VERSION ""

NS_ :

BS_:

BU_: BCM BSM DASM DIAG_TEST ESM ETM EVCU IPC LTM ORC SGW TBM

BO_ 599 AIRBAG1: 8 ORC
 SG_ AirBagFailSts : 7|2@0+ (1,0) [0|3] "-" IPC,TBM
 SG_ PsngrBagChargeSts : 5|2@0+ (1,0) [0|2] "-" IPC,TBM
 SG_ SBR1RowCentralSeatBuckleFailSts : 0|2@0+ (1,0) [0|2] "" IPC
 SG_ SBR1RowCentralSeatConfigSts : 1|1@0+ (1,0) [0|1] "-" IPC
 SG_ SBR1RowCentralSeatPPDFailSts : 14|2@0+ (1,0) [0|2] "" IPC
 SG_ SBR1RowCentralSeatSts : 12|3@0+ (1,0) [0|6] "-" IPC
 SG_ SBR1RowDriverSeatConfigSts : 9|1@0+ (1,0) [0|1] "-" IPC
 SG_ SBR1RowDriverSeatFailSts : 8|2@0+ (1,0) [0|2] "" EVCU,IPC
 SG_ SBR1RowDriverSeatSts : 22|2@0+ (1,0) [0|2] "-" EVCU,IPC,TBM
 SG_ SBR1RowPsngrSeatBuckleFailSts : 19|2@0+ (1,0) [0|2] "" IPC
 SG_ SBR1RowPsngrSeatConfigSts : 20|1@0+ (1,0) [0|1] "-" IPC
 SG_ SBR1RowPsngrSeatPPDFailSts : 17|2@0+ (1,0) [0|2] "" IPC
 SG_ SBR1RowPsngrSeatSts : 31|3@0+ (1,0) [0|6] "-" IPC,TBM
 SG_ SBR2RowCentralSeatConfigSts : 28|1@0+ (1,0) [0|1] "-" IPC
 SG_ SBR2RowCentralSeatSts : 25|2@0+ (1,0) [0|2] "-" IPC,TBM
 SG_ SBR2RowLeftSeatConfigSts : 39|1@0+ (1,0) [0|1] "-" IPC
 SG_ SBR2RowLeftSeatSts : 36|2@0+ (1,0) [0|2] "-" IPC,TBM
 SG_ SBR2RowRightSeatConfigSts : 34|1@0+ (1,0) [0|1] "-" IPC
 SG_ SBR2RowRightSeatSts : 47|2@0+ (1,0) [0|2] "-" IPC,TBM

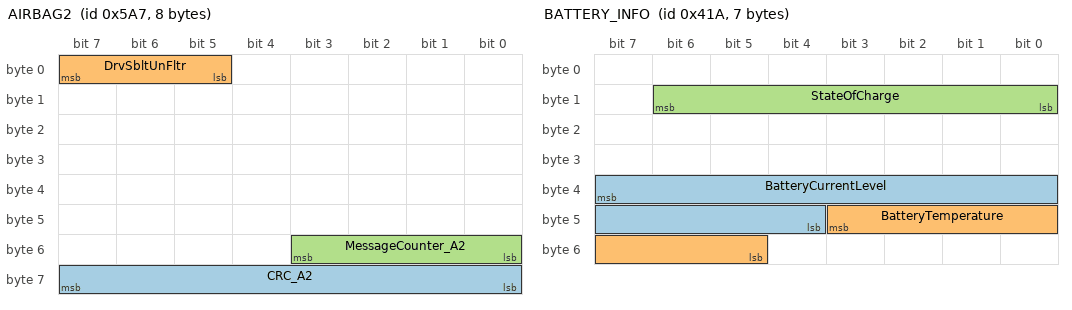
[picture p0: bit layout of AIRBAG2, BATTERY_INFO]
BO_ 1447 AIRBAG2: 8 ORC
 SG_ CRC_A2 : 63|8@0+ (1,0) [0|255] "" BSM
 SG_ DrvSbltUnFltr : 7|3@0+ (1,0) [0|6] "" BSM
 SG_ MessageCounter_A2 : 51|4@0+ (1,0) [0|15] "" BSM

BO_ 1050 BATTERY_INFO: 7 BCM
 SG_ BatteryCurrentLevel : 39|12@0+ (0.1,-250) [-250|159.5] "A" Vector__XXX
 SG_ BatteryTemperature : 43|7@0+ (1,-30) [-30|97] "°C" Vector__XXX
 SG_ StateOfCharge : 14|7@0+ (1,0) [0|127] "%" TBM

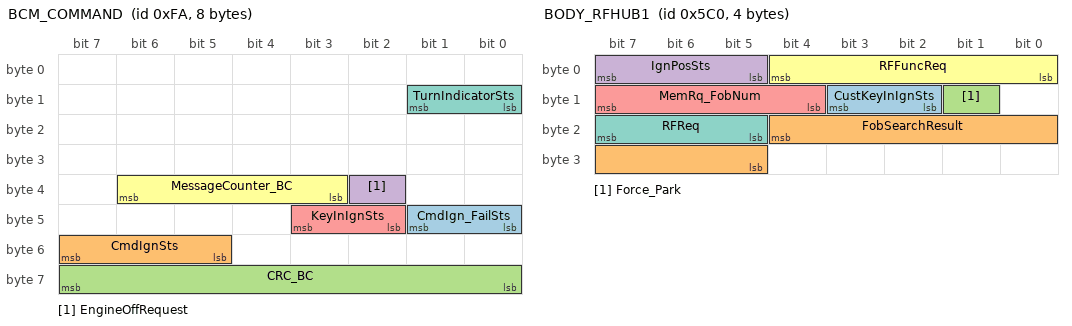
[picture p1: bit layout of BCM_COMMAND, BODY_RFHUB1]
BO_ 250 BCM_COMMAND: 8 BCM
 SG_ CmdIgn_FailSts : 41|2@0+ (1,0) [0|3] "-" BSM,DASM,ESM,EVCU,IPC
 SG_ CmdIgnSts : 55|3@0+ (1,0) [0|7] "-" BSM,DASM,ESM,EVCU,IPC
 SG_ CRC_BC : 63|8@0+ (1,0) [0|255] "" BSM,DASM,ESM,EVCU
 SG_ EngineOffRequest : 34|1@0+ (1,0) [0|1] "-" EVCU
 SG_ KeyInIgnSts : 43|2@0+ (1,0) [0|2] "" EVCU,TBM
 SG_ MessageCounter_BC : 38|4@0+ (1,0) [0|15] "-" BSM,DASM,ESM,EVCU
 SG_ TurnIndicatorSts : 9|2@0+ (1,0) [0|3] "-" IPC,TBM

BO_ 1994 BCM_IGNITION_ON_COUNTER: 2 BCM
 SG_ IgnitionOnCounter : 7|16@0+ (1,0) [0|65535] "-" DASM,ESM,EVCU,IPC,SGW,TBM

BO_ 1444 BH_IGW2: 8 BCM
 SG_ AirHtwPwrTgt : 11|8@0+ (1,0) [0|254] "%" EVCU
 SG_ PreCondCabinSts : 43|2@0+ (1,0) [0|3] "" EVCU

BO_ 1200 BH_IGW3: 8 BCM
 SG_ ChargeNow : 5|1@0+ (1,0) [0|1] "" EVCU
 SG_ ChargeNow_TBM : 58|1@0+ (1,0) [0|1] "" EVCU

BO_ 1472 BODY_RFHUB1: 4 BCM
 SG_ CustKeyInIgnSts : 11|2@0+ (1,0) [0|2] "" TBM
 SG_ FobSearchResult : 20|8@0+ (1,0) [0|255] "-" Vector__XXX
 SG_ Force_Park : 9|1@0+ (1,0) [0|1] "" EVCU
 SG_ IgnPosSts : 7|3@0+ (1,0) [0|6] "" TBM
 SG_ MemRq_FobNum : 15|4@0+ (1,0) [0|14] "" Vector__XXX
 SG_ RFFuncReq : 4|5@0+ (1,0) [0|30] "" TBM
 SG_ RFReq : 23|3@0+ (1,0) [0|6] "" TBM

BO_ 748 BODY1: 8 BCM
 SG_ AVASFailSts : 34|3@0+ (1,0) [0|7] "" IPC
 SG_ FrontWiperMoveSts : 21|1@0+ (1,0) [0|1] "" BSM,IPC,TBM

BO_ 1470 BODY10: 8 BCM
 SG_ LockUnlockVehicleSts : 5|3@0+ (1,0) [0|7] "" EVCU

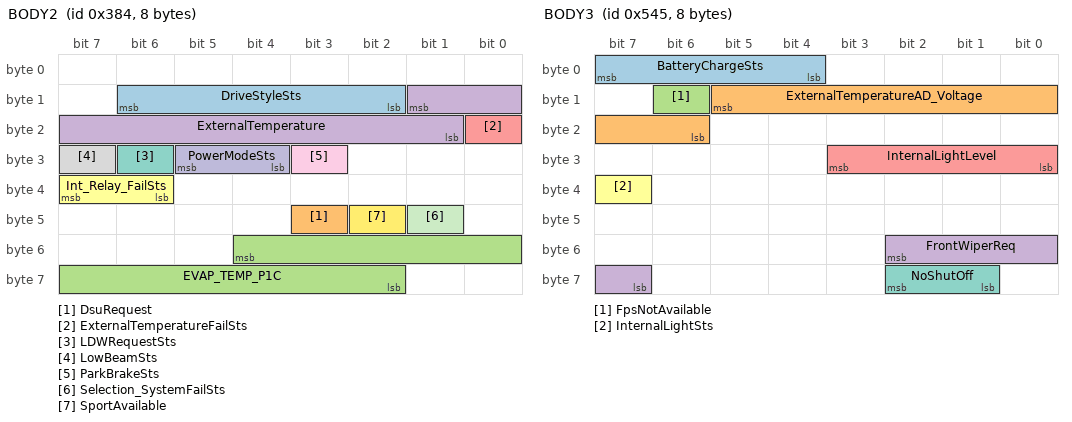
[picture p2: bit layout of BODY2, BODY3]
BO_ 900 BODY2: 8 BCM
 SG_ DriveStyleSts : 14|5@0+ (1,0) [0|31] "-" EVCU,IPC,TBM
 SG_ DsuRequest : 43|1@0+ (1,0) [0|1] "" IPC
 SG_ EVAP_TEMP_P1C : 52|11@0+ (0.1,-40) [-40|85] "°C" EVCU
 SG_ ExternalTemperature : 9|9@0+ (0.5,-85) [-85|170] "°C" BSM,DASM
 SG_ ExternalTemperatureFailSts : 16|1@0+ (1,0) [0|1] "" BSM,DASM
 SG_ Int_Relay_FailSts : 39|2@0+ (1,0) [0|2] "" Vector__XXX
 SG_ LDWRequestSts : 30|1@0+ (1,0) [0|1] "-" IPC
 SG_ LowBeamSts : 31|1@0+ (1,0) [0|1] "" TBM
 SG_ ParkBrakeSts : 27|1@0+ (1,0) [0|1] "-" EVCU,TBM
 SG_ PowerModeSts : 29|2@0+ (1,0) [0|3] "-" BSM,EVCU,IPC
 SG_ Selection_SystemFailSts : 41|1@0+ (1,0) [0|1] "" IPC
 SG_ SportAvailable : 42|1@0+ (1,0) [0|1] "" IPC

BO_ 1349 BODY3: 8 BCM
 SG_ BatteryChargeSts : 7|4@0+ (5,40) [40|110] "%" TBM
 SG_ ExternalTemperatureAD_Voltage : 13|8@0+ (0.019607843,0) [0|4.999999965] "Volt" EVCU
 SG_ FpsNotAvailable : 14|1@0+ (1,0) [0|1] "" Vector__XXX
 SG_ FrontWiperReq : 50|4@0+ (1,0) [0|5] "" IPC,TBM
 SG_ InternalLightLevel : 27|4@0+ (1,0) [0|15] "-" ESM,TBM
 SG_ InternalLightSts : 39|1@0+ (1,0) [0|1] "-" BSM,ESM,EVCU,IPC,ORC,TBM
 SG_ NoShutOff : 58|2@0+ (1,0) [0|2] "" IPC

BO_ 1201 BODY4: 8 BCM
 SG_ BonnetFailSts : 5|1@0+ (1,0) [0|1] "-" Vector__XXX
 SG_ BonnetSts : 4|1@0+ (1,0) [0|1] "" EVCU,TBM
 SG_ BrakeFluidLevelSts : 7|1@0+ (1,0) [0|1] "" IPC,TBM
 SG_ CompressorACReqSts : 37|1@0+ (1,0) [0|1] "-" EVCU
 SG_ DriverDoorFailSts : 3|1@0+ (1,0) [0|1] "-" BSM,EVCU
 SG_ DriverDoorSts : 0|1@0+ (1,0) [0|1] "" BSM,EVCU,IPC,TBM
 SG_ ExteriorRearReleaseSwitchSts : 33|1@0+ (1,0) [0|1] "" TBM
 SG_ FHeatedWindowLoadSts : 10|1@0+ (1,0) [0|1] "" Vector__XXX
 SG_ LHRDoorSts : 14|1@0+ (1,0) [0|1] "-" TBM
 SG_ PreCond_InhibitSts : 61|5@0+ (1,0) [0|30] "" IPC
 SG_ PreCondActvSts : 56|1@0+ (1,0) [0|1] "" IPC
 SG_ PsngrDoorSts : 15|1@0+ (1,0) [0|1] "-" TBM
 SG_ RemSt_InhibitSts : 19|6@0+ (1,0) [0|62] "" IPC,TBM
 SG_ RemStActvSts : 29|1@0+ (1,0) [0|1] "" EVCU,IPC,ORC
 SG_ RHatchSts : 12|1@0+ (1,0) [0|1] "-" TBM
 SG_ RHeatedWindowLoadSts : 11|1@0+ (1,0) [0|1] "" Vector__XXX
 SG_ RHRDoorSts : 13|1@0+ (1,0) [0|1] "-" TBM
 SG_ TheftAlarmStatus : 22|3@0+ (1,0) [0|6] "" TBM

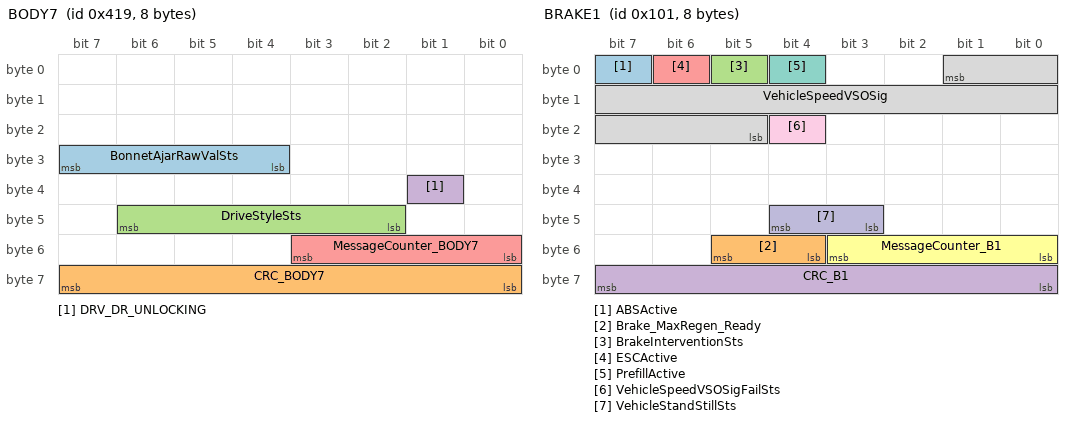
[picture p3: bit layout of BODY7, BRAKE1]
BO_ 1049 BODY7: 8 BCM
 SG_ BonnetAjarRawValSts : 31|4@0+ (1,0) [0|15] "" EVCU
 SG_ CRC_BODY7 : 63|8@0+ (1,0) [0|255] "" EVCU
 SG_ DriveStyleSts : 46|5@0+ (1,0) [0|31] "" EVCU
 SG_ DRV_DR_UNLOCKING : 33|1@0+ (1,0) [0|1] "-" EVCU
 SG_ MessageCounter_BODY7 : 51|4@0+ (1,0) [0|15] "" EVCU

BO_ 257 BRAKE1: 8 BSM
 SG_ ABSActive : 7|1@0+ (1,0) [0|1] "" DASM,EVCU,IPC,ORC,TBM
 SG_ Brake_MaxRegen_Ready : 53|2@0+ (1,0) [0|3] "" EVCU
 SG_ BrakeInterventionSts : 5|1@0+ (1,0) [0|1] "" ORC
 SG_ CRC_B1 : 63|8@0+ (1,0) [0|255] "" BCM,DASM,EVCU
 SG_ ESCActive : 6|1@0+ (1,0) [0|1] "" DASM,EVCU,IPC,ORC,TBM
 SG_ MessageCounter_B1 : 51|4@0+ (1,0) [0|15] "" BCM,DASM,EVCU
 SG_ PrefillActive : 4|1@0+ (1,0) [0|1] "" ORC
 SG_ VehicleSpeedVSOSig : 1|13@0+ (0.0625,0) [0|511.875] "Km/h" BCM,DASM,EVCU,IPC,ORC,TBM
 SG_ VehicleSpeedVSOSigFailSts : 20|1@0+ (1,0) [0|1] "" BCM,DASM,EVCU,IPC,ORC,TBM
 SG_ VehicleStandStillSts : 44|2@0+ (1,0) [0|2] "" Vector__XXX

BO_ 506 BRAKE10: 8 BSM
 SG_ BrkPdl_Stat : 26|2@0+ (1,0) [0|2] "" BCM,ETM,EVCU,IPC,LTM,TBM

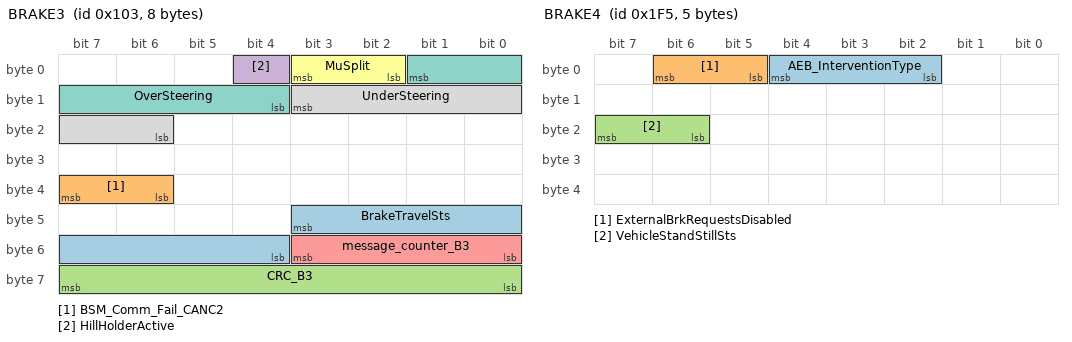
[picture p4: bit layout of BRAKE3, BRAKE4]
BO_ 259 BRAKE3: 8 BSM
 SG_ BrakeTravelSts : 43|8@0+ (0.4,0) [0|102] "%" DASM,EVCU,ORC
 SG_ BSM_Comm_Fail_CANC2 : 39|2@0+ (1,0) [0|3] "" EVCU
 SG_ CRC_B3 : 63|8@0+ (1,0) [0|255] "" DASM,EVCU
 SG_ HillHolderActive : 4|1@0+ (1,0) [0|1] "" ORC
 SG_ message_counter_B3 : 51|4@0+ (1,0) [0|15] "" DASM,EVCU
 SG_ MuSplit : 3|2@0+ (1,0) [0|2] "" Vector__XXX
 SG_ OverSteering : 1|6@0+ (2,0) [0|124] "%" Vector__XXX
 SG_ UnderSteering : 11|6@0+ (2,0) [0|124] "%" Vector__XXX

BO_ 501 BRAKE4: 5 BSM
 SG_ AEB_InterventionType : 4|3@0+ (1,0) [0|7] "" Vector__XXX
 SG_ ExternalBrkRequestsDisabled : 6|2@0+ (1,0) [0|2] "" Vector__XXX
 SG_ VehicleStandStillSts : 23|2@0+ (1,0) [0|2] "" EVCU

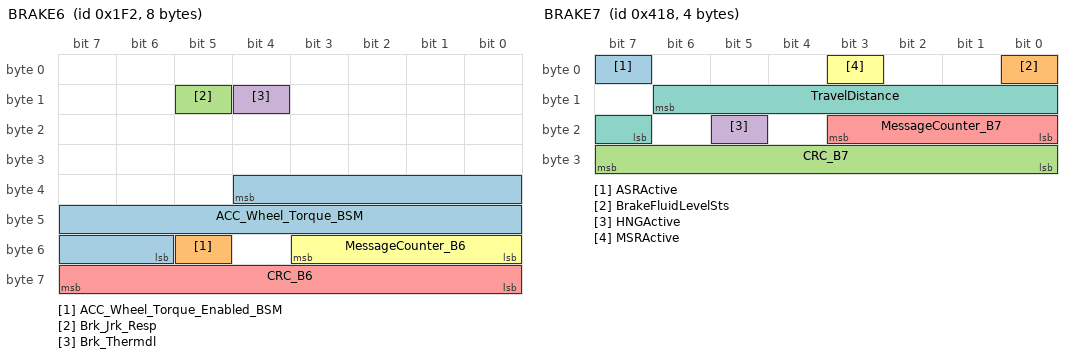
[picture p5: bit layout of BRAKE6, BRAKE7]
BO_ 498 BRAKE6: 8 BSM
 SG_ ACC_Wheel_Torque_BSM : 36|15@0+ (1,-7767) [-7767|24999] "" EVCU,ORC
 SG_ ACC_Wheel_Torque_Enabled_BSM : 53|1@0+ (1,0) [0|1] "-" EVCU,ORC
 SG_ Brk_Jrk_Resp : 13|1@0+ (1,0) [0|1] "-" Vector__XXX
 SG_ Brk_Thermdl : 12|1@0+ (1,0) [0|1] "" Vector__XXX
 SG_ CRC_B6 : 63|8@0+ (1,0) [0|255] "" DASM,EVCU
 SG_ MessageCounter_B6 : 51|4@0+ (1,0) [0|15] "" DASM,EVCU

BO_ 1048 BRAKE7: 4 BSM
 SG_ ASRActive : 7|1@0+ (1,0) [0|1] "-" DASM,EVCU,IPC,ORC,TBM
 SG_ BrakeFluidLevelSts : 0|1@0+ (1,0) [0|1] "-" BCM
 SG_ CRC_B7 : 31|8@0+ (1,0) [0|255] "" BCM,DASM,EVCU
 SG_ HNGActive : 21|1@0+ (1,0) [0|1] "-" IPC
 SG_ MessageCounter_B7 : 19|4@0+ (1,0) [0|15] "" BCM,DASM,EVCU
 SG_ MSRActive : 3|1@0+ (1,0) [0|1] "-" DASM,EVCU,ORC
 SG_ TravelDistance : 14|8@0+ (1,0) [0|255] "m" ETM,IPC,LTM

BO_ 1199 BRAKE8: 8 BSM
 SG_ ABSFailSts : 7|1@0+ (1,0) [0|1] "-" EVCU,IPC,ORC,TBM
 SG_ BSM_BLC_Active : 26|1@0+ (1,0) [0|1] "" BCM
 SG_ BSMSysSts : 47|2@0+ (1,0) [0|3] "" Vector__XXX
 SG_ CMMIntervention : 6|1@0+ (1,0) [0|1] "-" EVCU
 SG_ EBDFailSts : 4|1@0+ (1,0) [0|1] "-" IPC,ORC,TBM
 SG_ ERMActive : 33|1@0+ (1,0) [0|1] "" ORC
 SG_ ESCFailSts : 2|1@0+ (1,0) [0|1] "-" DASM,EVCU,IPC,ORC,TBM
 SG_ ESCIntervention : 3|1@0+ (1,0) [0|1] "-" IPC,ORC,TBM
 SG_ Function2Sts : 10|1@0+ (1,0) [0|1] "-" IPC,TBM
 SG_ FunctionFailSts : 15|1@0+ (1,0) [0|1] "-" IPC
 SG_ FunctionIntervention : 1|1@0+ (1,0) [0|1] "-" IPC,ORC
 SG_ FunctionSts : 0|1@0+ (1,0) [0|1] "-" DASM,EVCU,IPC,ORC,TBM
 SG_ HillHolderFailSts : 14|1@0+ (1,0) [0|1] "-" IPC,ORC,TBM
 SG_ RollsModeAct : 12|1@0+ (1,0) [0|1] "" EVCU
 SG_ TPMActivitySts : 13|1@0+ (1,0) [0|1] "" IPC,ORC
 SG_ TSCActive : 32|1@0+ (1,0) [0|1] "" ORC
 SG_ TyreInflationState_LHF_Tyre : 20|2@0+ (1,0) [0|3] "" BCM,IPC,ORC,TBM
 SG_ TyreInflationState_LHR_Tyre : 18|2@0+ (1,0) [0|3] "" BCM,IPC,ORC,TBM
 SG_ TyreInflationState_RHF_Tyre : 16|2@0+ (1,0) [0|3] "" BCM,IPC,ORC,TBM
 SG_ TyreInflationState_RHR_Tyre : 30|2@0+ (1,0) [0|3] "" BCM,IPC,ORC,TBM
 SG_ TyrePressureSystemFailSts : 28|1@0+ (1,0) [0|1] "" BCM,IPC,ORC,TBM

BO_ 1453 BRAKE9: 8 BSM
 SG_ PowerModeSts_BSM : 20|2@0+ (1,0) [0|3] "-" BCM

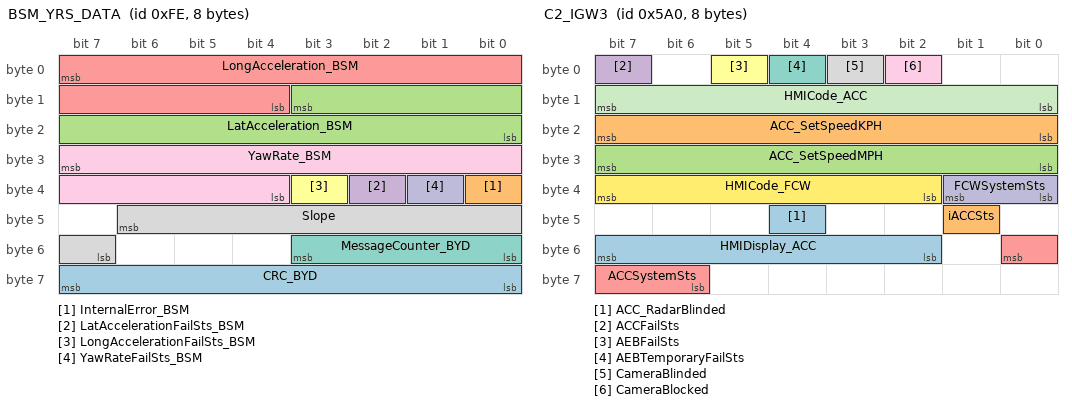
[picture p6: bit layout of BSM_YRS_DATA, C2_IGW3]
BO_ 254 BSM_YRS_DATA: 8 BSM
 SG_ CRC_BYD : 63|8@0+ (1,0) [0|255] "-" BCM,DASM,EVCU
 SG_ InternalError_BSM : 32|1@0+ (1,0) [0|1] "-" Vector__XXX
 SG_ LatAcceleration_BSM : 11|12@0+ (0.02,-40.96) [-40.96|40.92] "m/s^2" BCM,EVCU,TBM
 SG_ LatAccelerationFailSts_BSM : 34|1@0+ (1,0) [0|1] "-" BCM,TBM
 SG_ LongAcceleration_BSM : 7|12@0+ (0.02,-40.96) [-40.96|40.92] "m/s^2" BCM,DASM,EVCU,IPC,TBM
 SG_ LongAccelerationFailSts_BSM : 35|1@0+ (1,0) [0|1] "-" BCM,DASM,TBM
 SG_ MessageCounter_BYD : 51|4@0+ (1,0) [0|15] "-" BCM,DASM,EVCU
 SG_ Slope : 46|8@0+ (1,-100) [-100|154] "%" ETM,LTM
 SG_ YawRate_BSM : 31|12@0+ (0.08,-163.84) [-163.84|163.68] "deg/s" BCM,DASM,ORC,TBM
 SG_ YawRateFailSts_BSM : 33|1@0+ (1,0) [0|1] "-" BCM,DASM

BO_ 1440 C2_IGW3: 8 BCM
 SG_ ACC_RadarBlinded : 44|1@0+ (1,0) [0|1] "" IPC
 SG_ ACC_SetSpeedKPH : 23|8@0+ (1,0) [0|255] "kph" IPC
 SG_ ACC_SetSpeedMPH : 31|8@0+ (1,0) [0|255] "mph" IPC
 SG_ ACCFailSts : 7|1@0+ (1,0) [0|1] "" IPC,TBM
 SG_ ACCSystemSts : 48|3@0+ (1,0) [0|7] "" IPC,TBM
 SG_ AEBFailSts : 5|1@0+ (1,0) [0|1] "" IPC
 SG_ AEBTemporaryFailSts : 4|1@0+ (1,0) [0|1] "" IPC
 SG_ CameraBlinded : 3|1@0+ (1,0) [0|1] "" IPC
 SG_ CameraBlocked : 2|1@0+ (1,0) [0|1] "" IPC
 SG_ FCWSystemSts : 33|2@0+ (1,0) [0|3] "" IPC,TBM
 SG_ HMICode_ACC : 15|8@0+ (1,0) [0|255] "" IPC
 SG_ HMICode_FCW : 39|6@0+ (1,0) [0|63] "" IPC,TBM
 SG_ HMIDisplay_ACC : 55|6@0+ (1,0) [0|63] "" IPC
 SG_ iACCSts : 41|1@0+ (1,0) [0|1] "" IPC

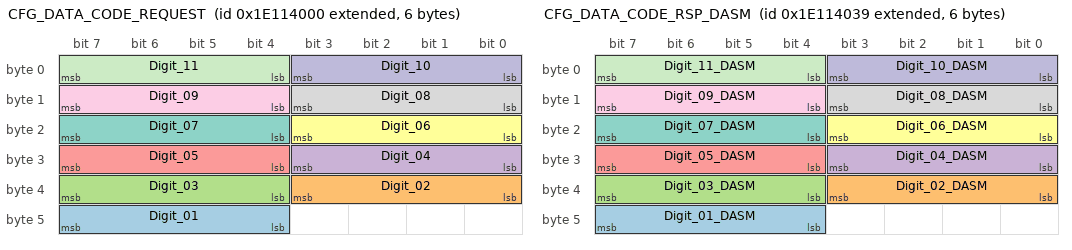
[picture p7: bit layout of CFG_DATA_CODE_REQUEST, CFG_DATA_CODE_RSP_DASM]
BO_ 2651930624 CFG_DATA_CODE_REQUEST: 6 BCM
 SG_ Digit_01 : 47|4@0+ (1,0) [0|15] "" BSM,DASM,EVCU,IPC,TBM
 SG_ Digit_02 : 35|4@0+ (1,0) [0|15] "" BSM,DASM,EVCU,IPC,TBM
 SG_ Digit_03 : 39|4@0+ (1,0) [0|15] "" BSM,DASM,EVCU,IPC,TBM
 SG_ Digit_04 : 27|4@0+ (1,0) [0|15] "" BSM,DASM,EVCU,IPC,TBM
 SG_ Digit_05 : 31|4@0+ (1,0) [0|15] "" BSM,DASM,EVCU,IPC,TBM
 SG_ Digit_06 : 19|4@0+ (1,0) [0|15] "" BSM,DASM,EVCU,IPC,TBM
 SG_ Digit_07 : 23|4@0+ (1,0) [0|15] "" BSM,DASM,EVCU,IPC,TBM
 SG_ Digit_08 : 11|4@0+ (1,0) [0|15] "" BSM,DASM,EVCU,IPC,TBM
 SG_ Digit_09 : 15|4@0+ (1,0) [0|15] "" BSM,DASM,EVCU,IPC,TBM
 SG_ Digit_10 : 3|4@0+ (1,0) [0|15] "" BSM,DASM,EVCU,IPC,TBM
 SG_ Digit_11 : 7|4@0+ (1,0) [0|15] "" BSM,DASM,EVCU,IPC,TBM

BO_ 2651930681 CFG_DATA_CODE_RSP_DASM: 6 DASM
 SG_ Digit_01_DASM : 47|4@0+ (1,0) [0|15] "-" BCM
 SG_ Digit_02_DASM : 35|4@0+ (1,0) [0|15] "-" BCM
 SG_ Digit_03_DASM : 39|4@0+ (1,0) [0|15] "-" BCM
 SG_ Digit_04_DASM : 27|4@0+ (1,0) [0|15] "-" BCM
 SG_ Digit_05_DASM : 31|4@0+ (1,0) [0|15] "-" BCM
 SG_ Digit_06_DASM : 19|4@0+ (1,0) [0|15] "-" BCM
 SG_ Digit_07_DASM : 23|4@0+ (1,0) [0|15] "-" BCM
 SG_ Digit_08_DASM : 11|4@0+ (1,0) [0|15] "-" BCM
 SG_ Digit_09_DASM : 15|4@0+ (1,0) [0|15] "-" BCM
 SG_ Digit_10_DASM : 3|4@0+ (1,0) [0|15] "-" BCM
 SG_ Digit_11_DASM : 7|4@0+ (1,0) [0|15] "-" BCM

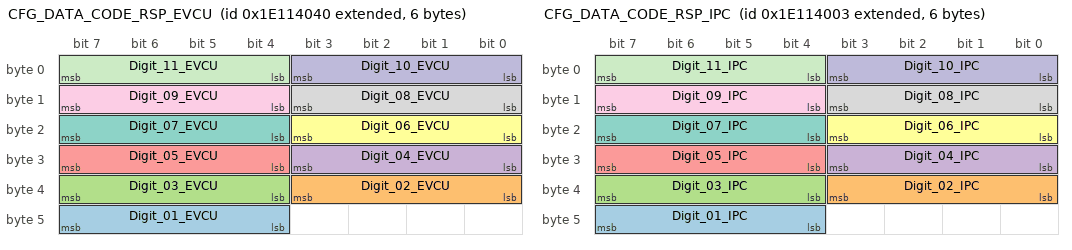
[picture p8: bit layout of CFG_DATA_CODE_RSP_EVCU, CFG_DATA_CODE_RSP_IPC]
BO_ 2651930688 CFG_DATA_CODE_RSP_EVCU: 6 EVCU
 SG_ Digit_01_EVCU : 47|4@0+ (1,0) [0|15] "-" BCM
 SG_ Digit_02_EVCU : 35|4@0+ (1,0) [0|15] "-" BCM
 SG_ Digit_03_EVCU : 39|4@0+ (1,0) [0|15] "-" BCM
 SG_ Digit_04_EVCU : 27|4@0+ (1,0) [0|15] "-" BCM
 SG_ Digit_05_EVCU : 31|4@0+ (1,0) [0|15] "-" BCM
 SG_ Digit_06_EVCU : 19|4@0+ (1,0) [0|15] "-" BCM
 SG_ Digit_07_EVCU : 23|4@0+ (1,0) [0|15] "-" BCM
 SG_ Digit_08_EVCU : 11|4@0+ (1,0) [0|15] "-" BCM
 SG_ Digit_09_EVCU : 15|4@0+ (1,0) [0|15] "-" BCM
 SG_ Digit_10_EVCU : 3|4@0+ (1,0) [0|15] "-" BCM
 SG_ Digit_11_EVCU : 7|4@0+ (1,0) [0|15] "-" BCM

BO_ 2651930627 CFG_DATA_CODE_RSP_IPC: 6 IPC
 SG_ Digit_01_IPC : 47|4@0+ (1,0) [0|15] "-" BCM
 SG_ Digit_02_IPC : 35|4@0+ (1,0) [0|15] "-" BCM
 SG_ Digit_03_IPC : 39|4@0+ (1,0) [0|15] "-" BCM
 SG_ Digit_04_IPC : 27|4@0+ (1,0) [0|15] "-" BCM
 SG_ Digit_05_IPC : 31|4@0+ (1,0) [0|15] "-" BCM
 SG_ Digit_06_IPC : 19|4@0+ (1,0) [0|15] "-" BCM
 SG_ Digit_07_IPC : 23|4@0+ (1,0) [0|15] "-" BCM
 SG_ Digit_08_IPC : 11|4@0+ (1,0) [0|15] "-" BCM
 SG_ Digit_09_IPC : 15|4@0+ (1,0) [0|15] "-" BCM
 SG_ Digit_10_IPC : 3|4@0+ (1,0) [0|15] "-" BCM
 SG_ Digit_11_IPC : 7|4@0+ (1,0) [0|15] "-" BCM

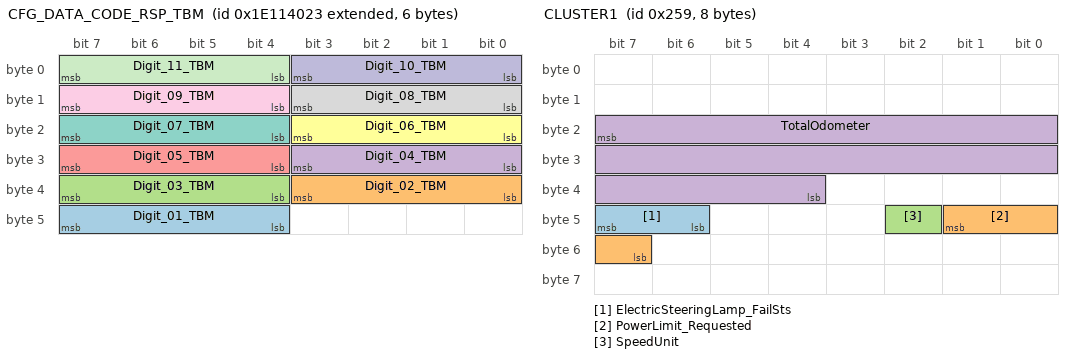
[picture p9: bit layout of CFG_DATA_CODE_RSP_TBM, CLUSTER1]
BO_ 2651930659 CFG_DATA_CODE_RSP_TBM: 6 TBM
 SG_ Digit_01_TBM : 47|4@0+ (1,0) [0|15] "-" BCM
 SG_ Digit_02_TBM : 35|4@0+ (1,0) [0|15] "-" BCM
 SG_ Digit_03_TBM : 39|4@0+ (1,0) [0|15] "-" BCM
 SG_ Digit_04_TBM : 27|4@0+ (1,0) [0|15] "-" BCM
 SG_ Digit_05_TBM : 31|4@0+ (1,0) [0|15] "-" BCM
 SG_ Digit_06_TBM : 19|4@0+ (1,0) [0|15] "-" BCM
 SG_ Digit_07_TBM : 23|4@0+ (1,0) [0|15] "-" BCM
 SG_ Digit_08_TBM : 11|4@0+ (1,0) [0|15] "-" BCM
 SG_ Digit_09_TBM : 15|4@0+ (1,0) [0|15] "-" BCM
 SG_ Digit_10_TBM : 3|4@0+ (1,0) [0|15] "-" BCM
 SG_ Digit_11_TBM : 7|4@0+ (1,0) [0|15] "-" BCM

BO_ 601 CLUSTER1: 8 IPC
 SG_ ElectricSteeringLamp_FailSts : 47|2@0+ (1,0) [0|3] "-" BCM,ORC
 SG_ PowerLimit_Requested : 41|3@0+ (1,0) [0|6] "" EVCU
 SG_ SpeedUnit : 42|1@0+ (1,0) [0|1] "" BCM,EVCU
 SG_ TotalOdometer : 23|20@0+ (1,0) [0|1048575] "km" BCM,BSM,DASM,ESM,EVCU,ORC

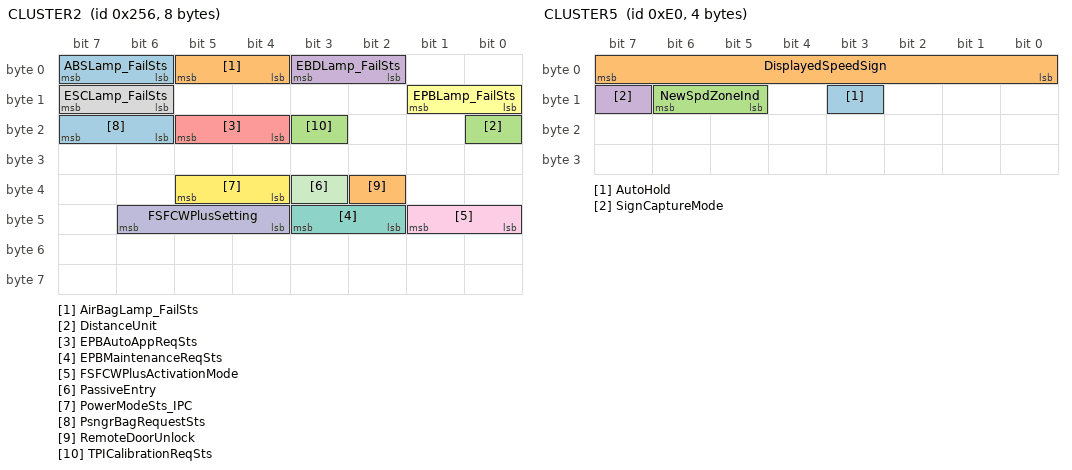
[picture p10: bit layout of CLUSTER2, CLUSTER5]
BO_ 598 CLUSTER2: 8 IPC
 SG_ ABSLamp_FailSts : 7|2@0+ (1,0) [0|3] "-" BSM
 SG_ AirBagLamp_FailSts : 5|2@0+ (1,0) [0|3] "-" ORC,TBM
 SG_ DistanceUnit : 16|1@0+ (1,0) [0|1] "" TBM
 SG_ EBDLamp_FailSts : 3|2@0+ (1,0) [0|3] "-" BSM
 SG_ EPBAutoAppReqSts : 21|2@0+ (1,0) [0|3] "" BSM
 SG_ EPBLamp_FailSts : 9|2@0+ (1,0) [0|3] "" BSM
 SG_ EPBMaintenanceReqSts : 43|2@0+ (1,0) [0|3] "-" BSM
 SG_ ESCLamp_FailSts : 15|2@0+ (1,0) [0|3] "-" BSM
 SG_ FSFCWPlusActivationMode : 41|2@0+ (1,0) [0|3] "-" BCM
 SG_ FSFCWPlusSetting : 46|3@0+ (1,0) [0|7] "-" BCM
 SG_ PassiveEntry : 35|1@0+ (1,0) [0|1] "" Vector__XXX
 SG_ PowerModeSts_IPC : 37|2@0+ (1,0) [0|3] "" BCM
 SG_ PsngrBagRequestSts : 23|2@0+ (1,0) [0|3] "-" ORC
 SG_ RemoteDoorUnlock : 34|1@0+ (1,0) [0|1] "" Vector__XXX
 SG_ TPICalibrationReqSts : 19|1@0+ (1,0) [0|1] "" BSM

BO_ 224 CLUSTER5: 4 IPC
 SG_ AutoHold : 11|1@0+ (1,0) [0|1] "-" BSM
 SG_ DisplayedSpeedSign : 7|8@0+ (1,0) [0|255] "-" BCM,EVCU
 SG_ NewSpdZoneInd : 14|2@0+ (1,0) [0|3] "-" Vector__XXX
 SG_ SignCaptureMode : 15|1@0+ (1,0) [0|1] "-" BCM,EVCU

BO_ 2564554481 DIAGNOSTIC_REQ_FUNC_C1: 8 DIAG_TEST
 SG_ N_PDU : 7|64@0+ (1,0) [0|0] "" BCM,DASM,ESM,EVCU,IPC,SGW,TBM

BO_ 2564440305 DIAGNOSTIC_REQUEST_BCM: 8 DIAG_TEST
 SG_ N_PDU : 7|64@0+ (1,0) [0|0] "" BCM,TBM

BO_ 2564441329 DIAGNOSTIC_REQUEST_BPCM: 8 DIAG_TEST
 SG_ N_PDU : 7|64@0+ (1,0) [0|0] "" EVCU,TBM

BO_ 2564434161 DIAGNOSTIC_REQUEST_BSM: 8 BCM
 SG_ N_PDU : 7|64@0+ (1,0) [0|0] "" BCM,TBM

BO_ 2564434673 DIAGNOSTIC_REQUEST_DASM: 8 DIAG_TEST
 SG_ N_PDU : 7|64@0+ (1,0) [0|0] "" DASM,TBM

BO_ 2564436209 DIAGNOSTIC_REQUEST_EPS: 8 BCM
 SG_ N_PDU : 7|64@0+ (1,0) [0|0] "" BCM,TBM

BO_ 2564440817 DIAGNOSTIC_REQUEST_EVCU: 8 DIAG_TEST
 SG_ N_PDU : 7|64@0+ (1,0) [0|0] "" EVCU,TBM

BO_ 2564502513 DIAGNOSTIC_REQUEST_FUNC_OBD: 8 DIAG_TEST
 SG_ N_PDU : 7|64@0+ (1,0) [0|0] "" BSM,EVCU

BO_ 2564436465 DIAGNOSTIC_REQUEST_HALF: 8 BCM
 SG_ N_PDU : 7|64@0+ (1,0) [0|0] "" BCM,TBM

BO_ 2564444401 DIAGNOSTIC_REQUEST_IDCM: 8 DIAG_TEST
 SG_ N_PDU : 7|64@0+ (1,0) [0|0] "" EVCU,TBM

BO_ 2564448497 DIAGNOSTIC_REQUEST_IPC: 8 DIAG_TEST
 SG_ N_PDU : 7|64@0+ (1,0) [0|0] "-" IPC,TBM

BO_ 2564473073 DIAGNOSTIC_REQUEST_ORC: 8 BCM
 SG_ N_PDU : 7|64@0+ (1,0) [0|0] "" BCM,TBM

BO_ 2564464881 DIAGNOSTIC_REQUEST_PAM: 8 BCM
 SG_ N_PDU : 7|64@0+ (1,0) [0|0] "" BCM,TBM

BO_ 2564444145 DIAGNOSTIC_REQUEST_RCU: 8 DIAG_TEST
 SG_ N_PDU : 7|64@0+ (1,0) [0|0] "" BCM

BO_ 2564475889 DIAGNOSTIC_REQUEST_SGW: 8 DIAG_TEST
 SG_ N_PDU : 7|64@0+ (1,0) [0|0] "" SGW,TBM

BO_ 2564431857 DIAGNOSTIC_REQUEST_SHIFTER: 8 DIAG_TEST
 SG_ N_PDU : 7|64@0+ (1,0) [0|0] "" ESM,TBM

BO_ 2564474609 DIAGNOSTIC_REQUEST_TBM: 8 DIAG_TEST
 SG_ N_PDU : 7|64@0+ (1,0) [0|0] "-" TBM

BO_ 2564445937 DIAGNOSTIC_REQUEST_WSMD: 8 DIAG_TEST
 SG_ N_PDU : 7|64@0+ (1,0) [0|0] "" BCM

BO_ 2564446193 DIAGNOSTIC_REQUEST_WSMP: 8 DIAG_TEST
 SG_ N_PDU : 7|64@0+ (1,0) [0|0] "" BCM

BO_ 2564485440 DIAGNOSTIC_RESPONSE_BCM: 8 BCM
 SG_ N_PDU : 7|64@0+ (1,0) [0|0] "" DIAG_TEST,TBM

BO_ 2564485444 DIAGNOSTIC_RESPONSE_BPCM: 8 EVCU
 SG_ N_PDU : 7|64@0+ (1,0) [0|0] "" DIAG_TEST,TBM

BO_ 2564485418 DIAGNOSTIC_RESPONSE_DASM: 8 DASM
 SG_ N_PDU : 7|64@0+ (1,0) [0|0] "" DIAG_TEST,TBM

BO_ 2564485442 DIAGNOSTIC_RESPONSE_EVCU: 8 EVCU
 SG_ N_PDU : 7|64@0+ (1,0) [0|0] "" DIAG_TEST,TBM

BO_ 2564485456 DIAGNOSTIC_RESPONSE_IDCM: 8 EVCU
 SG_ N_PDU : 7|64@0+ (1,0) [0|0] "" DIAG_TEST,TBM

BO_ 2564485472 DIAGNOSTIC_RESPONSE_IPC: 8 IPC
 SG_ N_PDU : 7|64@0+ (1,0) [0|0] "-" DIAG_TEST,TBM

BO_ 2564485455 DIAGNOSTIC_RESPONSE_RCU: 8 BCM
 SG_ N_PDU : 7|64@0+ (1,0) [0|0] "" DIAG_TEST

BO_ 2564485579 DIAGNOSTIC_RESPONSE_SGW: 8 SGW
 SG_ N_PDU : 7|64@0+ (1,0) [0|0] "" DIAG_TEST,TBM

BO_ 2564485407 DIAGNOSTIC_RESPONSE_SHIFTER: 8 ESM
 SG_ N_PDU : 7|64@0+ (1,0) [0|0] "" DIAG_TEST,TBM

BO_ 2564485672 DIAGNOSTIC_RESPONSE_SQDF_BSM: 8 BCM
 SG_ N_PDU : 7|64@0+ (1,0) [0|0] "" TBM

BO_ 2564485680 DIAGNOSTIC_RESPONSE_SQDF_EPS: 8 BCM
 SG_ N_PDU : 7|64@0+ (1,0) [0|0] "" TBM

BO_ 2564485681 DIAGNOSTIC_RESPONSE_SQDF_HALF: 8 BCM
 SG_ N_PDU : 7|64@0+ (1,0) [0|0] "" TBM

BO_ 2564485824 DIAGNOSTIC_RESPONSE_SQDF_ORC: 8 BCM
 SG_ N_PDU : 7|64@0+ (1,0) [0|0] "" TBM

BO_ 2564485792 DIAGNOSTIC_RESPONSE_SQDF_PAM: 8 BCM
 SG_ N_PDU : 7|64@0+ (1,0) [0|0] "" TBM

BO_ 2564485574 DIAGNOSTIC_RESPONSE_TBM: 8 TBM
 SG_ N_PDU : 7|64@0+ (1,0) [0|0] "-" DIAG_TEST

BO_ 2564485462 DIAGNOSTIC_RESPONSE_WSMD: 8 BCM
 SG_ N_PDU : 7|64@0+ (1,0) [0|0] "" DIAG_TEST

BO_ 2564485463 DIAGNOSTIC_RESPONSE_WSMP: 8 BCM
 SG_ N_PDU : 7|64@0+ (1,0) [0|0] "" DIAG_TEST

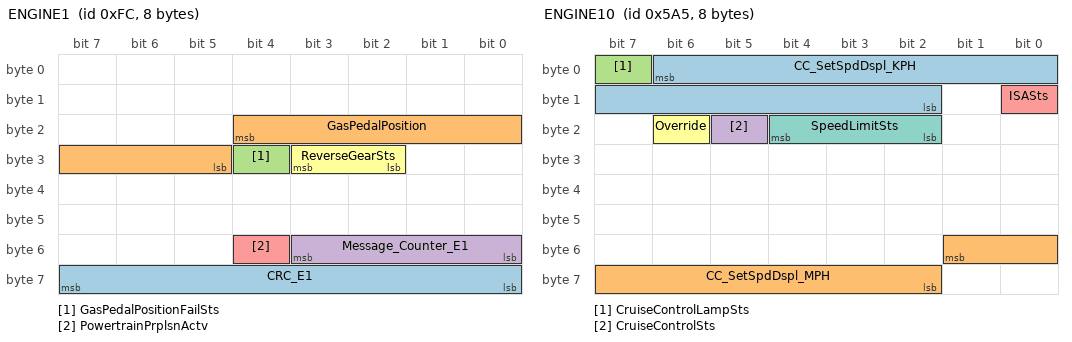
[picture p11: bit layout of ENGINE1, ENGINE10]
BO_ 252 ENGINE1: 8 EVCU
 SG_ CRC_E1 : 63|8@0+ (1,0) [0|255] "" BCM,BSM,DASM
 SG_ GasPedalPosition : 20|8@0+ (0.392,0) [0|99.568] "%" BSM,ETM,IPC,LTM,ORC,TBM
 SG_ GasPedalPositionFailSts : 28|1@0+ (1,0) [0|1] "-" BSM,ETM,LTM,ORC,TBM
 SG_ Message_Counter_E1 : 51|4@0+ (1,0) [0|15] "" BCM,BSM,DASM
 SG_ PowertrainPrplsnActv : 52|1@0+ (1,0) [0|1] "-" BCM,BSM,DASM,ESM,ETM,IPC,LTM,ORC
 SG_ ReverseGearSts : 27|2@0+ (1,0) [0|3] "-" BCM,IPC,ORC,TBM

BO_ 1445 ENGINE10: 8 EVCU
 SG_ CC_SetSpdDspl_KPH : 6|13@0+ (0.0625,0) [0|511.875] "kph" IPC,TBM
 SG_ CC_SetSpdDspl_MPH : 49|8@0+ (1,0) [0|255] "mph" IPC,TBM
 SG_ CruiseControlLampSts : 7|1@0+ (1,0) [0|1] "-" IPC,ORC,TBM
 SG_ CruiseControlSts : 21|1@0+ (1,0) [0|1] "-" IPC,TBM
 SG_ ISASts : 8|1@0+ (1,0) [0|1] "" IPC
 SG_ Override : 22|1@0+ (1,0) [0|1] "-" IPC,ORC
 SG_ SpeedLimitSts : 20|3@0+ (1,0) [0|7] "-" IPC

BO_ 496 ENGINE5: 8 EVCU
 SG_ ActualPedalPos : 4|8@0+ (0.4,0) [0|100] "%" ORC,TBM

BO_ 550 ENGINE9: 8 EVCU
 SG_ ECM_WARN : 54|5@0+ (1,0) [0|31] "" IPC

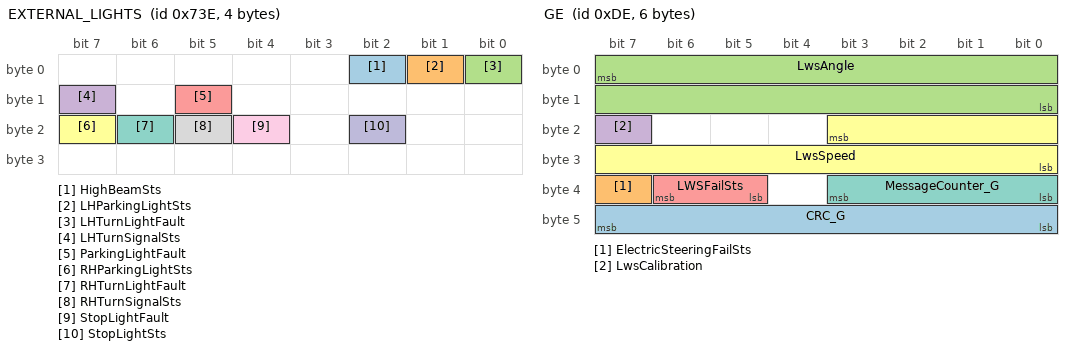
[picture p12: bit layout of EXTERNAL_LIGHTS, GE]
BO_ 1854 EXTERNAL_LIGHTS: 4 BCM
 SG_ HighBeamSts : 2|1@0+ (1,0) [0|1] "-" ORC,TBM
 SG_ LHParkingLightSts : 1|1@0+ (1,0) [0|1] "-" ORC
 SG_ LHTurnLightFault : 0|1@0+ (1,0) [0|1] "-" ORC
 SG_ LHTurnSignalSts : 15|1@0+ (1,0) [0|1] "-" ORC
 SG_ ParkingLightFault : 13|1@0+ (1,0) [0|1] "-" ORC
 SG_ RHParkingLightSts : 23|1@0+ (1,0) [0|1] "-" ORC
 SG_ RHTurnLightFault : 22|1@0+ (1,0) [0|1] "-" ORC
 SG_ RHTurnSignalSts : 21|1@0+ (1,0) [0|1] "-" ORC
 SG_ StopLightFault : 20|1@0+ (1,0) [0|1] "-" ORC
 SG_ StopLightSts : 18|1@0+ (1,0) [0|1] "-" BSM,ORC

BO_ 222 GE: 6 BCM
 SG_ CRC_G : 47|8@0+ (1,0) [0|255] "-" DASM,EVCU
 SG_ ElectricSteeringFailSts : 39|1@0+ (1,0) [0|1] "" IPC,TBM
 SG_ LwsAngle : 7|16@0+ (0.1,-720) [-720|720] "°" DASM,ETM,IPC,LTM,TBM
 SG_ LwsCalibration : 23|1@0+ (1,0) [0|1] "-" TBM
 SG_ LWSFailSts : 38|2@0+ (1,0) [0|3] "-" DASM
 SG_ LwsSpeed : 19|12@0+ (1,-2000) [-2000|2094] "°/s" DASM
 SG_ MessageCounter_G : 35|4@0+ (1,0) [0|15] "1" DASM,EVCU

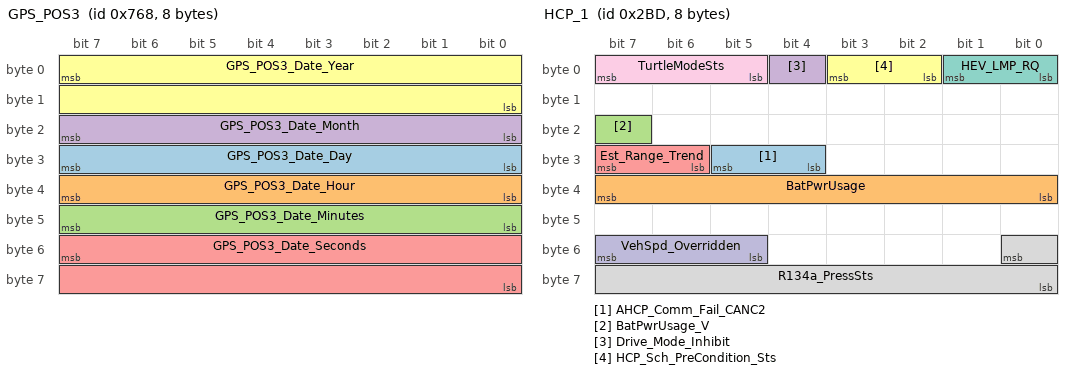
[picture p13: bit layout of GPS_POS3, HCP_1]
BO_ 1896 GPS_POS3: 8 BCM
 SG_ GPS_POS3_Date_Day : 31|8@0+ (1,0) [1|31] "days" EVCU
 SG_ GPS_POS3_Date_Hour : 39|8@0+ (1,0) [0|23] "hours" EVCU
 SG_ GPS_POS3_Date_Minutes : 47|8@0+ (1,0) [0|59] "minutes" EVCU
 SG_ GPS_POS3_Date_Month : 23|8@0+ (1,0) [1|12] "months" EVCU
 SG_ GPS_POS3_Date_Seconds : 55|16@0+ (0.01,0) [0|59.99] "seconds" EVCU
 SG_ GPS_POS3_Date_Year : 7|16@0+ (1,0) [0|65534] "years" EVCU

BO_ 701 HCP_1: 8 EVCU
 SG_ AHCP_Comm_Fail_CANC2 : 29|2@0+ (1,0) [0|3] "" BSM
 SG_ BatPwrUsage : 39|8@0+ (1,-125) [-125|130] "kW" IPC,TBM
 SG_ BatPwrUsage_V : 23|1@0+ (1,0) [0|1] "" IPC,TBM
 SG_ Drive_Mode_Inhibit : 4|1@0+ (1,0) [0|1] "" BCM
 SG_ Est_Range_Trend : 31|2@0+ (1,0) [0|3] "" IPC,TBM
 SG_ HCP_Sch_PreCondition_Sts : 3|2@0+ (1,0) [0|3] "" BCM
 SG_ HEV_LMP_RQ : 1|2@0+ (1,0) [0|3] "" IPC,ORC,TBM
 SG_ R134a_PressSts : 48|9@0+ (0.1,0) [0|40] "bar" BCM
 SG_ TurtleModeSts : 7|3@0+ (1,0) [0|6] "" BCM,IPC,TBM
 SG_ VehSpd_Overridden : 55|3@0+ (1,0) [0|7] "" IPC

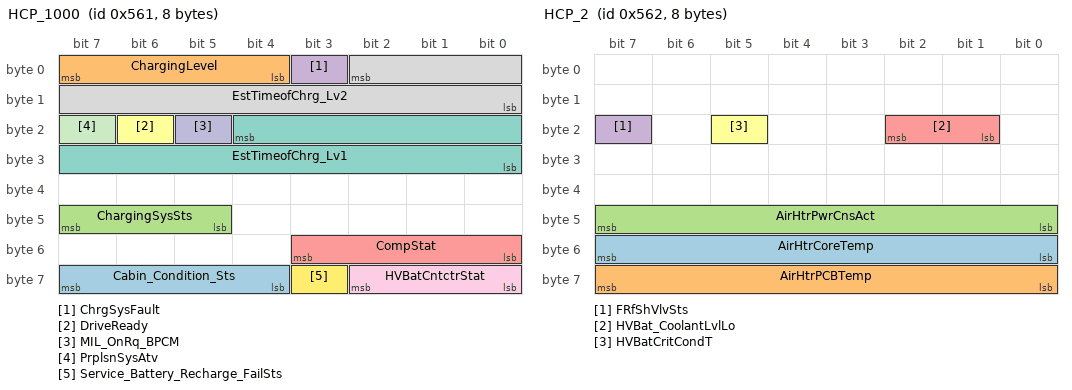
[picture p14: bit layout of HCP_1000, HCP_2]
BO_ 1377 HCP_1000: 8 EVCU
 SG_ Cabin_Condition_Sts : 63|4@0+ (1,0) [0|14] "" BCM
 SG_ ChargingLevel : 7|4@0+ (1,0) [0|14] "" BCM,ETM,IPC,LTM,TBM
 SG_ ChargingSysSts : 47|3@0+ (1,0) [0|6] "" BCM,ETM,IPC,LTM,TBM
 SG_ ChrgSysFault : 3|1@0+ (1,0) [0|1] "" BCM,ETM,IPC,TBM
 SG_ CompStat : 51|4@0+ (1,0) [0|15] "-" BCM,TBM
 SG_ DriveReady : 22|1@0+ (1,0) [0|1] "" IPC,TBM
 SG_ EstTimeofChrg_Lv1 : 20|13@0+ (1,0) [0|8190] "min" ETM,IPC,LTM,TBM
 SG_ EstTimeofChrg_Lv2 : 2|11@0+ (1,0) [0|2046] "min" ETM,IPC,LTM,TBM
 SG_ HVBatCntctrStat : 58|3@0+ (1,0) [0|6] "" IPC,ORC,TBM
 SG_ MIL_OnRq_BPCM : 21|1@0+ (1,0) [0|1] "" IPC,TBM
 SG_ PrplsnSysAtv : 23|1@0+ (1,0) [0|1] "-" TBM
 SG_ Service_Battery_Recharge_FailSts : 59|1@0+ (1,0) [0|1] "" BCM,IPC,TBM

BO_ 1378 HCP_2: 8 EVCU
 SG_ AirHtrCoreTemp : 55|8@0+ (1,-40) [-40|214] "°C" BCM
 SG_ AirHtrPCBTemp : 63|8@0+ (1,-40) [-40|214] "°C" BCM
 SG_ AirHtrPwrCnsAct : 47|8@0+ (1,0) [0|254] "%" BCM
 SG_ FRfShVlvSts : 23|1@0+ (1,0) [0|1] "" BCM,TBM
 SG_ HVBat_CoolantLvlLo : 18|2@0+ (1,0) [0|3] "" IPC
 SG_ HVBatCritCondT : 21|1@0+ (1,0) [0|1] "-" BCM,TBM

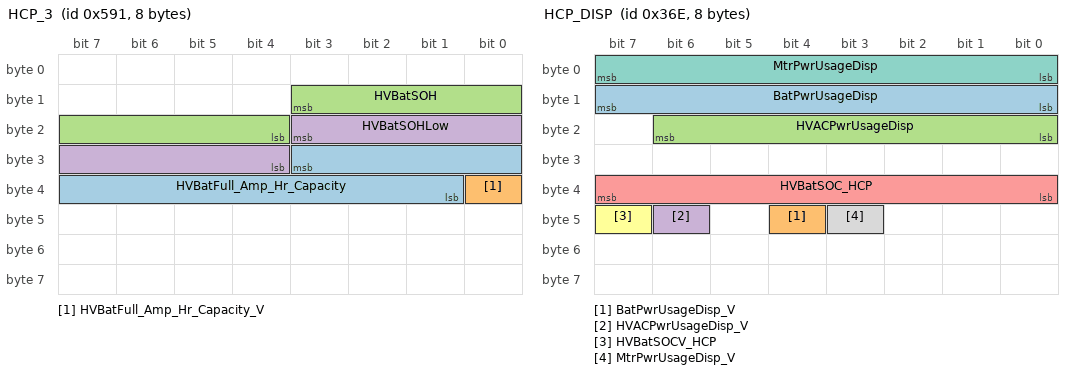
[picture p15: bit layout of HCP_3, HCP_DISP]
BO_ 1425 HCP_3: 8 EVCU
 SG_ HVBatFull_Amp_Hr_Capacity : 27|11@0+ (0.1,0) [0|200] "Ah" TBM
 SG_ HVBatFull_Amp_Hr_Capacity_V : 32|1@0+ (1,0) [0|1] "" TBM
 SG_ HVBatSOH : 11|8@0+ (0.2,50) [50|100] "%" TBM
 SG_ HVBatSOHLow : 19|8@0+ (0.2,50) [50|100] "%" TBM

BO_ 654 HCP_C1: 8 EVCU
 SG_ HCPCoachDisp : 47|8@0+ (1,-100) [-100|100] "%" Vector__XXX
 SG_ HCPCoachDispV : 30|1@0+ (1,0) [0|10] "" Vector__XXX
 SG_ HCPOutputPwr : 39|8@0+ (1,-100) [-100|100] "%" IPC
 SG_ HCPOutputPwrV : 29|1@0+ (1,0) [0|1] "" IPC
 SG_ HCPPopUpMessage1 : 8|1@0+ (1,0) [0|1] "" IPC
 SG_ HCPPopUpMessage10 : 1|1@0+ (1,0) [0|1] "" IPC
 SG_ HCPPopUpMessage11 : 2|1@0+ (1,0) [0|1] "" IPC
 SG_ HCPPopUpMessage13 : 5|1@0+ (1,0) [0|1] "" IPC
 SG_ HCPPopUpMessage14 : 18|1@0+ (1,0) [0|1] "" IPC
 SG_ HCPPopUpMessage15 : 17|1@0+ (1,0) [0|1] "" IPC
 SG_ HCPPopUpMessage2 : 9|1@0+ (1,0) [0|1] "" IPC
 SG_ HCPPopUpMessage3 : 10|1@0+ (1,0) [0|1] "" IPC
 SG_ HCPPopUpMessage4 : 11|1@0+ (1,0) [0|1] "" IPC
 SG_ HCPPopUpMessage5 : 12|1@0+ (1,0) [0|1] "" IPC
 SG_ HCPPopUpMessage6 : 13|1@0+ (1,0) [0|1] "" IPC
 SG_ HCPPopUpMessage7 : 14|1@0+ (1,0) [0|1] "" IPC
 SG_ HCPPopUpMessage9 : 0|1@0+ (1,0) [0|1] "" IPC

BO_ 878 HCP_DISP: 8 EVCU
 SG_ BatPwrUsageDisp : 15|8@0+ (1,-125) [-125|130] "kW" BCM,ETM,LTM
 SG_ BatPwrUsageDisp_V : 44|1@0+ (1,0) [0|1] "" BCM,ETM,LTM
 SG_ HVACPwrUsageDisp : 22|7@0+ (1,0) [0|127] "kW" BCM,ETM,LTM,TBM
 SG_ HVACPwrUsageDisp_V : 46|1@0+ (1,0) [0|1] "" BCM,ETM,LTM
 SG_ HVBatSOC_HCP : 39|8@0+ (0.3922,0) [0|100] "%" BCM,BSM,ETM,IPC,LTM,TBM
 SG_ HVBatSOCV_HCP : 47|1@0+ (1,0) [0|1] "" BCM,BSM,ETM,IPC,LTM,TBM
 SG_ MtrPwrUsageDisp : 7|8@0+ (1,-125) [-125|130] "kW" BCM,ETM,LTM
 SG_ MtrPwrUsageDisp_V : 43|1@0+ (1,0) [0|1] "" BCM,ETM,LTM

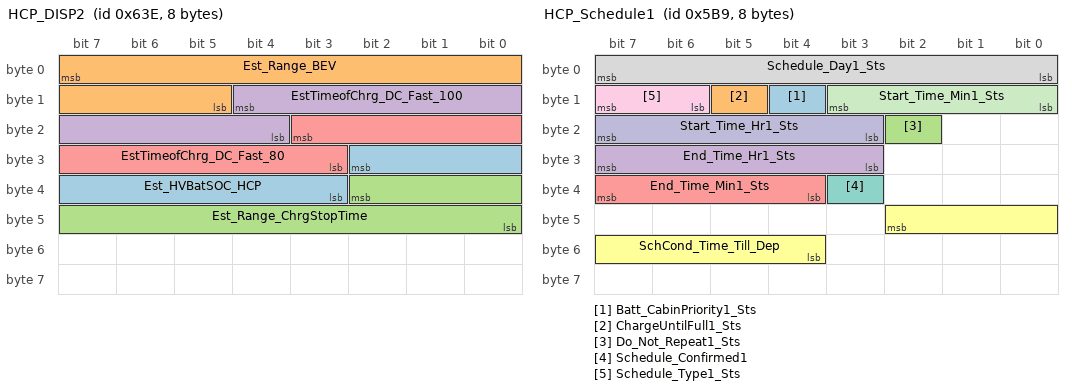
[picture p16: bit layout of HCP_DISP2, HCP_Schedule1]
BO_ 1598 HCP_DISP2: 8 EVCU
 SG_ Est_HVBatSOC_HCP : 26|8@0+ (0.3922,0) [0|100] "%" ETM,LTM
 SG_ Est_Range_BEV : 7|11@0+ (1,0) [0|2046] "km" ETM,IPC,TBM
 SG_ Est_Range_ChrgStopTime : 34|11@0+ (1,0) [0|2046] "km" ETM,LTM,TBM
 SG_ EstTimeofChrg_DC_Fast_100 : 12|9@0+ (1,0) [0|510] "min" ETM,IPC,LTM,TBM
 SG_ EstTimeofChrg_DC_Fast_80 : 19|9@0+ (1,0) [0|510] "min" ETM,IPC,LTM

BO_ 1465 HCP_Schedule1: 8 EVCU
 SG_ Batt_CabinPriority1_Sts : 12|1@0+ (1,0) [0|1] "-" ETM,LTM,TBM
 SG_ ChargeUntilFull1_Sts : 13|1@0+ (1,0) [0|1] "-" ETM,LTM,TBM
 SG_ Do_Not_Repeat1_Sts : 18|1@0+ (1,0) [0|1] "-" ETM,LTM,TBM
 SG_ End_Time_Hr1_Sts : 31|5@0+ (1,0) [0|23] "Hours" ETM,LTM,TBM
 SG_ End_Time_Min1_Sts : 39|4@0+ (5,0) [0|55] "min" ETM,LTM,TBM
 SG_ SchCond_Time_Till_Dep : 42|7@0+ (1,0) [0|126] "min" BCM
 SG_ Schedule_Confirmed1 : 35|1@0+ (1,0) [0|1] "-" ETM,LTM,TBM
 SG_ Schedule_Day1_Sts : 7|8@0+ (1,0) [0|255] "-" ETM,LTM,TBM
 SG_ Schedule_Type1_Sts : 15|2@0+ (1,0) [0|3] "-" ETM,LTM,TBM
 SG_ Start_Time_Hr1_Sts : 23|5@0+ (1,0) [0|23] "Hours" ETM,LTM,TBM
 SG_ Start_Time_Min1_Sts : 11|4@0+ (5,0) [0|55] "min" ETM,LTM,TBM

BO_TX_BU_ 2564440305 : DIAG_TEST,TBM;
BO_TX_BU_ 2564441329 : DIAG_TEST,TBM;
BO_TX_BU_ 2564434161 : BCM,TBM;
BO_TX_BU_ 2564434673 : DIAG_TEST,TBM;
BO_TX_BU_ 2564436209 : BCM,TBM;
BO_TX_BU_ 2564440817 : DIAG_TEST,TBM;
BO_TX_BU_ 2564436465 : BCM,TBM;
BO_TX_BU_ 2564444401 : DIAG_TEST,TBM;
BO_TX_BU_ 2564448497 : DIAG_TEST,TBM;
BO_TX_BU_ 2564473073 : BCM,TBM;
BO_TX_BU_ 2564464881 : BCM,TBM;
BO_TX_BU_ 2564475889 : DIAG_TEST,TBM;
BO_TX_BU_ 2564431857 : DIAG_TEST,TBM;

CM_ "Project_332BEV_ProjectStandard_C-CAN1 [07340]";
CM_ SG_ 599 AirBagFailSts "This signal is used to require the activation/deactivation of airbag warning light";
CM_ SG_ 599 PsngrBagChargeSts "This signal is used to communicate the status of Front Passenger Protection Pyrotechnical charges";
CM_ SG_ 599 SBR1RowCentralSeatBuckleFailSts "First row central seatbelt buckle switch fail status";
CM_ SG_ 599 SBR1RowCentralSeatConfigSts "Signal used to show if the first row central seatbelt is under check";
CM_ SG_ 599 SBR1RowCentralSeatPPDFailSts "PPD fail status of first row central seat";
CM_ SG_ 599 SBR1RowCentralSeatSts "First row central seat status";
CM_ SG_ 599 SBR1RowDriverSeatConfigSts "Signal used to show if the first row driver seatbelt is under check";
CM_ SG_ 599 SBR1RowDriverSeatFailSts "First row driver seatbelt switch fail status";
CM_ SG_ 599 SBR1RowDriverSeatSts "First row driver seatbelt switch status";
CM_ SG_ 599 SBR1RowPsngrSeatBuckleFailSts "First row passenger seatbelt buckle switch fail status";
CM_ SG_ 599 SBR1RowPsngrSeatConfigSts "Signal used to show if the first row passenger seatbelt is under check";
CM_ SG_ 599 SBR1RowPsngrSeatPPDFailSts "PPD fail status of first row passenger seat";
CM_ SG_ 599 SBR1RowPsngrSeatSts "First row passenger seat status";
CM_ SG_ 599 SBR2RowCentralSeatConfigSts "Signal used to show if the second row central seatbelt is under check";
CM_ SG_ 599 SBR2RowCentralSeatSts "Second row central seatbelt switch status";
CM_ SG_ 599 SBR2RowLeftSeatConfigSts "Signal used to show if the second row central seatbelt is under check";
CM_ SG_ 599 SBR2RowLeftSeatSts "Second row left seatbelt switch status";
CM_ SG_ 599 SBR2RowRightSeatConfigSts "Signal used to show if the second row central seatbelt is under check";
CM_ SG_ 599 SBR2RowRightSeatSts "Second row right seatbelt switch status";
CM_ SG_ 1447 CRC_A2 "CRC according to SAE J1850 standard that has to be calculated at each frame transmission";
CM_ SG_ 1447 DrvSbltUnFltr "Driver seatbelt fault status - unfiltered";
CM_ SG_ 1447 MessageCounter_A2 "This signal is a counter used for safety checks strategies. This counter is incremented of 1 (one) unit at each frame transmission";
CM_ SG_ 1050 BatteryCurrentLevel "This signal indicates the battery current.";
CM_ SG_ 1050 BatteryTemperature "This signal indicates the battery temperature.";
CM_ SG_ 1050 StateOfCharge "This signal indicates the battery state of charge.";
CM_ SG_ 250 CmdIgnSts "The signal is used to give information about the key selector position";
CM_ SG_ 250 EngineOffRequest "The signal is used to require an  engine shut off";
CM_ SG_ 250 KeyInIgnSts "Key in ignition status";
CM_ SG_ 250 MessageCounter_BC "This signal is a counter used for safety checks strategies. This counter is incremented of 1 (one) unit at each frame transmission.";
CM_ SG_ 250 TurnIndicatorSts "The signal is used to indicate the turn indicator position.";
CM_ SG_ 1444 AirHtwPwrTgt "Used to give the target power to Electric Air Heater";
CM_ SG_ 1444 PreCondCabinSts "HVAC Pre-Condition Status";
CM_ SG_ 1200 ChargeNow "Charge Now Signal";
CM_ SG_ 1200 ChargeNow_TBM "Charge Now signal (gated from TBM)";
CM_ SG_ 1472 Force_Park "This signal is used to require the Park shift lever position insertion.";
CM_ SG_ 1472 MemRq_FobNum "FOB number making the request";
CM_ SG_ 1472 RFFuncReq "Basic request (RKE, PE, Remstart)";
CM_ SG_ 1472 RFReq "Who's asking for the request";
CM_ SG_ 748 AVASFailSts "This signal indicates an AVAS Fail";
CM_ SG_ 748 FrontWiperMoveSts "This signal indicates the position of the front wiper (contact cam open or close)";
CM_ SG_ 1470 LockUnlockVehicleSts "This signal is used to give information about the lock\unlock status of the vehicle";
CM_ SG_ 900 DriveStyleSts "This signal gives indications about drive style status required.";
CM_ SG_ 900 DsuRequest "This signal is used to trigger everytime the selection";
CM_ SG_ 900 EVAP_TEMP_P1C "AC evaporator temp at 0.1 degrees C resolution";
CM_ SG_ 900 Int_Relay_FailSts "Used to indicate an anomaly on the INT.Relay device";
CM_ SG_ 900 ParkBrakeSts "This signal gives indications about Electric Parking Brake status";
CM_ SG_ 900 Selection_SystemFailSts "This signal is enabled when BCM detects a fault on the other ECU";
CM_ SG_ 900 SportAvailable "This signal indicates if the request to move in a sport mode is available, respect to a vehicle speed calibrable";
CM_ SG_ 1349 ExternalTemperatureAD_Voltage "Indicates the raw voltage of the ambient temp sensor";
CM_ SG_ 1349 InternalLightLevel "Used to give information about the backlight dimming level selected.";
CM_ SG_ 1349 InternalLightSts "Used to give information about backlight mode selected (Day or Night).";
CM_ SG_ 1349 NoShutOff "This signal is used to enable the indication to inform the user that the vehice can't shut off.";
CM_ SG_ 1201 BonnetFailSts "Signal used to inform other systems about an electric fault on bonnet ajar switch.";
CM_ SG_ 1201 BonnetSts "Used to give information about the bonnet status";
CM_ SG_ 1201 BrakeFluidLevelSts "This signal indicates when the brake fluid level is low or normal";
CM_ SG_ 1201 CompressorACReqSts "This signal is sent from BCM to ECM to inform of Compressor AC activation request";
CM_ SG_ 1201 DriverDoorFailSts "Signal used to inform other systems about an electric fault on driver ajar switch.";
CM_ SG_ 1201 DriverDoorSts "This signal indicates the driver door status";
CM_ SG_ 1201 ExteriorRearReleaseSwitchSts "Used to give rear access button press info to the body controller to allow releasing the rear access point";
CM_ SG_ 1201 FHeatedWindowLoadSts "The signal indicates the effective activation of heated front window.";
CM_ SG_ 1201 PreCond_InhibitSts "Cabin Pre Condition inhbit reason";
CM_ SG_ 1201 PreCondActvSts "Cabin Pre Condition Status";
CM_ SG_ 1201 PsngrDoorSts "This signal indicates the passenger door status";
CM_ SG_ 1201 RemSt_InhibitSts "Remote start inhibit";
CM_ SG_ 1201 RemStActvSts "Type of start being requested";
CM_ SG_ 1201 RHeatedWindowLoadSts "The signal indicates the effective activation of heated rear window.";
CM_ SG_ 1201 TheftAlarmStatus "VTA status";
CM_ SG_ 1049 BonnetAjarRawValSts "This signal is used to indicate the raw value status of the Bonnet Ajar switch";
CM_ SG_ 1049 CRC_BODY7 "CRC according to SAE J1850 standard that has to be calculated from bit 63 to bit 8 at each frame transmission.";
CM_ SG_ 1049 DriveStyleSts "This signal gives indications about drive style status required.";
CM_ SG_ 1049 DRV_DR_UNLOCKING "This signal describe the actuation state of driver door unlock switch";
CM_ SG_ 1049 MessageCounter_BODY7 "This signal is a counter used for safety checks strategies. This counter is incremented of 1 (one) unit at each frame transmission.";
CM_ SG_ 257 ABSActive "This signal is set to Active when the ABS functionality is active.";
CM_ SG_ 257 Brake_MaxRegen_Ready "Brake module readiness for Max Regen function";
CM_ SG_ 257 BrakeInterventionSts "This signal is \"active\" when the brake intervention is due to ESC, ASR, ACC systems and \"not active\" when the brake intervention is due to the driver.";
CM_ SG_ 257 CRC_B1 "CRC according to SAE J1850 standard that has to be calculated from bit 63 to bit 8 at each frame transmission.";
CM_ SG_ 257 ESCActive "This signal is set to Active when the brake intervention by ESC is active.";
CM_ SG_ 257 MessageCounter_B1 "This signal is a counter used for safety checks strategies. This counter is incremented of 1 (one) unit at each frame transmission.";
CM_ SG_ 257 PrefillActive "This signal indicates the prefill function status.";
CM_ SG_ 257 VehicleSpeedVSOSig "It is the average vehicle speed calculated.";
CM_ SG_ 257 VehicleSpeedVSOSigFailSts "It is the average vehicle speed fail status.";
CM_ SG_ 257 VehicleStandStillSts "This signal indicates if the car is in stand still condition";
CM_ SG_ 506 BrkPdl_Stat "Brake pedal state";
CM_ SG_ 259 BrakeTravelSts "This signal indicate the brake pedal travel";
CM_ SG_ 259 BSM_Comm_Fail_CANC2 "Communication fault on CAN C2 detected by BSM.";
CM_ SG_ 501 AEB_InterventionType "DAS Req Active";
CM_ SG_ 501 VehicleStandStillSts "This signal indicates if the car is in stand still condition";
CM_ SG_ 498 ACC_Wheel_Torque_BSM "It indicates the requested wheel torque value of ACC function";
CM_ SG_ 498 ACC_Wheel_Torque_Enabled_BSM "It indicates the request to enable torque interface of ACC function";
CM_ SG_ 498 Brk_Thermdl "This signal indicate when the estimated brake temperature is over a predefined threshold.";
CM_ SG_ 498 CRC_B6 "CRC according to SAE J1850 standard that has to be calculated from bit 63 to bit 8 at each frame transmission.";
CM_ SG_ 498 MessageCounter_B6 "This signal is a counter used for safety checks strategies. This counter is incremented of 1 (one) unit at each frame transmission.";
CM_ SG_ 1048 BrakeFluidLevelSts "This is the indication of   eventual low level of brake fluid";
CM_ SG_ 1048 HNGActive "It indicates the current activation status of the Hold and Go";
CM_ SG_ 1048 TravelDistance "This signal indicates the travel distance value.";
CM_ SG_ 1199 BSMSysSts "This signal is used by BSM to indicate its mode";
CM_ SG_ 1199 ERMActive "This signal is set to \"active\" when Electronic Roll Mitigation functionality is acting.";
CM_ SG_ 1199 RollsModeAct "This signal indicates when the brake system module is in the Rolls Test mode.";
CM_ SG_ 1199 TSCActive "This signal is set to \"active\" when Trailer Sway Control functionality is acting";
CM_ SG_ 1199 TyrePressureSystemFailSts "It indicates the presence of the failure.";
CM_ SG_ 254 CRC_BYD "CRC according to SAE J1850 standard that has to be calculated from bit 63 to bit 8 at each frame transmission.";
CM_ SG_ 254 InternalError_BSM "This signal indicates if an internal error has been processed";
CM_ SG_ 254 LatAcceleration_BSM "This signal indicates the Lateral Acceleration Value";
CM_ SG_ 254 LatAccelerationFailSts_BSM "This signal indicates the status of Lateral Acceleration Signal";
CM_ SG_ 254 LongAcceleration_BSM "This signal indicates the Longitudinal Acceleration Value";
CM_ SG_ 254 LongAccelerationFailSts_BSM "This signal indicates the status of Longitudinal acceleration signal";
CM_ SG_ 254 MessageCounter_BYD "This signal is a counter used for safety checks strategies. This counter is incremented of 1 (one) unit at each frame transmission.";
CM_ SG_ 254 Slope "Slope value detected by BSM";
CM_ SG_ 254 YawRate_BSM "This signal indicates the Yaw Rate Value";
CM_ SG_ 254 YawRateFailSts_BSM "This signal indicates the Status of Yaw Rate Signal";
CM_ SG_ 1440 ACC_RadarBlinded "It communicate if the Radar is blinded or not";
CM_ SG_ 1440 ACC_SetSpeedKPH "Speed shown by IPC, which ACC is controlling in KPH";
CM_ SG_ 1440 ACC_SetSpeedMPH "Speed shown by IPC, which ACC is controlling in MPH";
CM_ SG_ 1440 ACCFailSts "It informs about an ACC failure visualized in the IPC";
CM_ SG_ 1440 ACCSystemSts "It indicates ACC/NCC system status";
CM_ SG_ 1440 AEBFailSts "This signal is used to indicate the presence of a permanent failure in the ECU";
CM_ SG_ 1440 AEBTemporaryFailSts "This signal is used to indicate the presence of a temporary failure in the ECU";
CM_ SG_ 1440 CameraBlinded "This signal is used to indicate that the camera is blinded";
CM_ SG_ 1440 CameraBlocked "This signal is used to indicate the presence of an occlusion on the camera";
CM_ SG_ 1440 FCWSystemSts "This signal is used to indicate the actual system status of FCW features";
CM_ SG_ 1440 HMICode_ACC "It is used in order to command ACC and NCC warnings and failures.";
CM_ SG_ 1440 HMICode_FCW "Signal to activate HMI indication on IPC";
CM_ SG_ 1440 HMIDisplay_ACC "It indicates the status of ACC/NCC, visualized in the IPC";
CM_ SG_ 1440 iACCSts "It indicates the status of Intelligent ACC, visualized on IPC";
CM_ SG_ 601 PowerLimit_Requested "Power Limit request";
CM_ SG_ 601 SpeedUnit "The signal is used to indicate the speed unit";
CM_ SG_ 601 TotalOdometer "Used to give information about the total odometer value in km.";
CM_ SG_ 598 ABSLamp_FailSts "This signal communicates the status of the related lamp.";
CM_ SG_ 598 AirBagLamp_FailSts "This signal is used to inform about the airbag warning light status";
CM_ SG_ 598 DistanceUnit "Used to give information about the distance unit selected.";
CM_ SG_ 598 EBDLamp_FailSts "This signal communicates the status of the related lamp.";
CM_ SG_ 598 EPBAutoAppReqSts "This signal communicates the status of the activation of the functionality AutoApply of the EPB";
CM_ SG_ 598 EPBLamp_FailSts "This signal communicates the status of the related lamp.";
CM_ SG_ 598 EPBMaintenanceReqSts "Request of Activation Maintenance Mode";
CM_ SG_ 598 ESCLamp_FailSts "This signal communicates the status of the related lamp.";
CM_ SG_ 598 FSFCWPlusActivationMode "This signal is used to give information about the FSFCW Activation Mode setting";
CM_ SG_ 598 FSFCWPlusSetting "This signal is used to give information about the FSFCW setting";
CM_ SG_ 598 PassiveEntry "This signal is used to give information about the Passive Entry selected.";
CM_ SG_ 598 PsngrBagRequestSts "This signal is used by IPC to send the request of the customer to change the current status of Front Passenger Protection";
CM_ SG_ 598 RemoteDoorUnlock "This signal is used to give information about the Remote Door Unlock selected.";
CM_ SG_ 224 AutoHold "Auto Hold setting";
CM_ SG_ 224 DisplayedSpeedSign "This signal indicates the road sign of vehicle speed limit displayed by IPC";
CM_ SG_ 224 NewSpdZoneInd "New Speed Zone Indication setting";
CM_ SG_ 224 SignCaptureMode "Intelligent Speed Mode setting";
CM_ SG_ 2564554481 N_PDU "This signal is used for diagnostic purposes";
CM_ SG_ 2564440305 N_PDU "This signal is used for diagnostic purposes";
CM_ SG_ 2564441329 N_PDU "This signal is used for diagnostic purposes";
CM_ SG_ 2564434161 N_PDU "This signal is used for diagnostic purposes";
CM_ SG_ 2564434673 N_PDU "This signal is used for diagnostic purposes";
CM_ SG_ 2564436209 N_PDU "This signal is used for diagnostic purposes";
CM_ SG_ 2564440817 N_PDU "This signal is used for diagnostic purposes";
CM_ SG_ 2564502513 N_PDU "This signal is used for diagnostic purposes";
CM_ SG_ 2564436465 N_PDU "This signal is used for diagnostic purposes";
CM_ SG_ 2564444401 N_PDU "This signal is used for diagnostic purposes";
CM_ SG_ 2564448497 N_PDU "-";
CM_ SG_ 2564473073 N_PDU "This signal is used for diagnostic purposes";
CM_ SG_ 2564464881 N_PDU "This signal is used for diagnostic purposes";
CM_ SG_ 2564444145 N_PDU "This signal is used for diagnostic purposes";
CM_ SG_ 2564475889 N_PDU "This signal is used for diagnostic purposes";
CM_ SG_ 2564431857 N_PDU "This signal is used for diagnostic purposes.";
CM_ SG_ 2564474609 N_PDU "-";
CM_ SG_ 2564445937 N_PDU "This signal is used for diagnostic purposes";
CM_ SG_ 2564446193 N_PDU "This signal is used for diagnostic purposes";
CM_ SG_ 2564485440 N_PDU "This signal is used for diagnostic purposes";
CM_ SG_ 2564485444 N_PDU "This signal is used for diagnostic purposes";
CM_ SG_ 2564485418 N_PDU "This signal is used for diagnostic purposes";
CM_ SG_ 2564485442 N_PDU "This signal is used for diagnostic purposes";
CM_ SG_ 2564485456 N_PDU "This signal is used for diagnostic purposes";
CM_ SG_ 2564485472 N_PDU "-";
CM_ SG_ 2564485455 N_PDU "This signal is used for diagnostic purposes";
CM_ SG_ 2564485579 N_PDU "This signal is used for diagnostic purposes";
CM_ SG_ 2564485407 N_PDU "This is a signal used for diagnostic purposes.";
CM_ SG_ 2564485672 N_PDU "This signal is used for diagnostic purposes";
CM_ SG_ 2564485680 N_PDU "This signal is used for diagnostic purposes";
CM_ SG_ 2564485681 N_PDU "This signal is used for diagnostic purposes";
CM_ SG_ 2564485824 N_PDU "This signal is used for diagnostic purposes";
CM_ SG_ 2564485792 N_PDU "This signal is used for diagnostic purposes";
CM_ SG_ 2564485574 N_PDU "-";
CM_ SG_ 2564485462 N_PDU "This signal is used for diagnostic purposes";
CM_ SG_ 2564485463 N_PDU "This signal is used for diagnostic purposes";
CM_ SG_ 252 PowertrainPrplsnActv "Propulsion status.";
CM_ SG_ 252 ReverseGearSts "Used to give information about Reverse Gear status";
CM_ SG_ 1445 CC_SetSpdDspl_KPH "Cruise Control Vehicle Set Speed in Kilometer Per Hour";
CM_ SG_ 1445 CC_SetSpdDspl_MPH "Cruise Control Vehicle Set Speed in Miles Per Hour";
CM_ SG_ 1445 CruiseControlLampSts "It is the cruise control light command";
CM_ SG_ 1445 CruiseControlSts "It gives information  on C-CAN network about the actual status of cruise control function.";
CM_ SG_ 1445 ISASts "This signal will be used to indicate when the Intelligent Speed Assist is Active";
CM_ SG_ 1445 SpeedLimitSts "It represents on C-CAN the actual status of speed limiter control function.";
CM_ SG_ 496 ActualPedalPos "Actual pedal position.";
CM_ SG_ 550 ECM_WARN "This signal will be used to drive warning messages on Cluster.";
CM_ SG_ 1854 StopLightSts "Request of Stop Lights activation";
CM_ SG_ 222 CRC_G "CRC according to SAE J1850 standard that has to be calculated at each frame transmission.";
CM_ SG_ 222 ElectricSteeringFailSts "It indicates if system EPS has an internal fault.";
CM_ SG_ 222 LwsAngle "This signal indicates the steering angle value, counterclockwise positive.";
CM_ SG_ 222 LwsCalibration "This signal indicates if the sensor has been calibrated and therefore the steering angle value is exported over Can.";
CM_ SG_ 222 LWSFailSts "This signal indicates steering angle export function failure status.";
CM_ SG_ 222 LwsSpeed "This signal indicates the steering speed value, counterclockwise positive.";
CM_ SG_ 222 MessageCounter_G "This signal is a message counter.  Every time a new message is sent by the node, this value is incremented.";
CM_ SG_ 1896 GPS_POS3_Date_Day "GPS date day";
CM_ SG_ 1896 GPS_POS3_Date_Hour "GPS date hour";
CM_ SG_ 1896 GPS_POS3_Date_Minutes "GPS date minutes";
CM_ SG_ 1896 GPS_POS3_Date_Month "GPS date month";
CM_ SG_ 1896 GPS_POS3_Date_Seconds "GPS date seconds";
CM_ SG_ 1896 GPS_POS3_Date_Year "GPS date year";
CM_ SG_ 701 AHCP_Comm_Fail_CANC2 "Communication fault on CAN C2 detected by AHCP.";
CM_ SG_ 701 Drive_Mode_Inhibit "BEV Drive Mode inhibit";
CM_ SG_ 701 Est_Range_Trend "Estimated Range Trend";
CM_ SG_ 701 HCP_Sch_PreCondition_Sts "HCP Status for Scheduled Pre Conditioning Request";
CM_ SG_ 701 HEV_LMP_RQ "HEV service lamp request";
CM_ SG_ 701 R134a_PressSts "Refrigerant pressure (R134a or R1234YF)";
CM_ SG_ 701 TurtleModeSts "Turtle mode status.";
CM_ SG_ 701 VehSpd_Overridden "EVCU vehicle speed overridden status";
CM_ SG_ 1377 Cabin_Condition_Sts "Cabin condition status";
CM_ SG_ 1377 ChargingLevel "Charging level and type.";
CM_ SG_ 1377 ChargingSysSts "Charging System status";
CM_ SG_ 1377 ChrgSysFault "Charging System Fault status";
CM_ SG_ 1377 CompStat "comppressor state";
CM_ SG_ 1377 DriveReady "Ready to Drive, [1] = Vehicle is allowed to shift out of park or neutral";
CM_ SG_ 1377 EstTimeofChrg_Lv1 "Estimated Time to charge on Level 1";
CM_ SG_ 1377 EstTimeofChrg_Lv2 "Estimated Time to charge on Level 2";
CM_ SG_ 1377 HVBatCntctrStat "HV Battery pack contactor state";
CM_ SG_ 1377 MIL_OnRq_BPCM "MIL Lamp request from BPCM.";
CM_ SG_ 1377 PrplsnSysAtv "Propulsion system active, [1] = active";
CM_ SG_ 1377 Service_Battery_Recharge_FailSts "Information about status of Service_Battery_Recharge";
CM_ SG_ 1378 AirHtrCoreTemp "Electric Air Heater Core Temperature";
CM_ SG_ 1378 AirHtrPCBTemp "Electric Air Heater PCB Temperature";
CM_ SG_ 1378 AirHtrPwrCnsAct "Used to give information about actual heater power consumption";
CM_ SG_ 1378 FRfShVlvSts "Front Refrigerant Shutoff Valve Status  [0] = Open, [1] = Closed";
CM_ SG_ 1378 HVBat_CoolantLvlLo "Battery coolant level low";
CM_ SG_ 1378 HVBatCritCondT "High Voltage Battery Temperature Critical Condition, [1] = True";
CM_ SG_ 1425 HVBatFull_Amp_Hr_Capacity "Total HV Battery Amp Hour Capacity";
CM_ SG_ 1425 HVBatFull_Amp_Hr_Capacity_V "Total HV battery amp hour capacity validity; Invalid = [1]";
CM_ SG_ 1425 HVBatSOH "HV Battery percentage of State of Health.  Last-Known value to be stored in EEPROM.";
CM_ SG_ 1425 HVBatSOHLow "HV Battery percentage of State of Health Low";
CM_ SG_ 654 HCPCoachDisp "Percentage output acceleration & deceleration to support Efficiency Coaching HMI";
CM_ SG_ 654 HCPCoachDispV "Acceleration & deceleration to support Efficiency Coaching validtiy, 0 = Valid, 1 = Invalid";
CM_ SG_ 654 HCPOutputPwr "Percentage output power from HCP for HMI";
CM_ SG_ 654 HCPOutputPwrV "Percentage output power from HCP for HMI validity, 0 = Valid, 1 = Invalid";
CM_ SG_ 654 HCPPopUpMessage1 "Vehicle speed may be limited; True = [1]";
CM_ SG_ 654 HCPPopUpMessage10 "High Voltage Functionalities rejected due to Hood Open; True = [1]";
CM_ SG_ 654 HCPPopUpMessage11 "Charge port door open; True = [1]";
CM_ SG_ 654 HCPPopUpMessage13 "Charge port Inlet Unlocking failed";
CM_ SG_ 654 HCPPopUpMessage14 "One Pedal Drive is unavailable, press brake pedal to brake; True = [1].";
CM_ SG_ 654 HCPPopUpMessage15 "Vehicle will shut off soon, press brake pedal to stop safely; True = [1].";
CM_ SG_ 654 HCPPopUpMessage2 "Plug in vehicle to keep battery warm; True = [1]";
CM_ SG_ 654 HCPPopUpMessage3 "Remote start canceled - hv battery temperature; True = [1]";
CM_ SG_ 654 HCPPopUpMessage4 "Turn on vehicle to use climate controls; True = [1]";
CM_ SG_ 654 HCPPopUpMessage5 "Please check plug status before driving; True = [1]";
CM_ SG_ 654 HCPPopUpMessage6 "There may be a problem with the charging unit; True = [1]";
CM_ SG_ 654 HCPPopUpMessage7 "Please leave key in run - battery conditioning needed; True = [1]";
CM_ SG_ 654 HCPPopUpMessage9 "Stop safely. Vehicle will shut off soon; True = [1]";
CM_ SG_ 878 BatPwrUsageDisp "Battery power usage for HMI, in KW";
CM_ SG_ 878 BatPwrUsageDisp_V "Validity bit for signal BatPwrUsageDisp, 0=Valid";
CM_ SG_ 878 HVACPwrUsageDisp "HVAC power usage for HMI, in KW";
CM_ SG_ 878 HVACPwrUsageDisp_V "Validity bit for signal HVACPwrUsageDisp, 0=Valid";
CM_ SG_ 878 HVBatSOC_HCP "High voltage battery state of charge";
CM_ SG_ 878 HVBatSOCV_HCP "High voltage battery state of charge validity: invalid = [1]";
CM_ SG_ 878 MtrPwrUsageDisp "Motor power usage for HMI, in KW";
CM_ SG_ 878 MtrPwrUsageDisp_V "Validity bit for signal MtrPwrUsageDisp, 0=Valid";
CM_ SG_ 1598 Est_HVBatSOC_HCP "Estimated HV battery State of Charge (SOC) at the scheduled charge cycle stop time";
CM_ SG_ 1598 Est_Range_BEV "Estimated range of the vehicle";
CM_ SG_ 1598 Est_Range_ChrgStopTime "Estimated EV range at the scheduled charge cycle stop time (based on SOC)";
CM_ SG_ 1598 EstTimeofChrg_DC_Fast_100 "Estimated time (in minutes) to charge the HV battery to 100% using DC Fast Charging";
CM_ SG_ 1598 EstTimeofChrg_DC_Fast_80 "Estimated time (in minutes) to charge the HV battery to 80% using DC Fast Charging";
CM_ SG_ 1465 Batt_CabinPriority1_Sts "Bit to prioritize cabin conditioning under schedule 1";
CM_ SG_ 1465 ChargeUntilFull1_Sts "Charge until battery is fully charged with schedule 1";
CM_ SG_ 1465 Do_Not_Repeat1_Sts "Do not repeat the set Schedule";
CM_ SG_ 1465 End_Time_Hr1_Sts "End Time of schedule 1 (hours in 24 hrs. format)";
CM_ SG_ 1465 End_Time_Min1_Sts "End Time of schedule 1(Minutes)";
CM_ SG_ 1465 SchCond_Time_Till_Dep "Schedule Cabin Conditonting - Time till Departure for HVAC";
CM_ SG_ 1465 Schedule_Confirmed1 "Confirm the requested schedule 1";
CM_ SG_ 1465 Schedule_Day1_Sts "Schedule#1 Day for charging or cabin conditioning";
CM_ SG_ 1465 Schedule_Type1_Sts "Type of charging and climate schedule";
CM_ SG_ 1465 Start_Time_Hr1_Sts "Start Time of schedule  1 (hours in 24 hrs. format)";
CM_ SG_ 1465 Start_Time_Min1_Sts "Start Time of schedule  1 (minutes)";

BA_DEF_ SG_ "Accuracy" STRING ;
BA_DEF_ SG_ "Event trans." ENUM "Yes","No";
BA_DEF_ SG_ "GenSigStartValue" INT 0 2147483647;
BA_DEF_ SG_ "GenSigInactiveValue" INT 0 2147483647;
BA_DEF_ SG_ "GenSigSendType" ENUM "NotUsed","OnWrite","OnWriteWithRepetition","OnChange","OnChangeWithRepetition","IfActive","IfActiveWithRepetition","NoSigSendType";
BA_DEF_ BO_ "DiagRequest" ENUM "No","Yes";
BA_DEF_ BO_ "Period [ms]" INT 0 65535;
BA_DEF_ BO_ "Type" ENUM "P","C","PE","COC","PE_Cntrl","E","E_Cntrl","OC","S","BAF","DC","EM","MM","-";
BA_DEF_ BO_ "DiagResponse" ENUM "No","Yes";
BA_DEF_ BO_ "NmMessage" ENUM "No","Yes";
BA_DEF_ BO_ "GenMsgSendType" ENUM "Cyclic","NotUsed","NotUsed","NotUsed","NotUsed","NotUsed","NotUsed","NotUsed","NoMsgSendType";
BA_DEF_ BO_ "GenMsgTimeoutTime" INT 0 10000;
BA_DEF_ BO_ "GenMsgNrOfRepetition" INT 0 255;
BA_DEF_ BO_ "GenMsgILSupport" ENUM "No","Yes";
BA_DEF_ BO_ "GenMsgStartDelayTime" INT 0 65535;
BA_DEF_ BO_ "GenMsgCycleTimeFast" INT 0 65535;
BA_DEF_ BO_ "GenMsgCycleTime" INT 0 65535;
BA_DEF_ BO_ "GenMsgDelayTime" INT 0 65535;
BA_DEF_ BO_ "DiagState" ENUM "No","Yes";
BA_DEF_ BU_ "NodeLayerModules" STRING ;
BA_DEF_ BU_ "Description" STRING ;
BA_DEF_ BU_ "NmStationAddress" HEX 0 255;
BA_DEF_ BU_ "NmNode" ENUM "No","Yes";
BA_DEF_ BU_ "ILUsed" ENUM "No","Yes";
BA_DEF_ BU_ "TpOwnSystemEcuNumber" HEX 0 255;
BA_DEF_ BU_ "NmNodeType" ENUM "kMaster","kSlave15","kSlave30","none";
BA_DEF_ BU_ "NwmNodeType" ENUM "kMaster","kSlave15","kSlave30","none";
BA_DEF_ "Manufacturer" STRING ;
BA_DEF_ "NmType" STRING ;
BA_DEF_ "BusType" STRING ;
BA_DEF_ "Baudrate" INT 0 1000000;
BA_DEF_ "DBName" STRING ;
BA_DEF_ "Version" HEX 0 255;
BA_DEF_ "VersionWeek" INT 0 53;
BA_DEF_ "VersionYear" INT 0 99;
BA_DEF_DEF_ "Accuracy" "";
BA_DEF_DEF_ "Event trans." "No";
BA_DEF_DEF_ "GenSigStartValue" 0;
BA_DEF_DEF_ "GenSigInactiveValue" 0;
BA_DEF_DEF_ "GenSigSendType" "NoSigSendType";
BA_DEF_DEF_ "DiagRequest" "No";
BA_DEF_DEF_ "Period [ms]" 0;
BA_DEF_DEF_ "Type" "-";
BA_DEF_DEF_ "DiagResponse" "No";
BA_DEF_DEF_ "NmMessage" "No";
BA_DEF_DEF_ "GenMsgSendType" "NoMsgSendType";
BA_DEF_DEF_ "GenMsgTimeoutTime" 0;
BA_DEF_DEF_ "GenMsgNrOfRepetition" 0;
BA_DEF_DEF_ "GenMsgILSupport" "No";
BA_DEF_DEF_ "GenMsgStartDelayTime" 0;
BA_DEF_DEF_ "GenMsgCycleTimeFast" 0;
BA_DEF_DEF_ "GenMsgCycleTime" 0;
BA_DEF_DEF_ "GenMsgDelayTime" 0;
BA_DEF_DEF_ "DiagState" "No";
BA_DEF_DEF_ "NodeLayerModules" "Osek_TP.dll";
BA_DEF_DEF_ "Description" "";
BA_DEF_DEF_ "NmStationAddress" 0;
BA_DEF_DEF_ "NmNode" "Yes";
BA_DEF_DEF_ "ILUsed" "Yes";
BA_DEF_DEF_ "TpOwnSystemEcuNumber" 0;
BA_DEF_DEF_ "NmNodeType" "none";
BA_DEF_DEF_ "NwmNodeType" "none";
BA_DEF_DEF_ "Manufacturer" "Fiat";
BA_DEF_DEF_ "NmType" "";
BA_DEF_DEF_ "BusType" "CAN";
BA_DEF_DEF_ "Baudrate" 500000;
BA_DEF_DEF_ "DBName" "CAN";
BA_DEF_DEF_ "Version" 160;
BA_DEF_DEF_ "VersionWeek" 36;
BA_DEF_DEF_ "VersionYear" 20;
BA_ "NmType" "Fiat_Class_C";
BA_ "DBName" "CAN_C1_Vehicle";
BA_ "Description" BU_ BCM "Body Control Module";
BA_ "TpOwnSystemEcuNumber" BU_ BCM 64;
BA_ "NmNodeType" BU_ BCM 0;
BA_ "NwmNodeType" BU_ BCM 0;
BA_ "Description" BU_ BSM "Braking System Module";
BA_ "NmStationAddress" BU_ BSM 6;
BA_ "TpOwnSystemEcuNumber" BU_ BSM 40;
BA_ "NmNodeType" BU_ BSM 2;
BA_ "NwmNodeType" BU_ BSM 2;
BA_ "Description" BU_ DASM "Driver Assistant System Module";
BA_ "NmStationAddress" BU_ DASM 57;
BA_ "TpOwnSystemEcuNumber" BU_ DASM 42;
BA_ "Description" BU_ DIAG_TEST "Diagnostic Tester";
BA_ "Description" BU_ ESM "Electronic Shifter Module";
BA_ "NmStationAddress" BU_ ESM 22;
BA_ "TpOwnSystemEcuNumber" BU_ ESM 31;
BA_ "NmNodeType" BU_ ESM 2;
BA_ "NwmNodeType" BU_ ESM 2;
BA_ "Description" BU_ ETM "Entertainment Telematic Module";
BA_ "NmStationAddress" BU_ ETM 36;
BA_ "TpOwnSystemEcuNumber" BU_ ETM 135;
BA_ "NmNodeType" BU_ ETM 2;
BA_ "NwmNodeType" BU_ ETM 2;
BA_ "Description" BU_ EVCU "Electric Vehicle Control Unit";
BA_ "NmStationAddress" BU_ EVCU 64;
BA_ "TpOwnSystemEcuNumber" BU_ EVCU 66;
BA_ "NmNodeType" BU_ EVCU 2;
BA_ "NwmNodeType" BU_ EVCU 2;
BA_ "Description" BU_ IPC "Instrument Panel Cluster";
BA_ "NmStationAddress" BU_ IPC 3;
BA_ "TpOwnSystemEcuNumber" BU_ IPC 96;
BA_ "NmNodeType" BU_ IPC 2;
BA_ "NwmNodeType" BU_ IPC 2;
BA_ "Description" BU_ LTM "Low level Telematic Module";
BA_ "NmStationAddress" BU_ LTM 36;
BA_ "TpOwnSystemEcuNumber" BU_ LTM 135;
BA_ "NmNodeType" BU_ LTM 2;
BA_ "NwmNodeType" BU_ LTM 2;
BA_ "Description" BU_ ORC "Occupant Restraint Control";
BA_ "NmStationAddress" BU_ ORC 26;
BA_ "TpOwnSystemEcuNumber" BU_ ORC 192;
BA_ "Description" BU_ SGW "Security Gateway Module";
BA_ "NmStationAddress" BU_ SGW 112;
BA_ "TpOwnSystemEcuNumber" BU_ SGW 203;
BA_ "Description" BU_ TBM "Telematic Box Module";
BA_ "NmStationAddress" BU_ TBM 35;
BA_ "TpOwnSystemEcuNumber" BU_ TBM 198;
BA_ "NmNodeType" BU_ TBM 2;
BA_ "NwmNodeType" BU_ TBM 2;
BA_ "Period [ms]" BO_ 599 100;
BA_ "Type" BO_ 599 3;
BA_ "GenMsgSendType" BO_ 599 0;
BA_ "GenMsgNrOfRepetition" BO_ 599 2;
BA_ "GenMsgILSupport" BO_ 599 1;
BA_ "GenMsgStartDelayTime" BO_ 599 50;
BA_ "GenMsgCycleTimeFast" BO_ 599 20;
BA_ "GenMsgCycleTime" BO_ 599 100;
BA_ "GenMsgDelayTime" BO_ 599 10;
BA_ "Period [ms]" BO_ 1447 1000;
BA_ "Type" BO_ 1447 3;
BA_ "GenMsgSendType" BO_ 1447 0;
BA_ "GenMsgTimeoutTime" BO_ 1447 2500;
BA_ "GenMsgILSupport" BO_ 1447 1;
BA_ "GenMsgStartDelayTime" BO_ 1447 500;
BA_ "GenMsgCycleTime" BO_ 1447 1000;
BA_ "GenMsgDelayTime" BO_ 1447 50;
BA_ "Period [ms]" BO_ 1050 100;
BA_ "Type" BO_ 1050 1;
BA_ "GenMsgSendType" BO_ 1050 0;
BA_ "GenMsgILSupport" BO_ 1050 1;
BA_ "GenMsgStartDelayTime" BO_ 1050 90;
BA_ "GenMsgCycleTime" BO_ 1050 100;
BA_ "Period [ms]" BO_ 250 10;
BA_ "Type" BO_ 250 1;
BA_ "GenMsgSendType" BO_ 250 0;
BA_ "GenMsgILSupport" BO_ 250 1;
BA_ "GenMsgStartDelayTime" BO_ 250 5;
BA_ "GenMsgCycleTime" BO_ 250 10;
BA_ "Period [ms]" BO_ 1994 1000;
BA_ "Type" BO_ 1994 1;
BA_ "GenMsgSendType" BO_ 1994 0;
BA_ "GenMsgTimeoutTime" BO_ 1994 2500;
BA_ "GenMsgILSupport" BO_ 1994 1;
BA_ "GenMsgCycleTime" BO_ 1994 1000;
BA_ "Period [ms]" BO_ 1444 1000;
BA_ "Type" BO_ 1444 3;
BA_ "GenMsgSendType" BO_ 1444 0;
BA_ "GenMsgTimeoutTime" BO_ 1444 2500;
BA_ "GenMsgILSupport" BO_ 1444 1;
BA_ "GenMsgStartDelayTime" BO_ 1444 300;
BA_ "GenMsgCycleTime" BO_ 1444 1000;
BA_ "GenMsgDelayTime" BO_ 1444 20;
BA_ "Period [ms]" BO_ 1200 1000;
BA_ "Type" BO_ 1200 3;
BA_ "GenMsgSendType" BO_ 1200 0;
BA_ "GenMsgILSupport" BO_ 1200 1;
BA_ "GenMsgCycleTime" BO_ 1200 1000;
BA_ "GenMsgDelayTime" BO_ 1200 20;
BA_ "Period [ms]" BO_ 1472 1000;
BA_ "Type" BO_ 1472 3;
BA_ "GenMsgSendType" BO_ 1472 0;
BA_ "GenMsgILSupport" BO_ 1472 1;
BA_ "GenMsgCycleTime" BO_ 1472 1000;
BA_ "GenMsgDelayTime" BO_ 1472 20;
BA_ "Period [ms]" BO_ 748 50;
BA_ "Type" BO_ 748 1;
BA_ "GenMsgSendType" BO_ 748 0;
BA_ "GenMsgILSupport" BO_ 748 1;
BA_ "GenMsgStartDelayTime" BO_ 748 25;
BA_ "GenMsgCycleTime" BO_ 748 50;
BA_ "Period [ms]" BO_ 1470 1000;
BA_ "Type" BO_ 1470 3;
BA_ "GenMsgSendType" BO_ 1470 0;
BA_ "GenMsgTimeoutTime" BO_ 1470 2500;
BA_ "GenMsgNrOfRepetition" BO_ 1470 3;
BA_ "GenMsgILSupport" BO_ 1470 1;
BA_ "GenMsgStartDelayTime" BO_ 1470 500;
BA_ "GenMsgCycleTimeFast" BO_ 1470 20;
BA_ "GenMsgCycleTime" BO_ 1470 1000;
BA_ "GenMsgDelayTime" BO_ 1470 20;
BA_ "Period [ms]" BO_ 900 250;
BA_ "Type" BO_ 900 3;
BA_ "GenMsgSendType" BO_ 900 0;
BA_ "GenMsgILSupport" BO_ 900 1;
BA_ "GenMsgStartDelayTime" BO_ 900 60;
BA_ "GenMsgCycleTime" BO_ 900 250;
BA_ "GenMsgDelayTime" BO_ 900 20;
BA_ "Period [ms]" BO_ 1349 250;
BA_ "Type" BO_ 1349 1;
BA_ "GenMsgSendType" BO_ 1349 0;
BA_ "GenMsgILSupport" BO_ 1349 1;
BA_ "GenMsgStartDelayTime" BO_ 1349 190;
BA_ "GenMsgCycleTime" BO_ 1349 250;
BA_ "Period [ms]" BO_ 1201 500;
BA_ "Type" BO_ 1201 3;
BA_ "GenMsgSendType" BO_ 1201 0;
BA_ "GenMsgILSupport" BO_ 1201 1;
BA_ "GenMsgStartDelayTime" BO_ 1201 250;
BA_ "GenMsgCycleTime" BO_ 1201 500;
BA_ "GenMsgDelayTime" BO_ 1201 20;
BA_ "Period [ms]" BO_ 1049 100;
BA_ "Type" BO_ 1049 1;
BA_ "GenMsgSendType" BO_ 1049 0;
BA_ "GenMsgTimeoutTime" BO_ 1049 2500;
BA_ "GenMsgILSupport" BO_ 1049 1;
BA_ "GenMsgStartDelayTime" BO_ 1049 60;
BA_ "GenMsgCycleTime" BO_ 1049 100;
BA_ "Period [ms]" BO_ 257 10;
BA_ "Type" BO_ 257 1;
BA_ "GenMsgSendType" BO_ 257 0;
BA_ "GenMsgILSupport" BO_ 257 1;
BA_ "GenMsgStartDelayTime" BO_ 257 10;
BA_ "GenMsgCycleTime" BO_ 257 10;
BA_ "Period [ms]" BO_ 506 20;
BA_ "Type" BO_ 506 1;
BA_ "GenMsgSendType" BO_ 506 0;
BA_ "GenMsgILSupport" BO_ 506 1;
BA_ "GenMsgCycleTime" BO_ 506 20;
BA_ "Period [ms]" BO_ 259 10;
BA_ "Type" BO_ 259 1;
BA_ "GenMsgSendType" BO_ 259 0;
BA_ "GenMsgILSupport" BO_ 259 1;
BA_ "GenMsgStartDelayTime" BO_ 259 10;
BA_ "GenMsgCycleTime" BO_ 259 10;
BA_ "Period [ms]" BO_ 501 20;
BA_ "Type" BO_ 501 1;
BA_ "GenMsgSendType" BO_ 501 0;
BA_ "GenMsgILSupport" BO_ 501 1;
BA_ "GenMsgStartDelayTime" BO_ 501 20;
BA_ "GenMsgCycleTime" BO_ 501 20;
BA_ "Period [ms]" BO_ 498 20;
BA_ "Type" BO_ 498 1;
BA_ "GenMsgSendType" BO_ 498 0;
BA_ "GenMsgILSupport" BO_ 498 1;
BA_ "GenMsgStartDelayTime" BO_ 498 10;
BA_ "GenMsgCycleTime" BO_ 498 20;
BA_ "Period [ms]" BO_ 1048 100;
BA_ "Type" BO_ 1048 3;
BA_ "GenMsgSendType" BO_ 1048 0;
BA_ "GenMsgILSupport" BO_ 1048 1;
BA_ "GenMsgStartDelayTime" BO_ 1048 50;
BA_ "GenMsgCycleTime" BO_ 1048 100;
BA_ "GenMsgDelayTime" BO_ 1048 20;
BA_ "Period [ms]" BO_ 1199 500;
BA_ "Type" BO_ 1199 3;
BA_ "GenMsgSendType" BO_ 1199 0;
BA_ "GenMsgNrOfRepetition" BO_ 1199 2;
BA_ "GenMsgILSupport" BO_ 1199 1;
BA_ "GenMsgStartDelayTime" BO_ 1199 250;
BA_ "GenMsgCycleTimeFast" BO_ 1199 10;
BA_ "GenMsgCycleTime" BO_ 1199 500;
BA_ "GenMsgDelayTime" BO_ 1199 10;
BA_ "Period [ms]" BO_ 1453 1000;
BA_ "Type" BO_ 1453 3;
BA_ "GenMsgSendType" BO_ 1453 0;
BA_ "GenMsgTimeoutTime" BO_ 1453 2500;
BA_ "GenMsgILSupport" BO_ 1453 1;
BA_ "GenMsgStartDelayTime" BO_ 1453 500;
BA_ "GenMsgCycleTime" BO_ 1453 1000;
BA_ "GenMsgDelayTime" BO_ 1453 20;
BA_ "Period [ms]" BO_ 254 10;
BA_ "Type" BO_ 254 1;
BA_ "GenMsgSendType" BO_ 254 0;
BA_ "GenMsgTimeoutTime" BO_ 254 2500;
BA_ "GenMsgILSupport" BO_ 254 1;
BA_ "GenMsgStartDelayTime" BO_ 254 5;
BA_ "GenMsgCycleTime" BO_ 254 10;
BA_ "Period [ms]" BO_ 1440 1000;
BA_ "Type" BO_ 1440 3;
BA_ "GenMsgSendType" BO_ 1440 0;
BA_ "GenMsgTimeoutTime" BO_ 1440 2500;
BA_ "GenMsgNrOfRepetition" BO_ 1440 2;
BA_ "GenMsgILSupport" BO_ 1440 1;
BA_ "GenMsgStartDelayTime" BO_ 1440 100;
BA_ "GenMsgCycleTimeFast" BO_ 1440 20;
BA_ "GenMsgCycleTime" BO_ 1440 1000;
BA_ "GenMsgDelayTime" BO_ 1440 20;
BA_ "Type" BO_ 2651930624 8;
BA_ "GenMsgTimeoutTime" BO_ 2651930624 2500;
BA_ "GenMsgILSupport" BO_ 2651930624 1;
BA_ "GenMsgDelayTime" BO_ 2651930624 10;
BA_ "Type" BO_ 2651930681 11;
BA_ "GenMsgTimeoutTime" BO_ 2651930681 2500;
BA_ "GenMsgILSupport" BO_ 2651930681 1;
BA_ "Type" BO_ 2651930688 11;
BA_ "GenMsgTimeoutTime" BO_ 2651930688 2500;
BA_ "GenMsgILSupport" BO_ 2651930688 1;
BA_ "Type" BO_ 2651930627 11;
BA_ "GenMsgILSupport" BO_ 2651930627 1;
BA_ "Type" BO_ 2651930659 11;
BA_ "GenMsgTimeoutTime" BO_ 2651930659 2500;
BA_ "GenMsgILSupport" BO_ 2651930659 1;
BA_ "Period [ms]" BO_ 601 100;
BA_ "Type" BO_ 601 3;
BA_ "GenMsgSendType" BO_ 601 0;
BA_ "GenMsgNrOfRepetition" BO_ 601 3;
BA_ "GenMsgILSupport" BO_ 601 1;
BA_ "GenMsgStartDelayTime" BO_ 601 80;
BA_ "GenMsgCycleTimeFast" BO_ 601 20;
BA_ "GenMsgCycleTime" BO_ 601 100;
BA_ "GenMsgDelayTime" BO_ 601 20;
BA_ "Period [ms]" BO_ 598 100;
BA_ "Type" BO_ 598 3;
BA_ "GenMsgSendType" BO_ 598 0;
BA_ "GenMsgILSupport" BO_ 598 1;
BA_ "GenMsgStartDelayTime" BO_ 598 20;
BA_ "GenMsgCycleTime" BO_ 598 100;
BA_ "GenMsgDelayTime" BO_ 598 20;
BA_ "Period [ms]" BO_ 224 100;
BA_ "Type" BO_ 224 3;
BA_ "GenMsgSendType" BO_ 224 0;
BA_ "GenMsgILSupport" BO_ 224 1;
BA_ "GenMsgStartDelayTime" BO_ 224 10;
BA_ "GenMsgCycleTime" BO_ 224 100;
BA_ "GenMsgDelayTime" BO_ 224 20;
BA_ "Type" BO_ 2564554481 8;
BA_ "GenMsgTimeoutTime" BO_ 2564554481 2500;
BA_ "DiagState" BO_ 2564554481 1;
BA_ "DiagRequest" BO_ 2564440305 1;
BA_ "Type" BO_ 2564440305 8;
BA_ "DiagRequest" BO_ 2564441329 1;
BA_ "Type" BO_ 2564441329 8;
BA_ "DiagRequest" BO_ 2564434161 1;
BA_ "Type" BO_ 2564434161 8;
BA_ "DiagRequest" BO_ 2564434673 1;
BA_ "Type" BO_ 2564434673 8;
BA_ "GenMsgTimeoutTime" BO_ 2564434673 2500;
BA_ "DiagRequest" BO_ 2564436209 1;
BA_ "Type" BO_ 2564436209 8;
BA_ "DiagRequest" BO_ 2564440817 1;
BA_ "Type" BO_ 2564440817 8;
BA_ "Type" BO_ 2564502513 8;
BA_ "DiagState" BO_ 2564502513 1;
BA_ "DiagRequest" BO_ 2564436465 1;
BA_ "Type" BO_ 2564436465 8;
BA_ "DiagRequest" BO_ 2564444401 1;
BA_ "Type" BO_ 2564444401 8;
BA_ "DiagRequest" BO_ 2564448497 1;
BA_ "Type" BO_ 2564448497 8;
BA_ "DiagRequest" BO_ 2564473073 1;
BA_ "Type" BO_ 2564473073 8;
BA_ "DiagRequest" BO_ 2564464881 1;
BA_ "Type" BO_ 2564464881 8;
BA_ "DiagRequest" BO_ 2564444145 1;
BA_ "Type" BO_ 2564444145 8;
BA_ "DiagRequest" BO_ 2564475889 1;
BA_ "Type" BO_ 2564475889 5;
BA_ "GenMsgTimeoutTime" BO_ 2564475889 2500;
BA_ "DiagRequest" BO_ 2564431857 1;
BA_ "Type" BO_ 2564431857 8;
BA_ "DiagRequest" BO_ 2564474609 1;
BA_ "Type" BO_ 2564474609 8;
BA_ "DiagRequest" BO_ 2564445937 1;
BA_ "Type" BO_ 2564445937 8;
BA_ "DiagRequest" BO_ 2564446193 1;
BA_ "Type" BO_ 2564446193 8;
BA_ "Type" BO_ 2564485440 8;
BA_ "DiagResponse" BO_ 2564485440 1;
BA_ "Type" BO_ 2564485444 8;
BA_ "DiagResponse" BO_ 2564485444 1;
BA_ "Type" BO_ 2564485418 8;
BA_ "DiagResponse" BO_ 2564485418 1;
BA_ "Type" BO_ 2564485442 8;
BA_ "DiagResponse" BO_ 2564485442 1;
BA_ "Type" BO_ 2564485456 8;
BA_ "DiagResponse" BO_ 2564485456 1;
BA_ "Type" BO_ 2564485472 8;
BA_ "DiagResponse" BO_ 2564485472 1;
BA_ "Type" BO_ 2564485455 11;
BA_ "DiagResponse" BO_ 2564485455 1;
BA_ "Type" BO_ 2564485579 5;
BA_ "DiagResponse" BO_ 2564485579 1;
BA_ "GenMsgTimeoutTime" BO_ 2564485579 2500;
BA_ "Type" BO_ 2564485407 8;
BA_ "DiagResponse" BO_ 2564485407 1;
BA_ "Type" BO_ 2564485672 8;
BA_ "DiagResponse" BO_ 2564485672 1;
BA_ "Type" BO_ 2564485680 8;
BA_ "DiagResponse" BO_ 2564485680 1;
BA_ "Type" BO_ 2564485681 8;
BA_ "DiagResponse" BO_ 2564485681 1;
BA_ "Type" BO_ 2564485824 8;
BA_ "DiagResponse" BO_ 2564485824 1;
BA_ "Type" BO_ 2564485792 8;
BA_ "DiagResponse" BO_ 2564485792 1;
BA_ "Type" BO_ 2564485574 8;
BA_ "DiagResponse" BO_ 2564485574 1;
BA_ "Type" BO_ 2564485462 11;
BA_ "DiagResponse" BO_ 2564485462 1;
BA_ "Type" BO_ 2564485463 11;
BA_ "DiagResponse" BO_ 2564485463 1;
BA_ "Period [ms]" BO_ 252 10;
BA_ "Type" BO_ 252 1;
BA_ "GenMsgSendType" BO_ 252 0;
BA_ "GenMsgILSupport" BO_ 252 1;
BA_ "GenMsgStartDelayTime" BO_ 252 4;
BA_ "GenMsgCycleTime" BO_ 252 10;
BA_ "Period [ms]" BO_ 1445 1000;
BA_ "Type" BO_ 1445 3;
BA_ "GenMsgSendType" BO_ 1445 0;
BA_ "GenMsgILSupport" BO_ 1445 1;
BA_ "GenMsgCycleTime" BO_ 1445 1000;
BA_ "GenMsgDelayTime" BO_ 1445 20;
BA_ "Period [ms]" BO_ 496 20;
BA_ "Type" BO_ 496 1;
BA_ "GenMsgSendType" BO_ 496 0;
BA_ "GenMsgTimeoutTime" BO_ 496 2500;
BA_ "GenMsgILSupport" BO_ 496 1;
BA_ "GenMsgCycleTime" BO_ 496 20;
BA_ "Period [ms]" BO_ 550 1000;
BA_ "Type" BO_ 550 3;
BA_ "GenMsgSendType" BO_ 550 0;
BA_ "GenMsgILSupport" BO_ 550 1;
BA_ "GenMsgCycleTime" BO_ 550 1000;
BA_ "GenMsgDelayTime" BO_ 550 20;
BA_ "Period [ms]" BO_ 1854 250;
BA_ "Type" BO_ 1854 3;
BA_ "GenMsgSendType" BO_ 1854 0;
BA_ "GenMsgILSupport" BO_ 1854 1;
BA_ "GenMsgCycleTime" BO_ 1854 250;
BA_ "GenMsgDelayTime" BO_ 1854 20;
BA_ "Type" BO_ 222 11;
BA_ "GenMsgTimeoutTime" BO_ 222 2500;
BA_ "GenMsgILSupport" BO_ 222 1;
BA_ "Type" BO_ 1896 11;
BA_ "GenMsgTimeoutTime" BO_ 1896 2500;
BA_ "GenMsgILSupport" BO_ 1896 1;
BA_ "GenMsgDelayTime" BO_ 1896 20;
BA_ "Period [ms]" BO_ 701 100;
BA_ "Type" BO_ 701 1;
BA_ "GenMsgSendType" BO_ 701 0;
BA_ "GenMsgTimeoutTime" BO_ 701 2500;
BA_ "GenMsgILSupport" BO_ 701 1;
BA_ "GenMsgStartDelayTime" BO_ 701 75;
BA_ "GenMsgCycleTime" BO_ 701 100;
BA_ "Period [ms]" BO_ 1377 1000;
BA_ "Type" BO_ 1377 3;
BA_ "GenMsgSendType" BO_ 1377 0;
BA_ "GenMsgTimeoutTime" BO_ 1377 2500;
BA_ "GenMsgILSupport" BO_ 1377 1;
BA_ "GenMsgCycleTime" BO_ 1377 1000;
BA_ "GenMsgDelayTime" BO_ 1377 10;
BA_ "Period [ms]" BO_ 1378 1000;
BA_ "Type" BO_ 1378 3;
BA_ "GenMsgSendType" BO_ 1378 0;
BA_ "GenMsgTimeoutTime" BO_ 1378 2500;
BA_ "GenMsgILSupport" BO_ 1378 1;
BA_ "GenMsgCycleTime" BO_ 1378 1000;
BA_ "GenMsgDelayTime" BO_ 1378 20;
BA_ "Period [ms]" BO_ 1425 1000;
BA_ "Type" BO_ 1425 3;
BA_ "GenMsgSendType" BO_ 1425 0;
BA_ "GenMsgILSupport" BO_ 1425 1;
BA_ "GenMsgCycleTime" BO_ 1425 1000;
BA_ "GenMsgDelayTime" BO_ 1425 100;
BA_ "Period [ms]" BO_ 654 100;
BA_ "Type" BO_ 654 1;
BA_ "GenMsgSendType" BO_ 654 0;
BA_ "GenMsgTimeoutTime" BO_ 654 2500;
BA_ "GenMsgILSupport" BO_ 654 1;
BA_ "GenMsgStartDelayTime" BO_ 654 25;
BA_ "GenMsgCycleTime" BO_ 654 100;
BA_ "Period [ms]" BO_ 878 500;
BA_ "Type" BO_ 878 1;
BA_ "GenMsgSendType" BO_ 878 0;
BA_ "GenMsgTimeoutTime" BO_ 878 2500;
BA_ "GenMsgILSupport" BO_ 878 1;
BA_ "GenMsgStartDelayTime" BO_ 878 200;
BA_ "GenMsgCycleTime" BO_ 878 500;
BA_ "Period [ms]" BO_ 1598 500;
BA_ "Type" BO_ 1598 1;
BA_ "GenMsgSendType" BO_ 1598 0;
BA_ "GenMsgILSupport" BO_ 1598 1;
BA_ "GenMsgCycleTime" BO_ 1598 500;
BA_ "Period [ms]" BO_ 1465 1000;
BA_ "Type" BO_ 1465 3;
BA_ "GenMsgSendType" BO_ 1465 0;
BA_ "GenMsgILSupport" BO_ 1465 1;
BA_ "GenMsgCycleTime" BO_ 1465 1000;
BA_ "GenMsgDelayTime" BO_ 1465 20;
BA_ "GenSigStartValue" SG_ 599 AirBagFailSts 2;
BA_ "Event trans." SG_ 599 PsngrBagChargeSts 0;
BA_ "GenSigStartValue" SG_ 599 PsngrBagChargeSts 3;
BA_ "GenSigSendType" SG_ 599 PsngrBagChargeSts 4;
BA_ "Event trans." SG_ 599 SBR1RowCentralSeatBuckleFailSts 0;
BA_ "GenSigStartValue" SG_ 599 SBR1RowCentralSeatBuckleFailSts 3;
BA_ "GenSigSendType" SG_ 599 SBR1RowCentralSeatBuckleFailSts 4;
BA_ "Event trans." SG_ 599 SBR1RowCentralSeatPPDFailSts 0;
BA_ "GenSigStartValue" SG_ 599 SBR1RowCentralSeatPPDFailSts 3;
BA_ "GenSigSendType" SG_ 599 SBR1RowCentralSeatPPDFailSts 4;
BA_ "Event trans." SG_ 599 SBR1RowCentralSeatSts 0;
BA_ "GenSigStartValue" SG_ 599 SBR1RowCentralSeatSts 7;
BA_ "GenSigSendType" SG_ 599 SBR1RowCentralSeatSts 4;
BA_ "Event trans." SG_ 599 SBR1RowDriverSeatFailSts 0;
BA_ "GenSigStartValue" SG_ 599 SBR1RowDriverSeatFailSts 3;
BA_ "GenSigSendType" SG_ 599 SBR1RowDriverSeatFailSts 4;
BA_ "Event trans." SG_ 599 SBR1RowDriverSeatSts 0;
BA_ "GenSigStartValue" SG_ 599 SBR1RowDriverSeatSts 3;
BA_ "GenSigSendType" SG_ 599 SBR1RowDriverSeatSts 4;
BA_ "Event trans." SG_ 599 SBR1RowPsngrSeatBuckleFailSts 0;
BA_ "GenSigStartValue" SG_ 599 SBR1RowPsngrSeatBuckleFailSts 3;
BA_ "GenSigSendType" SG_ 599 SBR1RowPsngrSeatBuckleFailSts 4;
BA_ "Event trans." SG_ 599 SBR1RowPsngrSeatPPDFailSts 0;
BA_ "GenSigStartValue" SG_ 599 SBR1RowPsngrSeatPPDFailSts 3;
BA_ "GenSigSendType" SG_ 599 SBR1RowPsngrSeatPPDFailSts 4;
BA_ "Event trans." SG_ 599 SBR1RowPsngrSeatSts 0;
BA_ "GenSigStartValue" SG_ 599 SBR1RowPsngrSeatSts 7;
BA_ "GenSigSendType" SG_ 599 SBR1RowPsngrSeatSts 4;
BA_ "Event trans." SG_ 599 SBR2RowCentralSeatSts 0;
BA_ "GenSigStartValue" SG_ 599 SBR2RowCentralSeatSts 3;
BA_ "GenSigSendType" SG_ 599 SBR2RowCentralSeatSts 4;
BA_ "Event trans." SG_ 599 SBR2RowLeftSeatSts 0;
BA_ "GenSigStartValue" SG_ 599 SBR2RowLeftSeatSts 3;
BA_ "GenSigSendType" SG_ 599 SBR2RowLeftSeatSts 4;
BA_ "Event trans." SG_ 599 SBR2RowRightSeatSts 0;
BA_ "GenSigStartValue" SG_ 599 SBR2RowRightSeatSts 3;
BA_ "GenSigSendType" SG_ 599 SBR2RowRightSeatSts 4;
BA_ "Event trans." SG_ 1447 DrvSbltUnFltr 0;
BA_ "GenSigSendType" SG_ 1447 DrvSbltUnFltr 3;
BA_ "Accuracy" SG_ 1050 BatteryCurrentLevel "+/-1%";
BA_ "Accuracy" SG_ 1050 BatteryTemperature "6";
BA_ "Accuracy" SG_ 1050 StateOfCharge "1%";
BA_ "GenSigStartValue" SG_ 1050 StateOfCharge 100;
BA_ "Accuracy" SG_ 250 CmdIgn_FailSts "-";
BA_ "Accuracy" SG_ 250 CmdIgnSts "-";
BA_ "Accuracy" SG_ 250 EngineOffRequest "-";
BA_ "Accuracy" SG_ 250 MessageCounter_BC "-";
BA_ "Accuracy" SG_ 250 TurnIndicatorSts "-";
BA_ "Accuracy" SG_ 1994 IgnitionOnCounter "-";
BA_ "Event trans." SG_ 1444 AirHtwPwrTgt 0;
BA_ "GenSigSendType" SG_ 1444 AirHtwPwrTgt 3;
BA_ "Event trans." SG_ 1444 PreCondCabinSts 0;
BA_ "GenSigSendType" SG_ 1444 PreCondCabinSts 3;
BA_ "Event trans." SG_ 1200 ChargeNow 0;
BA_ "GenSigSendType" SG_ 1200 ChargeNow 3;
BA_ "Event trans." SG_ 1200 ChargeNow_TBM 0;
BA_ "GenSigSendType" SG_ 1200 ChargeNow_TBM 3;
BA_ "Event trans." SG_ 1472 CustKeyInIgnSts 0;
BA_ "GenSigSendType" SG_ 1472 CustKeyInIgnSts 3;
BA_ "Event trans." SG_ 1472 FobSearchResult 0;
BA_ "GenSigSendType" SG_ 1472 FobSearchResult 3;
BA_ "Event trans." SG_ 1472 IgnPosSts 0;
BA_ "GenSigSendType" SG_ 1472 IgnPosSts 3;
BA_ "Event trans." SG_ 1472 MemRq_FobNum 0;
BA_ "GenSigSendType" SG_ 1472 MemRq_FobNum 3;
BA_ "Event trans." SG_ 1472 RFFuncReq 0;
BA_ "GenSigSendType" SG_ 1472 RFFuncReq 3;
BA_ "Event trans." SG_ 1472 RFReq 0;
BA_ "GenSigSendType" SG_ 1472 RFReq 3;
BA_ "Event trans." SG_ 1470 LockUnlockVehicleSts 0;
BA_ "GenSigSendType" SG_ 1470 LockUnlockVehicleSts 4;
BA_ "Event trans." SG_ 900 DriveStyleSts 0;
BA_ "GenSigSendType" SG_ 900 DriveStyleSts 3;
BA_ "Event trans." SG_ 900 DsuRequest 0;
BA_ "GenSigSendType" SG_ 900 DsuRequest 3;
BA_ "GenSigStartValue" SG_ 900 ExternalTemperature 511;
BA_ "Event trans." SG_ 900 LDWRequestSts 0;
BA_ "GenSigSendType" SG_ 900 LDWRequestSts 3;
BA_ "Event trans." SG_ 900 ParkBrakeSts 0;
BA_ "GenSigSendType" SG_ 900 ParkBrakeSts 3;
BA_ "Event trans." SG_ 900 SportAvailable 0;
BA_ "GenSigStartValue" SG_ 900 SportAvailable 1;
BA_ "GenSigSendType" SG_ 900 SportAvailable 3;
BA_ "GenSigStartValue" SG_ 1349 InternalLightLevel 5;
BA_ "Event trans." SG_ 1201 BonnetFailSts 0;
BA_ "GenSigSendType" SG_ 1201 BonnetFailSts 3;
BA_ "Event trans." SG_ 1201 BrakeFluidLevelSts 0;
BA_ "GenSigSendType" SG_ 1201 BrakeFluidLevelSts 3;
BA_ "Event trans." SG_ 1201 CompressorACReqSts 0;
BA_ "GenSigSendType" SG_ 1201 CompressorACReqSts 3;
BA_ "Event trans." SG_ 1201 DriverDoorFailSts 0;
BA_ "GenSigSendType" SG_ 1201 DriverDoorFailSts 3;
BA_ "Event trans." SG_ 1201 DriverDoorSts 0;
BA_ "GenSigSendType" SG_ 1201 DriverDoorSts 3;
BA_ "Event trans." SG_ 1201 ExteriorRearReleaseSwitchSts 0;
BA_ "GenSigSendType" SG_ 1201 ExteriorRearReleaseSwitchSts 3;
BA_ "Event trans." SG_ 1201 PreCond_InhibitSts 0;
BA_ "GenSigSendType" SG_ 1201 PreCond_InhibitSts 3;
BA_ "Event trans." SG_ 1201 PreCondActvSts 0;
BA_ "GenSigSendType" SG_ 1201 PreCondActvSts 3;
BA_ "Event trans." SG_ 1201 RemStActvSts 0;
BA_ "GenSigSendType" SG_ 1201 RemStActvSts 3;
BA_ "GenSigStartValue" SG_ 257 VehicleStandStillSts 1;
BA_ "GenSigStartValue" SG_ 506 BrkPdl_Stat 3;
BA_ "GenSigStartValue" SG_ 259 BrakeTravelSts 254;
BA_ "GenSigStartValue" SG_ 259 MuSplit 3;
BA_ "GenSigStartValue" SG_ 259 OverSteering 63;
BA_ "GenSigStartValue" SG_ 259 UnderSteering 63;
BA_ "GenSigStartValue" SG_ 501 VehicleStandStillSts 1;
BA_ "Accuracy" SG_ 498 ACC_Wheel_Torque_BSM "-";
BA_ "Accuracy" SG_ 498 ACC_Wheel_Torque_Enabled_BSM "-";
BA_ "Event trans." SG_ 1048 ASRActive 0;
BA_ "GenSigSendType" SG_ 1048 ASRActive 3;
BA_ "Event trans." SG_ 1048 HNGActive 0;
BA_ "GenSigSendType" SG_ 1048 HNGActive 3;
BA_ "Event trans." SG_ 1048 MSRActive 0;
BA_ "GenSigSendType" SG_ 1048 MSRActive 3;
BA_ "Event trans." SG_ 1199 ABSFailSts 0;
BA_ "GenSigSendType" SG_ 1199 ABSFailSts 4;
BA_ "Event trans." SG_ 1199 BSM_BLC_Active 0;
BA_ "GenSigSendType" SG_ 1199 BSM_BLC_Active 4;
BA_ "Event trans." SG_ 1199 BSMSysSts 0;
BA_ "GenSigSendType" SG_ 1199 BSMSysSts 4;
BA_ "Event trans." SG_ 1199 CMMIntervention 0;
BA_ "GenSigSendType" SG_ 1199 CMMIntervention 4;
BA_ "Event trans." SG_ 1199 EBDFailSts 0;
BA_ "GenSigSendType" SG_ 1199 EBDFailSts 4;
BA_ "Event trans." SG_ 1199 ERMActive 0;
BA_ "GenSigSendType" SG_ 1199 ERMActive 4;
BA_ "Event trans." SG_ 1199 ESCFailSts 0;
BA_ "GenSigSendType" SG_ 1199 ESCFailSts 4;
BA_ "Event trans." SG_ 1199 ESCIntervention 0;
BA_ "GenSigSendType" SG_ 1199 ESCIntervention 4;
BA_ "Event trans." SG_ 1199 Function2Sts 0;
BA_ "GenSigSendType" SG_ 1199 Function2Sts 4;
BA_ "Event trans." SG_ 1199 FunctionFailSts 0;
BA_ "GenSigSendType" SG_ 1199 FunctionFailSts 4;
BA_ "Event trans." SG_ 1199 FunctionIntervention 0;
BA_ "GenSigSendType" SG_ 1199 FunctionIntervention 4;
BA_ "Event trans." SG_ 1199 FunctionSts 0;
BA_ "GenSigSendType" SG_ 1199 FunctionSts 4;
BA_ "Event trans." SG_ 1199 HillHolderFailSts 0;
BA_ "GenSigSendType" SG_ 1199 HillHolderFailSts 4;
BA_ "Event trans." SG_ 1199 RollsModeAct 0;
BA_ "GenSigSendType" SG_ 1199 RollsModeAct 4;
BA_ "Event trans." SG_ 1199 TSCActive 0;
BA_ "GenSigSendType" SG_ 1199 TSCActive 4;
BA_ "Event trans." SG_ 1199 TyreInflationState_LHF_Tyre 0;
BA_ "GenSigSendType" SG_ 1199 TyreInflationState_LHF_Tyre 4;
BA_ "Event trans." SG_ 1199 TyreInflationState_LHR_Tyre 0;
BA_ "GenSigSendType" SG_ 1199 TyreInflationState_LHR_Tyre 4;
BA_ "Event trans." SG_ 1199 TyreInflationState_RHF_Tyre 0;
BA_ "GenSigSendType" SG_ 1199 TyreInflationState_RHF_Tyre 4;
BA_ "Event trans." SG_ 1199 TyreInflationState_RHR_Tyre 0;
BA_ "GenSigSendType" SG_ 1199 TyreInflationState_RHR_Tyre 4;
BA_ "Event trans." SG_ 1199 TyrePressureSystemFailSts 0;
BA_ "GenSigSendType" SG_ 1199 TyrePressureSystemFailSts 4;
BA_ "Accuracy" SG_ 254 CRC_BYD "1";
BA_ "Accuracy" SG_ 254 InternalError_BSM "-";
BA_ "Accuracy" SG_ 254 LatAcceleration_BSM "0,02";
BA_ "Accuracy" SG_ 254 LatAccelerationFailSts_BSM "-";
BA_ "Accuracy" SG_ 254 LongAcceleration_BSM "0,02";
BA_ "Accuracy" SG_ 254 LongAccelerationFailSts_BSM "-";
BA_ "Accuracy" SG_ 254 MessageCounter_BYD "1";
BA_ "Accuracy" SG_ 254 YawRate_BSM "0,08";
BA_ "Accuracy" SG_ 254 YawRateFailSts_BSM "-";
BA_ "Event trans." SG_ 1440 ACC_RadarBlinded 0;
BA_ "GenSigStartValue" SG_ 1440 ACC_RadarBlinded 1;
BA_ "GenSigSendType" SG_ 1440 ACC_RadarBlinded 4;
BA_ "Event trans." SG_ 1440 ACC_SetSpeedKPH 0;
BA_ "GenSigSendType" SG_ 1440 ACC_SetSpeedKPH 4;
BA_ "Event trans." SG_ 1440 ACC_SetSpeedMPH 0;
BA_ "GenSigSendType" SG_ 1440 ACC_SetSpeedMPH 4;
BA_ "Event trans." SG_ 1440 ACCFailSts 0;
BA_ "GenSigSendType" SG_ 1440 ACCFailSts 4;
BA_ "Event trans." SG_ 1440 ACCSystemSts 0;
BA_ "GenSigSendType" SG_ 1440 ACCSystemSts 4;
BA_ "Event trans." SG_ 1440 AEBFailSts 0;
BA_ "GenSigStartValue" SG_ 1440 AEBFailSts 1;
BA_ "GenSigSendType" SG_ 1440 AEBFailSts 4;
BA_ "Event trans." SG_ 1440 AEBTemporaryFailSts 0;
BA_ "GenSigStartValue" SG_ 1440 AEBTemporaryFailSts 1;
BA_ "GenSigSendType" SG_ 1440 AEBTemporaryFailSts 4;
BA_ "Event trans." SG_ 1440 CameraBlinded 0;
BA_ "GenSigStartValue" SG_ 1440 CameraBlinded 1;
BA_ "GenSigSendType" SG_ 1440 CameraBlinded 4;
BA_ "Event trans." SG_ 1440 CameraBlocked 0;
BA_ "GenSigStartValue" SG_ 1440 CameraBlocked 1;
BA_ "GenSigSendType" SG_ 1440 CameraBlocked 4;
BA_ "Event trans." SG_ 1440 FCWSystemSts 0;
BA_ "GenSigStartValue" SG_ 1440 FCWSystemSts 3;
BA_ "GenSigSendType" SG_ 1440 FCWSystemSts 4;
BA_ "Event trans." SG_ 1440 HMICode_ACC 0;
BA_ "GenSigSendType" SG_ 1440 HMICode_ACC 4;
BA_ "Event trans." SG_ 1440 HMICode_FCW 0;
BA_ "GenSigSendType" SG_ 1440 HMICode_FCW 4;
BA_ "Event trans." SG_ 1440 HMIDisplay_ACC 0;
BA_ "GenSigSendType" SG_ 1440 HMIDisplay_ACC 4;
BA_ "Event trans." SG_ 1440 iACCSts 0;
BA_ "GenSigSendType" SG_ 1440 iACCSts 4;
BA_ "Event trans." SG_ 2651930624 Digit_01 0;
BA_ "GenSigSendType" SG_ 2651930624 Digit_01 1;
BA_ "Accuracy" SG_ 2651930681 Digit_01_DASM "-";
BA_ "Event trans." SG_ 2651930681 Digit_01_DASM 0;
BA_ "GenSigSendType" SG_ 2651930681 Digit_01_DASM 1;
BA_ "Accuracy" SG_ 2651930681 Digit_02_DASM "-";
BA_ "Accuracy" SG_ 2651930681 Digit_03_DASM "-";
BA_ "Accuracy" SG_ 2651930681 Digit_04_DASM "-";
BA_ "Accuracy" SG_ 2651930681 Digit_05_DASM "-";
BA_ "Accuracy" SG_ 2651930681 Digit_06_DASM "-";
BA_ "Accuracy" SG_ 2651930681 Digit_07_DASM "-";
BA_ "Accuracy" SG_ 2651930681 Digit_08_DASM "-";
BA_ "Accuracy" SG_ 2651930681 Digit_09_DASM "-";
BA_ "Accuracy" SG_ 2651930681 Digit_10_DASM "-";
BA_ "Accuracy" SG_ 2651930681 Digit_11_DASM "-";
BA_ "Accuracy" SG_ 2651930688 Digit_01_EVCU "-";
BA_ "Event trans." SG_ 2651930688 Digit_01_EVCU 0;
BA_ "GenSigSendType" SG_ 2651930688 Digit_01_EVCU 1;
BA_ "Accuracy" SG_ 2651930688 Digit_02_EVCU "-";
BA_ "Accuracy" SG_ 2651930688 Digit_03_EVCU "-";
BA_ "Accuracy" SG_ 2651930688 Digit_04_EVCU "-";
BA_ "Accuracy" SG_ 2651930688 Digit_05_EVCU "-";
BA_ "Accuracy" SG_ 2651930688 Digit_06_EVCU "-";
BA_ "Accuracy" SG_ 2651930688 Digit_07_EVCU "-";
BA_ "Accuracy" SG_ 2651930688 Digit_08_EVCU "-";
BA_ "Accuracy" SG_ 2651930688 Digit_09_EVCU "-";
BA_ "Accuracy" SG_ 2651930688 Digit_10_EVCU "-";
BA_ "Accuracy" SG_ 2651930688 Digit_11_EVCU "-";
BA_ "Accuracy" SG_ 2651930627 Digit_01_IPC "-";
BA_ "Event trans." SG_ 2651930627 Digit_01_IPC 0;
BA_ "GenSigSendType" SG_ 2651930627 Digit_01_IPC 1;
BA_ "Accuracy" SG_ 2651930627 Digit_02_IPC "-";
BA_ "Accuracy" SG_ 2651930627 Digit_03_IPC "-";
BA_ "Accuracy" SG_ 2651930627 Digit_04_IPC "-";
BA_ "Accuracy" SG_ 2651930627 Digit_05_IPC "-";
BA_ "Accuracy" SG_ 2651930627 Digit_06_IPC "-";
BA_ "Accuracy" SG_ 2651930627 Digit_07_IPC "-";
BA_ "Accuracy" SG_ 2651930627 Digit_08_IPC "-";
BA_ "Accuracy" SG_ 2651930627 Digit_09_IPC "-";
BA_ "Accuracy" SG_ 2651930627 Digit_10_IPC "-";
BA_ "Accuracy" SG_ 2651930627 Digit_11_IPC "-";
BA_ "Accuracy" SG_ 2651930659 Digit_01_TBM "-";
BA_ "Event trans." SG_ 2651930659 Digit_01_TBM 0;
BA_ "GenSigSendType" SG_ 2651930659 Digit_01_TBM 1;
BA_ "Accuracy" SG_ 2651930659 Digit_02_TBM "-";
BA_ "Accuracy" SG_ 2651930659 Digit_03_TBM "-";
BA_ "Accuracy" SG_ 2651930659 Digit_04_TBM "-";
BA_ "Accuracy" SG_ 2651930659 Digit_05_TBM "-";
BA_ "Accuracy" SG_ 2651930659 Digit_06_TBM "-";
BA_ "Accuracy" SG_ 2651930659 Digit_07_TBM "-";
BA_ "Accuracy" SG_ 2651930659 Digit_08_TBM "-";
BA_ "Accuracy" SG_ 2651930659 Digit_09_TBM "-";
BA_ "Accuracy" SG_ 2651930659 Digit_10_TBM "-";
BA_ "Accuracy" SG_ 2651930659 Digit_11_TBM "-";
BA_ "Event trans." SG_ 601 PowerLimit_Requested 0;
BA_ "GenSigSendType" SG_ 601 PowerLimit_Requested 3;
BA_ "Event trans." SG_ 601 SpeedUnit 0;
BA_ "GenSigSendType" SG_ 601 SpeedUnit 3;
BA_ "GenSigStartValue" SG_ 598 FSFCWPlusActivationMode 1;
BA_ "GenSigStartValue" SG_ 598 FSFCWPlusSetting 3;
BA_ "Event trans." SG_ 598 PowerModeSts_IPC 0;
BA_ "GenSigSendType" SG_ 598 PowerModeSts_IPC 3;
BA_ "Event trans." SG_ 598 PsngrBagRequestSts 0;
BA_ "GenSigSendType" SG_ 598 PsngrBagRequestSts 3;
BA_ "GenSigStartValue" SG_ 598 RemoteDoorUnlock 1;
BA_ "Event trans." SG_ 598 TPICalibrationReqSts 0;
BA_ "GenSigSendType" SG_ 598 TPICalibrationReqSts 3;
BA_ "Event trans." SG_ 224 AutoHold 0;
BA_ "GenSigStartValue" SG_ 224 AutoHold 1;
BA_ "GenSigSendType" SG_ 224 AutoHold 3;
BA_ "Event trans." SG_ 224 DisplayedSpeedSign 0;
BA_ "GenSigSendType" SG_ 224 DisplayedSpeedSign 3;
BA_ "Event trans." SG_ 224 NewSpdZoneInd 0;
BA_ "GenSigStartValue" SG_ 224 NewSpdZoneInd 1;
BA_ "GenSigSendType" SG_ 224 NewSpdZoneInd 3;
BA_ "Event trans." SG_ 224 SignCaptureMode 0;
BA_ "GenSigSendType" SG_ 224 SignCaptureMode 3;
BA_ "Accuracy" SG_ 2564448497 N_PDU "-";
BA_ "Accuracy" SG_ 2564474609 N_PDU "-";
BA_ "Accuracy" SG_ 2564485472 N_PDU "-";
BA_ "Accuracy" SG_ 2564485574 N_PDU "-";
BA_ "Accuracy" SG_ 1445 CC_SetSpdDspl_KPH "-";
BA_ "Event trans." SG_ 1445 CC_SetSpdDspl_KPH 0;
BA_ "GenSigSendType" SG_ 1445 CC_SetSpdDspl_KPH 3;
BA_ "Accuracy" SG_ 1445 CC_SetSpdDspl_MPH "-";
BA_ "Event trans." SG_ 1445 CC_SetSpdDspl_MPH 0;
BA_ "GenSigSendType" SG_ 1445 CC_SetSpdDspl_MPH 3;
BA_ "Accuracy" SG_ 1445 CruiseControlLampSts "-";
BA_ "Event trans." SG_ 1445 CruiseControlLampSts 0;
BA_ "GenSigSendType" SG_ 1445 CruiseControlLampSts 3;
BA_ "Accuracy" SG_ 1445 CruiseControlSts "-";
BA_ "Event trans." SG_ 1445 CruiseControlSts 0;
BA_ "GenSigSendType" SG_ 1445 CruiseControlSts 3;
BA_ "Event trans." SG_ 1445 ISASts 0;
BA_ "GenSigSendType" SG_ 1445 ISASts 3;
BA_ "Accuracy" SG_ 1445 Override "-";
BA_ "Event trans." SG_ 1445 Override 0;
BA_ "GenSigSendType" SG_ 1445 Override 3;
BA_ "Accuracy" SG_ 1445 SpeedLimitSts "-";
BA_ "Event trans." SG_ 1445 SpeedLimitSts 0;
BA_ "GenSigStartValue" SG_ 1445 SpeedLimitSts 2;
BA_ "GenSigSendType" SG_ 1445 SpeedLimitSts 3;
BA_ "Accuracy" SG_ 496 ActualPedalPos "-";
BA_ "GenSigStartValue" SG_ 496 ActualPedalPos 1;
BA_ "Event trans." SG_ 550 ECM_WARN 0;
BA_ "GenSigSendType" SG_ 550 ECM_WARN 3;
BA_ "Accuracy" SG_ 1854 HighBeamSts "-";
BA_ "Event trans." SG_ 1854 HighBeamSts 0;
BA_ "GenSigSendType" SG_ 1854 HighBeamSts 3;
BA_ "Accuracy" SG_ 1854 LHParkingLightSts "-";
BA_ "Event trans." SG_ 1854 LHParkingLightSts 0;
BA_ "GenSigSendType" SG_ 1854 LHParkingLightSts 3;
BA_ "Accuracy" SG_ 1854 LHTurnLightFault "-";
BA_ "Accuracy" SG_ 1854 LHTurnSignalSts "-";
BA_ "Event trans." SG_ 1854 LHTurnSignalSts 0;
BA_ "GenSigSendType" SG_ 1854 LHTurnSignalSts 3;
BA_ "Accuracy" SG_ 1854 ParkingLightFault "-";
BA_ "Accuracy" SG_ 1854 RHParkingLightSts "-";
BA_ "Event trans." SG_ 1854 RHParkingLightSts 0;
BA_ "GenSigSendType" SG_ 1854 RHParkingLightSts 3;
BA_ "Accuracy" SG_ 1854 RHTurnLightFault "-";
BA_ "Accuracy" SG_ 1854 RHTurnSignalSts "-";
BA_ "Event trans." SG_ 1854 RHTurnSignalSts 0;
BA_ "GenSigSendType" SG_ 1854 RHTurnSignalSts 3;
BA_ "Accuracy" SG_ 1854 StopLightFault "-";
BA_ "Accuracy" SG_ 1854 StopLightSts "-";
BA_ "Event trans." SG_ 1854 StopLightSts 0;
BA_ "GenSigSendType" SG_ 1854 StopLightSts 3;
BA_ "Accuracy" SG_ 222 CRC_G "-";
BA_ "Event trans." SG_ 222 CRC_G 0;
BA_ "GenSigSendType" SG_ 222 CRC_G 1;
BA_ "Accuracy" SG_ 222 ElectricSteeringFailSts "-";
BA_ "Event trans." SG_ 222 ElectricSteeringFailSts 0;
BA_ "GenSigSendType" SG_ 222 ElectricSteeringFailSts 1;
BA_ "Accuracy" SG_ 222 LwsAngle "+/- 2.8°";
BA_ "Event trans." SG_ 222 LwsAngle 0;
BA_ "GenSigSendType" SG_ 222 LwsAngle 1;
BA_ "Accuracy" SG_ 222 LwsCalibration "-";
BA_ "Event trans." SG_ 222 LwsCalibration 0;
BA_ "GenSigSendType" SG_ 222 LwsCalibration 1;
BA_ "Accuracy" SG_ 222 LWSFailSts "-";
BA_ "Event trans." SG_ 222 LWSFailSts 0;
BA_ "GenSigSendType" SG_ 222 LWSFailSts 1;
BA_ "Accuracy" SG_ 222 LwsSpeed "15 °/s";
BA_ "Event trans." SG_ 222 LwsSpeed 0;
BA_ "GenSigSendType" SG_ 222 LwsSpeed 1;
BA_ "Accuracy" SG_ 222 MessageCounter_G "-";
BA_ "Event trans." SG_ 222 MessageCounter_G 0;
BA_ "GenSigSendType" SG_ 222 MessageCounter_G 1;
BA_ "Accuracy" SG_ 1896 GPS_POS3_Date_Day "1";
BA_ "Event trans." SG_ 1896 GPS_POS3_Date_Day 0;
BA_ "GenSigStartValue" SG_ 1896 GPS_POS3_Date_Day 255;
BA_ "GenSigSendType" SG_ 1896 GPS_POS3_Date_Day 1;
BA_ "Accuracy" SG_ 1896 GPS_POS3_Date_Hour "1";
BA_ "Event trans." SG_ 1896 GPS_POS3_Date_Hour 0;
BA_ "GenSigStartValue" SG_ 1896 GPS_POS3_Date_Hour 255;
BA_ "GenSigSendType" SG_ 1896 GPS_POS3_Date_Hour 1;
BA_ "Accuracy" SG_ 1896 GPS_POS3_Date_Minutes "1";
BA_ "Event trans." SG_ 1896 GPS_POS3_Date_Minutes 0;
BA_ "GenSigStartValue" SG_ 1896 GPS_POS3_Date_Minutes 255;
BA_ "GenSigSendType" SG_ 1896 GPS_POS3_Date_Minutes 1;
BA_ "Accuracy" SG_ 1896 GPS_POS3_Date_Month "1";
BA_ "Event trans." SG_ 1896 GPS_POS3_Date_Month 0;
BA_ "GenSigStartValue" SG_ 1896 GPS_POS3_Date_Month 255;
BA_ "GenSigSendType" SG_ 1896 GPS_POS3_Date_Month 1;
BA_ "Accuracy" SG_ 1896 GPS_POS3_Date_Seconds "0.01";
BA_ "Event trans." SG_ 1896 GPS_POS3_Date_Seconds 0;
BA_ "GenSigStartValue" SG_ 1896 GPS_POS3_Date_Seconds 65535;
BA_ "GenSigSendType" SG_ 1896 GPS_POS3_Date_Seconds 1;
BA_ "Accuracy" SG_ 1896 GPS_POS3_Date_Year "1";
BA_ "Event trans." SG_ 1896 GPS_POS3_Date_Year 0;
BA_ "GenSigStartValue" SG_ 1896 GPS_POS3_Date_Year 65535;
BA_ "GenSigSendType" SG_ 1896 GPS_POS3_Date_Year 1;
BA_ "Event trans." SG_ 1377 Cabin_Condition_Sts 0;
BA_ "GenSigSendType" SG_ 1377 Cabin_Condition_Sts 3;
BA_ "Event trans." SG_ 1377 ChargingSysSts 0;
BA_ "GenSigSendType" SG_ 1377 ChargingSysSts 3;
BA_ "Event trans." SG_ 1377 CompStat 0;
BA_ "GenSigSendType" SG_ 1377 CompStat 3;
BA_ "Event trans." SG_ 1377 DriveReady 0;
BA_ "GenSigSendType" SG_ 1377 DriveReady 3;
BA_ "Event trans." SG_ 1377 EstTimeofChrg_Lv1 0;
BA_ "GenSigSendType" SG_ 1377 EstTimeofChrg_Lv1 3;
BA_ "Event trans." SG_ 1377 EstTimeofChrg_Lv2 0;
BA_ "GenSigSendType" SG_ 1377 EstTimeofChrg_Lv2 3;
BA_ "Event trans." SG_ 1377 HVBatCntctrStat 0;
BA_ "GenSigSendType" SG_ 1377 HVBatCntctrStat 3;
BA_ "Event trans." SG_ 1377 MIL_OnRq_BPCM 0;
BA_ "GenSigSendType" SG_ 1377 MIL_OnRq_BPCM 3;
BA_ "Event trans." SG_ 1377 PrplsnSysAtv 0;
BA_ "GenSigSendType" SG_ 1377 PrplsnSysAtv 3;
BA_ "GenSigStartValue" SG_ 1377 Service_Battery_Recharge_FailSts 1;
BA_ "GenSigStartValue" SG_ 1378 AirHtrCoreTemp 255;
BA_ "GenSigStartValue" SG_ 1378 AirHtrPCBTemp 255;
BA_ "Event trans." SG_ 1378 AirHtrPwrCnsAct 0;
BA_ "GenSigSendType" SG_ 1378 AirHtrPwrCnsAct 3;
BA_ "Event trans." SG_ 1378 FRfShVlvSts 0;
BA_ "GenSigSendType" SG_ 1378 FRfShVlvSts 3;
BA_ "Event trans." SG_ 1378 HVBat_CoolantLvlLo 0;
BA_ "GenSigStartValue" SG_ 1378 HVBat_CoolantLvlLo 3;
BA_ "GenSigSendType" SG_ 1378 HVBat_CoolantLvlLo 3;
BA_ "Event trans." SG_ 1378 HVBatCritCondT 0;
BA_ "GenSigSendType" SG_ 1378 HVBatCritCondT 3;
BA_ "GenSigStartValue" SG_ 1425 HVBatSOH 250;
BA_ "GenSigStartValue" SG_ 1425 HVBatSOHLow 250;
BA_ "GenSigStartValue" SG_ 654 HCPCoachDisp 64;
BA_ "GenSigStartValue" SG_ 654 HCPOutputPwr 64;
BA_ "Event trans." SG_ 1465 Batt_CabinPriority1_Sts 0;
BA_ "GenSigSendType" SG_ 1465 Batt_CabinPriority1_Sts 3;
BA_ "Event trans." SG_ 1465 ChargeUntilFull1_Sts 0;
BA_ "GenSigSendType" SG_ 1465 ChargeUntilFull1_Sts 3;
BA_ "Event trans." SG_ 1465 Do_Not_Repeat1_Sts 0;
BA_ "GenSigSendType" SG_ 1465 Do_Not_Repeat1_Sts 3;
BA_ "Event trans." SG_ 1465 End_Time_Hr1_Sts 0;
BA_ "GenSigSendType" SG_ 1465 End_Time_Hr1_Sts 3;
BA_ "Event trans." SG_ 1465 End_Time_Min1_Sts 0;
BA_ "GenSigSendType" SG_ 1465 End_Time_Min1_Sts 3;
BA_ "Event trans." SG_ 1465 Schedule_Confirmed1 0;
BA_ "GenSigSendType" SG_ 1465 Schedule_Confirmed1 3;
BA_ "Event trans." SG_ 1465 Schedule_Day1_Sts 0;
BA_ "GenSigSendType" SG_ 1465 Schedule_Day1_Sts 3;
BA_ "Event trans." SG_ 1465 Schedule_Type1_Sts 0;
BA_ "GenSigSendType" SG_ 1465 Schedule_Type1_Sts 3;
BA_ "Event trans." SG_ 1465 Start_Time_Hr1_Sts 0;
BA_ "GenSigSendType" SG_ 1465 Start_Time_Hr1_Sts 3;
BA_ "Event trans." SG_ 1465 Start_Time_Min1_Sts 0;
BA_ "GenSigSendType" SG_ 1465 Start_Time_Min1_Sts 3;
VAL_ 599 AirBagFailSts 0 "Fail_Not_Present_Lamp_Off" 1 "Fail_Not_Present_Lamp_Flashing" 2 "Fail_Present_Lamp_On" 3 "Not_Used";
VAL_ 599 PsngrBagChargeSts 0 "Active" 1 "Not_Active" 2 "Not_Present" 3 "SNA";
VAL_ 599 SBR1RowCentralSeatBuckleFailSts 0 "Fail_Not_Present" 1 "Fail_Present" 3 "SNA";
VAL_ 599 SBR1RowCentralSeatConfigSts 0 "Seat_Not_Checked" 1 "Seat_Checked";
VAL_ 599 SBR1RowCentralSeatPPDFailSts 0 "Fail_Not_Present" 1 "Fail_Present" 3 "SNA";
VAL_ 599 SBR1RowCentralSeatSts 0 "Seat_Belt_Fasten" 1 "Seat_Belt_Not_Fasten" 2 "Seat_Safe" 3 "Seat_Not_Safe" 7 "SNA";
VAL_ 599 SBR1RowDriverSeatConfigSts 0 "Seat_Not_Checked" 1 "Seat_Checked";
VAL_ 599 SBR1RowDriverSeatFailSts 0 "Fail_Not_Present" 1 "Fail_Present" 3 "SNA";
VAL_ 599 SBR1RowDriverSeatSts 0 "Seat_Belt_Fasten" 1 "Seat_Belt_Not_Fasten" 3 "SNA";
VAL_ 599 SBR1RowPsngrSeatBuckleFailSts 0 "Fail_Not_Present" 1 "Fail_Present" 3 "SNA";
VAL_ 599 SBR1RowPsngrSeatConfigSts 0 "Seat_Not_Checked" 1 "Seat_Checked";
VAL_ 599 SBR1RowPsngrSeatPPDFailSts 0 "Fail_Not_Present" 1 "Fail_Present" 3 "SNA";
VAL_ 599 SBR1RowPsngrSeatSts 0 "Seat_Belt_Fasten" 1 "Seat_Belt_Not_Fasten" 2 "Seat_Safe" 3 "Seat_Not_Safe" 7 "SNA";
VAL_ 599 SBR2RowCentralSeatConfigSts 0 "Seat_Not_Checked" 1 "Seat_Checked";
VAL_ 599 SBR2RowCentralSeatSts 0 "Seat_Belt_Fasten" 1 "Seat_Belt_Not_Fasten" 3 "SNA";
VAL_ 599 SBR2RowLeftSeatConfigSts 0 "Seat_Not_Checked" 1 "Seat_Checked";
VAL_ 599 SBR2RowLeftSeatSts 0 "Seat_Belt_Fasten" 1 "Seat_Belt_Not_Fasten" 3 "SNA";
VAL_ 599 SBR2RowRightSeatConfigSts 0 "Seat_Not_Checked" 1 "Seat_Checked";
VAL_ 599 SBR2RowRightSeatSts 0 "Seat_Belt_Fasten" 1 "Seat_Belt_Not_Fasten" 3 "SNA";
VAL_ 1447 DrvSbltUnFltr 0 "Seat belt fastened/Buckled" 1 "Seatbelt not fastened/Unbuckled" 2 "Seatbelt shorted low/LOW " 3 "Seatbelt shorted high/HIGH " 7 "Signal not available/SNA";
VAL_ 250 CmdIgn_FailSts 0 "Fail_Not_Present" 1 "Fail_Present" 3 "SNA";
VAL_ 250 CmdIgnSts 0 "Initialization" 1 "IGN_LK" 2 "ACC" 3 "RUN" 4 "START" 7 "SNA";
VAL_ 250 EngineOffRequest 0 "Not_Active" 1 "Active";
VAL_ 250 KeyInIgnSts 0 "KEY_DEF" 1 "KEY_NOT_IN_IGN" 2 "KEY_IN_IGN" 3 "SNA";
VAL_ 250 TurnIndicatorSts 0 "Center" 1 "Right" 2 "Left" 3 "SNA";
VAL_ 1444 AirHtwPwrTgt 255 "SNA";
VAL_ 1444 PreCondCabinSts 0 "Off" 1 "On" 2 "SPR" 3 "SNA";
VAL_ 1200 ChargeNow 0 "No_Charge" 1 "Charge_Now";
VAL_ 1200 ChargeNow_TBM 0 "No_Charge" 1 "Charge_Now";
VAL_ 1472 CustKeyInIgnSts 0 "CUST_KEY_DEFAULT" 1 "CUST_KEY_NOT_IN_IGNITION" 2 "CUST_KEY_IN_IGNITION" 3 "SNA";
VAL_ 1472 Force_Park 0 "Not_Active" 1 "Active";
VAL_ 1472 IgnPosSts 0 "Initialization" 1 "IGN_LK" 3 "ACC" 4 "RUN" 5 "START" 7 "SNA";
VAL_ 1472 MemRq_FobNum 0 "FOB_DEFAULT" 1 "FOB_1" 2 "FOB_2" 3 "FOB_3" 4 "FOB_4" 5 "FOB_5" 6 "FOB_6" 7 "FOB_7" 8 "FOB_8" 15 "SNA";
VAL_ 1472 RFFuncReq 0 "NO_BASIC_REQUEST" 1 "LOCK_REQUEST" 2 "RELOCK_REQUEST" 3 "DRIVER_UNLOCK_REQUEST" 4 "ALL_UNLOCK_REQUEST" 5 "TRUNK_PLG_TOGGLE_REQUEST" 6 "LEFT_SLIDER_TOGGLE_REQUEST" 7 "RIGHT_SLIDER_TOGGLE_REQUEST" 8 "FLIPPER_GLASS_REQUEST" 9 "REMOTE_START_ON" 10 "REMOTE_START_OFF" 11 "GLOBAL_WINDOW_DOWN_REQUEST" 12 "OPEN_CONVERTIBLE_TOP" 13 "CLOSE_CONVERTIBLE_TOP" 14 "PANIC_TOGGLE_REQUEST" 15 "DEAD_LOCK_REQUEST" 16 "GLOBAL_WINDOWS_UP_REQUEST" 17 "HEADLIGHTS_OFF_DELAY" 18 "TRUNK_PLG_STOP_REQUEST" 19 "ABORT_CRANKING_ON_REQUEST" 20 "ABORT_CRANKING_OFF_REQUEST" 21 "PRE_COND_ON" 22 "PRE_COND_OFF" 23 "CAR_FINDER_REQUEST" 24 "AUTHENTICATION_REQUEST" 25 "LIGHTS_ON_REQUEST" 26 "LIGHTS_OFF_REQUEST" 27 "LOCK_AND_LIGHTS_OFF_REQUEST" 28 "WARNING_FOB_INSIDE" 29 "WARN_FOB_INSIDE_LIGHTS_OFF_REQ" 31 "SNA";
VAL_ 1472 RFReq 0 "REQUESTOR_DEFAULT" 1 "REQUESTOR_RKE" 2 "REQUESTOR_PE" 3 "REQUESTOR_REMOTESTART" 4 "REQUESTOR_UCONNECT" 5 "REQUESTOR_PE_HANDSFREE" 6 "REQUESTOR_PRECOND" 7 "SNA";
VAL_ 748 AVASFailSts 0 "Fail_Not_Present" 1 "QVPM_Fail" 2 "Front_Speaker_Fail" 3 "Rear_Speaker_Fail" 4 "Plausibility_Fail" 5 "MissingMsg_Fail";
VAL_ 748 FrontWiperMoveSts 0 "Stop" 1 "Moving";
VAL_ 1470 LockUnlockVehicleSts 0 "All_Door_Unlocked" 1 "Driver_Door_Unlocked" 2 "Locked" 3 "Passenger_Door_Unlocked" 4 "Driver_And_Passenger_Doors_Unlocked" 5 "Rear_Door_Unlocked" 6 "Front_Door_Unlocked";
VAL_ 900 DriveStyleSts 0 "Normal" 1 "City" 2 "Sport_Fun" 3 "Winter_Race" 4 "Eco" 5 "TracPlus" 6 "Trekking" 7 "Auto" 8 "Snow" 9 "Sand" 10 "Mud" 11 "Rock" 12 "Race" 13 "Sand_Mud" 31 "SNA";
VAL_ 900 DsuRequest 0 "Normal" 1 "Sport_Winter";
VAL_ 900 EVAP_TEMP_P1C 2047 "SNA";
VAL_ 900 ExternalTemperature 511 "SNA";
VAL_ 900 ExternalTemperatureFailSts 0 "Fail_not_present" 1 "Fail_present";
VAL_ 900 Int_Relay_FailSts 0 "Fail_Not_Present" 1 "Fail_Present" 3 "SNA";
VAL_ 900 LDWRequestSts 0 "NOT Pressed" 1 "Pressed";
VAL_ 900 LowBeamSts 0 "OFF" 1 "ON";
VAL_ 900 ParkBrakeSts 0 "OFF" 1 "ON";
VAL_ 900 PowerModeSts 0 "Standard_Power" 1 "Logistic_Mode_ON" 2 "Logistic_Mode_PR" 3 "LogisticModeON_and_EngineON";
VAL_ 900 Selection_SystemFailSts 0 "Fail_Not_Present" 1 "Fail_Present";
VAL_ 900 SportAvailable 0 "False" 1 "True";
VAL_ 1349 BatteryChargeSts 15 "SNA";
VAL_ 1349 FpsNotAvailable 0 "FPS_Available" 1 "FPS_Not_Available";
VAL_ 1349 FrontWiperReq 0 "OFF" 1 "INT" 2 "LOW" 3 "HIGH" 4 "AUTO" 5 "MIST";
VAL_ 1349 InternalLightLevel 0 "Level_1" 1 "Level_2" 2 "Level_3" 3 "Level_4" 4 "Level_5" 5 "Level_6" 6 "Level_7" 7 "Level_8" 8 "Level_9" 9 "Level_10" 10 "Level_11" 11 "Level_12" 12 "Level_13" 13 "Level_14" 14 "Level_15" 15 "Level_16";
VAL_ 1349 InternalLightSts 0 "Not_Active" 1 "Active";
VAL_ 1349 NoShutOff 0 "MSG_DEFAULT" 1 "MSG_ACTIVE" 3 "SNA";
VAL_ 1201 BonnetFailSts 0 "Fail_Not_Present" 1 "Fail_Present";
VAL_ 1201 BonnetSts 0 "Closed" 1 "Open";
VAL_ 1201 BrakeFluidLevelSts 0 "OK" 1 "Low_Level";
VAL_ 1201 CompressorACReqSts 0 "Not_Active" 1 "Active";
VAL_ 1201 DriverDoorFailSts 0 "Fail_Not_Present" 1 "Fail_Present";
VAL_ 1201 DriverDoorSts 0 "Closed" 1 "Open";
VAL_ 1201 ExteriorRearReleaseSwitchSts 0 "Not_Pressed" 1 "Pressed";
VAL_ 1201 FHeatedWindowLoadSts 0 "OFF" 1 "ON";
VAL_ 1201 LHRDoorSts 0 "Closed" 1 "Open";
VAL_ 1201 PreCond_InhibitSts 0 "INHIBIT_DEFAULT" 1 "TIME_OUT_RUN" 2 "TIME_OUT_CUST_MODE" 3 "DRV_DOOR_AJAR" 4 "PASS_DOOR_AJAR" 5 "LR_DOOR_AJAR" 6 "RR_DOOR_AJAR" 7 "HOOD_AJAR" 8 "TRUNK_LIFTGATE" 9 "START_COUNTER" 10 "FAIL_COUNTER" 11 "VTA_ALARM" 12 "PANIC_MODE" 13 "POWER_LOSS" 14 "PC_OFF_RQ" 15 "PC_DISABLED_PREV" 16 "IGN_SNA" 17 "LOGISTIC_MODE" 31 "SNA";
VAL_ 1201 PreCondActvSts 0 "Precondition_Not_Active" 1 "Precondition_Active";
VAL_ 1201 PsngrDoorSts 0 "Closed" 1 "Open";
VAL_ 1201 RemSt_InhibitSts 0 "INHIBIT_DEFAUILT" 1 "TIME_OUT_RUN" 2 "TIME_OUT_CUST_MODE" 3 "KEY_IN_RUN" 4 "DRV_DOOR_AJAR" 5 "PASS_DOOR_AJAR" 6 "LR_DOOR_AJAR" 7 "RR_DOOR_AJAR" 8 "START_COUNTER" 9 "FAIL_COUNTER" 10 "LOW_RPM_SHUTDOWN" 11 "KEY_IN_IGN" 12 "BRAKE_PRESSED" 13 "HAZARD_LAMP_ON" 14 "NOT_IN_PARK" 15 "VEH_SPEED_HIGH" 16 "HOOD_AJAR" 17 "TRUNK_LIFTGATE" 18 "VTA_ALARM" 19 "PANIC_MODE" 20 "BATT_VOLT_HIGH" 21 "BATT_VOLT_LOW" 22 "POWER_LOSS" 23 "MIL_ON" 24 "OIL_PRESSURE_LOW" 25 "COOLANT_TEMP_HIGH" 26 "RPM_HIGH" 27 "CRANK_NO_START" 28 "REMOTE_OFF_RQ" 29 "RS_DISABLED_PREV" 30 "NOT_CONFIGURED" 31 "NO_HOOD_SWITCH" 32 "NO_AUTO_TRANS" 33 "NOT_ENABLED" 34 "INVALID_SKIM_KEY" 35 "IGN_SNA" 36 "IGN_NOT_LOCK" 37 "GLOW_PLUG_TIMEOUT" 38 "LOW_FUEL" 39 "ETC_LAMP_ON" 40 "LOGISTIC_MODE" 41 "COLD_START_LAMP_FLASH" 44 "FAIL_HCSS " 62 "EPB_NO_RESP" 63 "SNA";
VAL_ 1201 RemStActvSts 0 "Remote Start Not Active" 1 "Remote Start Active";
VAL_ 1201 RHatchSts 0 "Closed" 1 "Open";
VAL_ 1201 RHeatedWindowLoadSts 0 "OFF" 1 "ON";
VAL_ 1201 RHRDoorSts 0 "Closed" 1 "Open";
VAL_ 1201 TheftAlarmStatus 0 "VTA_DISARM" 1 "VTA_PREARM" 2 "VTA_ARM" 3 "VTA_LGT" 4 "VTA_LGT_HORN" 5 "VTA_TAMP" 6 "VTA_ITM_Alarm" 7 "SNA";
VAL_ 1049 BonnetAjarRawValSts 0 "Default" 1 "FL_SSA" 2 "FL_SSB" 3 "FL_SSC" 4 "FL_SSD" 5 "FL_SSE" 6 "OPEN_SSA" 7 "OPEN_SSB" 8 "CLOSED_SSA" 9 "CLOSED_SSB" 10 "FH_SSA" 11 "FH_SSB" 12 "FH_SSC" 13 "FH_SSD" 14 "FH_SSE" 15 "SNA";
VAL_ 1049 DriveStyleSts 0 "Normal" 1 "City" 2 "Sport_Fun" 3 "Winter_Race" 4 "Eco" 5 "TracPlus" 6 "Trekking" 7 "Auto" 8 "Snow" 9 "Sand" 10 "Mud" 11 "Rock" 12 "Race" 13 "Sand_Mud" 31 "SNA";
VAL_ 1049 DRV_DR_UNLOCKING 0 "Not_Active" 1 "Active";
VAL_ 257 ABSActive 0 "Not_active" 1 "Active";
VAL_ 257 Brake_MaxRegen_Ready 0 "Not_ready" 1 "Ready";
VAL_ 257 BrakeInterventionSts 0 "No_active_brake_intervention" 1 "Active_brake_intervention";
VAL_ 257 ESCActive 0 "Not_active" 1 "Active";
VAL_ 257 PrefillActive 0 "Not_Active" 1 "Active";
VAL_ 257 VehicleSpeedVSOSig 8191 "SNA";
VAL_ 257 VehicleSpeedVSOSigFailSts 0 "Fail_not_present" 1 "Fail_present";
VAL_ 257 VehicleStandStillSts 0 "True" 1 "False" 3 "SNA";
VAL_ 506 BrkPdl_Stat 0 "UPSTOP" 1 "PSD" 2 "NDEF2" 3 "SNA";
VAL_ 259 BrakeTravelSts 255 "SNA";
VAL_ 259 BSM_Comm_Fail_CANC2 0 "No_Fault" 1 "LoC_CANC2" 3 "BusFailure_CANC2";
VAL_ 259 HillHolderActive 0 "Not_Active" 1 "Active";
VAL_ 259 MuSplit 0 "MuSplitOFF" 1 "MuSplitON" 3 "SNA";
VAL_ 259 OverSteering 63 "SNA";
VAL_ 259 UnderSteering 63 "SNA";
VAL_ 501 AEB_InterventionType 0 "None" 1 "ACC" 2 "AEB_P_standard" 3 "AEB_P_extended" 4 "EBA" 5 "AEB_L" 7 "SNA";
VAL_ 501 ExternalBrkRequestsDisabled 0 "Enabled" 1 "Diasbled" 2 "Not_Used" 3 "SNA";
VAL_ 501 VehicleStandStillSts 0 "True" 1 "False" 3 "SNA";
VAL_ 498 ACC_Wheel_Torque_Enabled_BSM 0 "Not Enabled" 1 "Enabled";
VAL_ 498 Brk_Jrk_Resp 0 "Not_Executed" 1 "Executed";
VAL_ 498 Brk_Thermdl 0 "Normal_Temperature" 1 "High_Temperature";
VAL_ 1048 ASRActive 0 "Not_active" 1 "Active";
VAL_ 1048 BrakeFluidLevelSts 0 "Ok" 1 "Low_Level";
VAL_ 1048 HNGActive 0 "Not_Active" 1 "Active";
VAL_ 1048 MSRActive 0 "Not_Active" 1 "Active";
VAL_ 1048 TravelDistance 255 "SNA";
VAL_ 1199 ABSFailSts 0 "Fail_Not_Present" 1 "Fail_Present";
VAL_ 1199 BSM_BLC_Active 0 "Not_Active" 1 "Active";
VAL_ 1199 BSMSysSts 0 "Normal mode" 1 "Diagnosis mode" 2 "Alternative mode" 3 "SNA";
VAL_ 1199 CMMIntervention 0 "No_intervention" 1 "Intervention";
VAL_ 1199 EBDFailSts 0 "Fail_Not_Present" 1 "Fail_Present";
VAL_ 1199 ERMActive 0 "Not_Active" 1 "Active";
VAL_ 1199 ESCFailSts 0 "Fail_Not_Present" 1 "Fail_Present";
VAL_ 1199 ESCIntervention 0 "No_intervention" 1 "Intervention_blinking_lamp";
VAL_ 1199 Function2Sts 0 "Not_Active" 1 "Active";
VAL_ 1199 FunctionFailSts 0 "Fail_Not_Present" 1 "Fail_Present";
VAL_ 1199 FunctionIntervention 0 "No_intervention" 1 "Intervention_blinking_lamp";
VAL_ 1199 FunctionSts 0 "Not_Active" 1 "Active";
VAL_ 1199 HillHolderFailSts 0 "Fail_not_present" 1 "Fail_present";
VAL_ 1199 RollsModeAct 0 "Not_active" 1 "Active";
VAL_ 1199 TPMActivitySts 0 "TPM_Enabled" 1 "TPM_Disabled";
VAL_ 1199 TSCActive 0 "Not_Active" 1 "Active";
VAL_ 1199 TyreInflationState_LHF_Tyre 0 "Normal_Tyre_Pressure" 1 "Under_Inflated_Tyre" 2 "Significantly_Under_Inflated_Tyre" 3 "Over_Inflated_Tyre";
VAL_ 1199 TyreInflationState_LHR_Tyre 0 "Normal_Tyre_Pressure" 1 "Under_Inflated_Tyre" 2 "Significantly_Under_Inflated_Tyre" 3 "Over_Inflated_Tyre";
VAL_ 1199 TyreInflationState_RHF_Tyre 0 "Normal_Tyre_Pressure" 1 "Under_Inflated_Tyre" 2 "Significantly_Under_Inflated_Tyre" 3 "Over_Inflated_Tyre";
VAL_ 1199 TyreInflationState_RHR_Tyre 0 "Normal_Tyre_Pressure" 1 "Under_Inflated_Tyre" 2 "Significantly_Under_Inflated_Tyre" 3 "Over_Inflated_Tyre";
VAL_ 1199 TyrePressureSystemFailSts 0 "Fail_Not_Present" 1 "Fail_Present";
VAL_ 1453 PowerModeSts_BSM 0 "Standard Power" 1 "Logistic Mode ON" 2 "Logistic_Mode_PR" 3 "Not_Used";
VAL_ 254 InternalError_BSM 0 "No_int_processing_error_detected" 1 "Int_processing_error_detected";
VAL_ 254 LatAcceleration_BSM 4095 "SNA";
VAL_ 254 LatAccelerationFailSts_BSM 0 "Fail_Not_Present" 1 "Fail_Present";
VAL_ 254 LongAcceleration_BSM 4095 "SNA";
VAL_ 254 LongAccelerationFailSts_BSM 0 "Fail_Not_Present" 1 "Fail_Present";
VAL_ 254 Slope 255 "SNA";
VAL_ 254 YawRate_BSM 4095 "SNA";
VAL_ 254 YawRateFailSts_BSM 0 "Fail_Not_Present" 1 "Fail_Present";
VAL_ 1440 ACC_RadarBlinded 0 "Fail_Present" 1 "Fail_not_present";
VAL_ 1440 ACC_SetSpeedKPH 255 "SNA";
VAL_ 1440 ACC_SetSpeedMPH 255 "SNA";
VAL_ 1440 ACCFailSts 0 "Fail_not_present" 1 "Fail_Present";
VAL_ 1440 ACCSystemSts 0 "OFF" 1 "Enabled" 2 "Engaged" 3 "Engaged_BrakeOnly" 4 "Override" 5 "Cancel";
VAL_ 1440 AEBFailSts 0 "Fail_Present" 1 "Fail_not_present";
VAL_ 1440 AEBTemporaryFailSts 0 "Fail_Present" 1 "Fail_not_present";
VAL_ 1440 CameraBlinded 0 "Fail_Present" 1 "Fail_not_present";
VAL_ 1440 CameraBlocked 0 "Fail_Present" 1 "Fail_not_present";
VAL_ 1440 FCWSystemSts 0 "Off" 1 "On_Only_Warning" 2 "On_Only_Braking" 3 "On_Full";
VAL_ 1440 HMICode_ACC 0 "No CODE" 1 "ACC_UNAVAILABLE_4WD_LOW" 2 "ACC_UNAVAILABLE_HDC_ACTIVE" 3 "ACC_UNAVAILABLE_ESC_FAULT" 4 "ACC_UNAVAILABLE_ESC_OFF" 5 "ACC_UNAVAILABLE_BRAKES_COOLING" 6 "ACC_UNAVAILABLE_BELOW_MIN_SPEED" 7 "ACC_UNAVAILABLE_ABOVE_MAX_SPEED" 8 "ACC_UNAVAILABLE_EPB_ACTIVE" 9 "ACC_UNAVAILABLE_SHIFT_D" 10 "ACC_UNAVAILABLE_WRONG_GEAR" 11 "ACC_UNAVAILABLE_HIGH_RPM" 12 "ACC_UNAVAILABLE_LOW_RPM" 13 "ACC_CANC_BRAKE_COOLING" 14 "ACC_CANC_BELOW_MIN_SPEED" 15 "ACC_CANC_ABOVE_MAX_SPEED" 16 "ACC_CANC_EPB_ACTIVE" 17 "ACC_CANC_ESC_OFF" 18 "ACC_CANC_ESC_EVENT" 19 "ACC_WARNING_CLUTCH_ENGAGED" 20 "ACC_CANC_LOW_RPM" 21 "ACC_CANC_HIGH_RPM" 22 "ACC_WARNING_NEUTRAL_ENGAGED" 23 "ACC_CANC_WRONG_GEAR" 24 "ACC_CANC_SHIFT_D" 25 "ACC_OFF_ESC_FAULT" 26 "ACC_PROX_WARNING" 27 "ACC_CAMERA_FAIL" 28 "ACC_CAMERA BLINDED" 29 "NCC_UNAVAILABLE_4WD_LOW" 30 "NCC_UNAVAILABLE_HDC_ACTIVE" 31 "NCC_UNAVAILABLE_ESC_FAULT" 32 "NCC_UNAVAILABLE_ESC_OFF" 33 "NCC_UNAVAILABLE_BRAKES_COOLING" 34 "NCC_UNAVAILABLE_BELOW_MIN_SPEED" 35 "NCC_UNAVAILABLE_ABOVE_MAX_SPEED" 36 "NCC_UNAVAILABLE_EPB_ACTIVE" 37 "NCC_UNAVAILABLE_SHIFT_D" 38 "NCC_UNAVAILABLE_WRONG_GEAR" 39 "NCC_UNAVAILABLE_HIGH_RPM" 40 "NCC_UNAVAILABLE_LOW_RPM" 41 "NCC_CANC_BRAKE_COOLING" 42 "NCC_CANC_BELOW_MIN_SPEED" 43 "NCC_CANC_ABOVE_MAX_SPEED" 44 "NCC_CANC_EPB_ACTIVE" 45 "NCC_CANC_ESC_OFF" 46 "NCC_CANC_ESC_EVENT" 47 "NCC_WARNING_CLUTCH_ENGAGED" 48 "NCC_CANC_LOW_RPM" 49 "NCC_CANC_HIGH_RPM" 50 "NCC_WARNING_NEUTRAL_ENGAGED" 51 "NCC_CANC_WRONG_GEAR" 52 "NCC_CANC_SHIFT_D" 53 "ACC_USER_DISABLED" 54 "ACC_USER_ENABLED_D1" 55 "ACC_USER_ENABLED_D2" 56 "ACC_USER_ENABLED_D3" 57 "ACC_USER_ENABLED_D4" 58 "ACC_SET_D1_TARGET" 59 "ACC_SET_D2_TARGET" 60 "ACC_SET_D3_TARGET" 61 "ACC_SET_D4_TARGET" 62 "ACC_SET_D1_NO_TARGET" 63 "ACC_SET_D2_NO_TARGET" 64 "ACC_SET_D3_NO_TARGET" 65 "ACC_SET_D4_NO_TARGET" 66 "ACC_CANCEL_D1" 67 "ACC_CANCEL_D2" 68 "ACC_CANCEL_D3" 69 "ACC_CANCEL_D4" 70 "ACC_CANCEL" 71 "ACC_ENABLED" 72 "ACC_SET" 73 "ACC_RESUME" 74 "ACC_OVERRIDE" 75 "ACC_OVERRIDE_D1" 76 "ACC_OVERRIDE_D2" 77 "ACC_OVERRIDE_D3" 78 "ACC_OVERRIDE_D4" 79 "NCC_CANCEL" 80 "NCC_USER_ENABLED" 81 "NCC_SET" 82 "NCC_RESUME" 83 "NCC_USER_DISABLED" 84 "NCC_OVERRIDE" 85 "ACC_UNAVAILABLE" 86 "NCC_UNAVAILABLE" 87 "ACC_CANCEL_CHIME" 88 "NCC_CANCEL_CHIME" 89 "ACC_UNAVAILABLE_ESC_EVENT" 90 "NCC_UNAVAILABLE_ESC_EVENT" 91 "ACC_UNAVAILABLE_CLUTCH_ENGAGED" 92 "NCC_UNAVAILABLE_CLUTCH_ENGAGED" 93 "ACC_FRONT_RADAR_SENSOR_PLANT_MODE" 94 "ACC_CANC_DOOR_OPEN" 95 "ACC_CANC_SEATBELT_UNBUCKLED" 96 "ACC_UNAVAILABLE_DOOR_OPEN" 97 "ACC_UNAVAILABLE_SEATBELT_UNBUCKLED" 98 "ACC_STOP_VEHICLE_OBJECT_DETECTED" 99 "ACC_CANC_ROAD_TOO_STEEP" 100 "ACC_UNAVAILABLE_ROAD_TOO_STEEP" 101 "ACC_NCC_USER_DISABLED" 102 "FCW_ACC_RADAR_BLINDED" 103 "ACC_RADAR_BLINDED" 104 "ACC_PERM_FAIL" 105 "ACC_FCW_PERM_FAIL" 106 "NCC_FCW_PERM_FAIL" 107 "NCC_PERM_FAIL" 108 "FCW_PERM_FAIL" 109 "ACC_SET_D1_TARGET_RESUME_REQ" 110 "ACC_SET_D2_TARGET_RESUME_REQ" 111 "ACC_SET_D3_TARGET_RESUME_REQ" 112 "ACC_SET_D4_TARGET_RESUME_REQ" 113 "iACC_NOT_AVAIL_SPEED_TOO_HIGH" 114 "iACC_NOT_AVAIL_SPEED_TOO_LOW" 115 "ACC_PROX_WARNING_LEFT" 116 "ACC_PROX_WARNING_CENTER" 117 "ACC_PROX_WARNING_RIGHT" 118 "iACC_NOT_AVAILABLE_TSR_NOT_AVAILABLE";
VAL_ 1440 HMICode_FCW 0 "Idle" 1 "Pre_Intervention_warning" 2 "Intervention__warning" 3 "Not_Available_warning_type1" 4 "Not_Available_warning_4WD_Low" 5 "ACTIVE_BRAKING_ENBL" 6 "ACTIVE_BRAKING_DSBL" 7 "FCW_USER_DISABLED" 8 "FCW_RADAR_BLINDED" 9 "FCW_CAMERA_BLINDED" 10 "FCW_CAMERA_FAIL" 11 "FCW_PERM_FAIL" 12 "Pre_Intervention_warning_Left" 13 "Pre_Intervention_warning_Right" 14 "Pre_Intervention_warning_Center" 15 "AEB_Off_Init" 16 "Not_Available_warning_type2" 17 "Cancelled_warning_type1" 18 "Cancelled_warning_type2";
VAL_ 1440 HMIDisplay_ACC 0 "No_Code" 1 "ACC_USER_DISABLED" 2 "ACC_USER_ENABLED_D1" 3 "ACC_USER_ENABLED_D2" 4 "ACC_USER_ENABLED_D3" 5 "ACC_USER_ENABLED_D4" 6 "ACC_SET_D1_TARGET" 7 "ACC_SET_D2_TARGET" 8 "ACC_SET_D3_TARGET" 9 "ACC_SET_D4_TARGET" 10 "ACC_SET_D1_NO_TARGET" 11 "ACC_SET_D2_NO_TARGET" 12 "ACC_SET_D3_NO_TARGET" 13 "ACC_SET_D4_NO_TARGET" 14 "ACC_CANCEL_D1" 15 "ACC_CANCEL_D2" 16 "ACC_CANCEL_D3" 17 "ACC_CANCEL_D4" 18 "ACC_CANCEL" 19 "ACC_ENABLED" 20 "ACC_SET" 21 "ACC_RESUME" 22 "ACC_OVERRIDE" 23 "ACC_OVERRIDE_D1" 24 "ACC_OVERRIDE_D2" 25 "ACC_OVERRIDE_D3" 26 "ACC_OVERRIDE_D4" 27 "NCC_CANCEL" 28 "NCC_USER_ENABLED" 29 "NCC_SET" 30 "NCC_RESUME" 31 "NCC_USER_DISABLED" 32 "NCC_OVERRIDE" 33 "ACC_SET_D1_TARGET_RESUME_REQ" 34 "ACC_SET_D2_TARGET_RESUME_REQ" 35 "ACC_SET_D3_TARGET_RESUME_REQ" 36 "ACC_SET_D4_TARGET_RESUME_REQ" 37 "ACC_OVERRIDE_D1_TARGET" 38 "ACC_OVERRIDE_D2_TARGET" 39 "ACC_OVERRIDE_D3_TARGET" 40 "ACC_OVERRIDE_D4_TARGET";
VAL_ 1440 iACCSts 0 "Not_Active" 1 "Active";
VAL_ 601 ElectricSteeringLamp_FailSts 0 "OFF_Fail_not_present" 1 "OFF_Fail_present" 2 "ON_Fail_not_present" 3 "Not_used";
VAL_ 601 PowerLimit_Requested 0 "No_Change" 1 "Level1" 2 "Level2" 3 "Level3" 4 "Level4" 5 "Level5" 7 "SNA";
VAL_ 601 SpeedUnit 0 "km/h" 1 "mph";
VAL_ 598 ABSLamp_FailSts 0 "OFF_Fail_not_present" 1 "OFF_Fail_present" 2 "ON_Fail_not_present" 3 "Not_used";
VAL_ 598 AirBagLamp_FailSts 0 "OFF_Fail_not_present" 1 "OFF_Fail_present" 2 "ON_Fail_not_present" 3 "BLINKING_Fail_not_present";
VAL_ 598 DistanceUnit 0 "km" 1 "miles";
VAL_ 598 EBDLamp_FailSts 0 "OFF_Fail_not_present" 1 "OFF_Fail_present" 2 "ON_Fail_not_present" 3 "Not_used";
VAL_ 598 EPBAutoAppReqSts 0 "Not_Request" 1 "AutoApply_Disable" 2 "AutoApply_Enable" 3 "Not_used";
VAL_ 598 EPBLamp_FailSts 0 "OFF_Fail_not_present" 1 "OFF_Fail_present" 2 "ON_Fail_not_present" 3 "Not_used";
VAL_ 598 EPBMaintenanceReqSts 0 "Not_Request" 1 "Maintenance_Disable" 2 "Maintenance_Enable" 3 "Not_used";
VAL_ 598 ESCLamp_FailSts 0 "OFF_Fail_not_present" 1 "OFF_Fail_present" 2 "ON_Fail_not_present" 3 "Not_used";
VAL_ 598 FSFCWPlusActivationMode 0 "Near" 1 "Med" 2 "Far";
VAL_ 598 FSFCWPlusSetting 0 "Off" 1 "Audio" 2 "Brake" 3 "Audio_Brake" 4 "No_Request";
VAL_ 598 PassiveEntry 0 "On" 1 "Off";
VAL_ 598 PowerModeSts_IPC 0 "Standard_Power" 1 "Logistic_Mode_ON" 2 "Logistic_Mode_PR" 3 "Not_Used";
VAL_ 598 PsngrBagRequestSts 0 "Not_Request" 1 "Enable" 2 "Disable" 3 "Not_Used";
VAL_ 598 RemoteDoorUnlock 0 "Driver" 1 "All";
VAL_ 598 TPICalibrationReqSts 0 "Not_Active" 1 "Active";
VAL_ 224 AutoHold 0 "Off" 1 "On";
VAL_ 224 DisplayedSpeedSign 0 "Sign_Not_Detected" 1 "Speed_Limit_1" 2 "Speed_Limit_2" 3 "Speed_Limit_3" 4 "Speed_Limit_4" 5 "Speed_Limit_5" 6 "Speed_Limit_6" 7 "Speed_Limit_7" 8 "Speed_Limit_8" 9 "Speed_Limit_9" 10 "Speed_Limit_10" 11 "Speed_Limit_11" 12 "Speed_Limit_12" 13 "Speed_Limit_13" 14 "Speed_Limit_14" 15 "Speed_Limit_15" 16 "Speed_Limit_16" 17 "Speed_Limit_17" 18 "Speed_Limit_18" 19 "Speed_Limit_19" 20 "Speed_Limit_20" 21 "Speed_Limit_21" 22 "Speed_Limit_22" 23 "Speed_Limit_23" 24 "Speed_Limit_24" 25 "Speed_Limit_25" 26 "Speed_Limit_26" 27 "Speed_Limit_27" 28 "Speed_Limit_28" 29 "Speed_Limit_29" 30 "Speed_Limit_30" 31 "Speed_Limit_31" 32 "Speed_Limit_32" 33 "Speed_Limit_33" 34 "Speed_Limit_34" 35 "Speed_Limit_35" 36 "Speed_Limit_36" 37 "Speed_Limit_37" 38 "Speed_Limit_38" 39 "Speed_Limit_39" 40 "Speed_Limit_40" 41 "Speed_Limit_41" 42 "Speed_Limit_42" 43 "Speed_Limit_43" 44 "Speed_Limit_44" 45 "Speed_Limit_45" 46 "Speed_Limit_46" 47 "Speed_Limit_47" 48 "Speed_Limit_48" 49 "Speed_Limit_49" 50 "Speed_Limit_50" 51 "Speed_Limit_51" 52 "Speed_Limit_52" 53 "Speed_Limit_53" 54 "Speed_Limit_54" 55 "Speed_Limit_55" 56 "Speed_Limit_56" 57 "Speed_Limit_57" 58 "Speed_Limit_58" 59 "Speed_Limit_59" 60 "Speed_Limit_60" 61 "Speed_Limit_61" 62 "Speed_Limit_62" 63 "Speed_Limit_63" 64 "Speed_Limit_64" 65 "Speed_Limit_65" 66 "Speed_Limit_66" 67 "Speed_Limit_67" 68 "Speed_Limit_68" 69 "Speed_Limit_69" 70 "Speed_Limit_70" 71 "Speed_Limit_71" 72 "Speed_Limit_72" 73 "Speed_Limit_73" 74 "Speed_Limit_74" 75 "Speed_Limit_75" 76 "Speed_Limit_76" 77 "Speed_Limit_77" 78 "Speed_Limit_78" 79 "Speed_Limit_79" 80 "Speed_Limit_80" 81 "Speed_Limit_81" 82 "Speed_Limit_82" 83 "Speed_Limit_83" 84 "Speed_Limit_84" 85 "Speed_Limit_85" 86 "Speed_Limit_86" 87 "Speed_Limit_87" 88 "Speed_Limit_88" 89 "Speed_Limit_89" 90 "Speed_Limit_90" 91 "Speed_Limit_91" 92 "Speed_Limit_92" 93 "Speed_Limit_93" 94 "Speed_Limit_94" 95 "Speed_Limit_95" 96 "Speed_Limit_96" 97 "Speed_Limit_97" 98 "Speed_Limit_98" 99 "Speed_Limit_99" 100 "Speed_Limit_100" 101 "Speed_Limit_101" 102 "Speed_Limit_102" 103 "Speed_Limit_103" 104 "Speed_Limit_104" 105 "Speed_Limit_105" 106 "Speed_Limit_106" 107 "Speed_Limit_107" 108 "Speed_Limit_108" 109 "Speed_Limit_109" 110 "Speed_Limit_110" 111 "Speed_Limit_111" 112 "Speed_Limit_112" 113 "Speed_Limit_113" 114 "Speed_Limit_114" 115 "Speed_Limit_115" 116 "Speed_Limit_116" 117 "Speed_Limit_117" 118 "Speed_Limit_118" 119 "Speed_Limit_119" 120 "Speed_Limit_120" 121 "Speed_Limit_121" 122 "Speed_Limit_122" 123 "Speed_Limit_123" 124 "Speed_Limit_124" 125 "Speed_Limit_125" 126 "Speed_Limit_126" 127 "Speed_Limit_127" 128 "Speed_Limit_128" 129 "Speed_Limit_129" 130 "Speed_Limit_130" 131 "Speed_Limit_131" 132 "Speed_Limit_132" 133 "Speed_Limit_133" 134 "Speed_Limit_134" 135 "Speed_Limit_135" 136 "Speed_Limit_136" 137 "Speed_Limit_137" 138 "Speed_Limit_138" 139 "Speed_Limit_139" 140 "Speed_Limit_140" 141 "Speed_Limit_141" 142 "Speed_Limit_142" 143 "Speed_Limit_143" 144 "Speed_Limit_144" 145 "Speed_Limit_145" 146 "Speed_Limit_146" 147 "Speed_Limit_147" 148 "Speed_Limit_148" 149 "Speed_Limit_149" 150 "Speed_Limit_150" 151 "Speed_Limit_151" 152 "Speed_Limit_152" 153 "Speed_Limit_153" 154 "Speed_Limit_154" 155 "Speed_Limit_155" 156 "Speed_Limit_156" 157 "Speed_Limit_157" 158 "Speed_Limit_158" 159 "Speed_Limit_159" 160 "Speed_Limit_160" 161 "Speed_Limit_161" 162 "Speed_Limit_162" 163 "Speed_Limit_163" 164 "Speed_Limit_164" 165 "Speed_Limit_165" 166 "Speed_Limit_166" 167 "Speed_Limit_167" 168 "Speed_Limit_168" 169 "Speed_Limit_169" 170 "Speed_Limit_170" 171 "Speed_Limit_171" 172 "Speed_Limit_172" 173 "Speed_Limit_173" 174 "Speed_Limit_174" 175 "Speed_Limit_175" 176 "Speed_Limit_176" 177 "Speed_Limit_177" 178 "Speed_Limit_178" 179 "Speed_Limit_179" 180 "Speed_Limit_180" 181 "Speed_Limit_181" 182 "Speed_Limit_182" 183 "Speed_Limit_183" 184 "Speed_Limit_184" 185 "Speed_Limit_185" 186 "Speed_Limit_186" 187 "Speed_Limit_187" 188 "Speed_Limit_188" 189 "Speed_Limit_189" 190 "Speed_Limit_190" 191 "Speed_Limit_191" 192 "Speed_Limit_192" 193 "Speed_Limit_193" 194 "Speed_Limit_194" 195 "Speed_Limit_195" 196 "Speed_Limit_196" 197 "Speed_Limit_197" 198 "Speed_Limit_198" 199 "Speed_Limit_199" 200 "Speed_Limit_200" 201 "Speed_Limit_201" 202 "Speed_Limit_202" 203 "Speed_Limit_203" 204 "Speed_Limit_204" 205 "Speed_Limit_205" 206 "Speed_Limit_206" 207 "Speed_Limit_207" 208 "Speed_Limit_208" 209 "Speed_Limit_209" 210 "Speed_Limit_210" 211 "Speed_Limit_211" 212 "Speed_Limit_212" 213 "Speed_Limit_213" 214 "Speed_Limit_214" 215 "Speed_Limit_215" 216 "Speed_Limit_216" 217 "Speed_Limit_217" 218 "Speed_Limit_218" 219 "Speed_Limit_219" 220 "Speed_Limit_220" 221 "Speed_Limit_221" 222 "Speed_Limit_222" 223 "Speed_Limit_223" 224 "Speed_Limit_224" 225 "Speed_Limit_225" 226 "Speed_Limit_226" 227 "Speed_Limit_227" 228 "Speed_Limit_228" 229 "Speed_Limit_229" 230 "Speed_Limit_230" 231 "Speed_Limit_231" 232 "Speed_Limit_232" 233 "Speed_Limit_233" 254 "Speed_Limit_Unlimited" 255 "End_Speed_Limit";
VAL_ 224 NewSpdZoneInd 0 "Off" 1 "Chime" 2 "Visual" 3 "Visual_Chime";
VAL_ 224 SignCaptureMode 0 "Confirmation" 1 "Automatic";
VAL_ 252 GasPedalPosition 255 "SNA";
VAL_ 252 GasPedalPositionFailSts 0 "Fail_not_present" 1 "Fail_present";
VAL_ 252 PowertrainPrplsnActv 0 "Off" 1 "Active";
VAL_ 252 ReverseGearSts 0 "Not_Inserted" 1 "Inserted" 2 "Not_Used" 3 "SNA";
VAL_ 1445 CC_SetSpdDspl_KPH 8191 "SNA";
VAL_ 1445 CC_SetSpdDspl_MPH 255 "SNA";
VAL_ 1445 CruiseControlLampSts 0 "Not_inserted" 1 "Inserted";
VAL_ 1445 CruiseControlSts 0 "Not_inserted" 1 "Inserted";
VAL_ 1445 ISASts 0 "Not_Active" 1 "Active";
VAL_ 1445 Override 0 "Not_active" 1 "Active";
VAL_ 1445 SpeedLimitSts 0 "Standby" 1 "Activated" 2 "Not_Actuable" 3 "Override" 4 "Overspeed" 5 "Deactivated" 6 "Off" 7 "SNA";
VAL_ 496 ActualPedalPos 255 "SNA";
VAL_ 550 ECM_WARN 0 "NONE" 1 "CC_NOT_AVAIL_PLACE_SHIFTER_IN_D" 2 "CC_NOT_AVAIL_PARKBRAKE_ENGAGED" 3 "CC_NOT_AVAIL_STABIL_EVENT_OCCUR" 4 "CC_NOT_AVAIL_LOW_RANGE_4WD" 5 "CC_NOT_AVAIL_VEHICLE_SYSTEM_ERR" 6 "SL_NOT_AVAIL_HDC_SET" 7 "CC_CANC_PLACE_SHIFTER_IN_DRIVE" 8 "CC_CANC_PARKBRAKE_ENGAGED" 9 "CC_CANC_STABILITY_EVENT_OCCUR" 10 "SL_NOT_AVAILABLE_SSC_SET" 11 "CC_CANC_VEHICLE_SYSTEM_ERROR" 12 "CC_OFF_ASL_ACTIVE" 13 "ASL OFF CRUISE ACTIVE" 14 "CC_NOT_AVAIL_BELOW_MIN_RES_SPD" 15 "CC_CANCELLED_ESC_OFF" 16 "CC_UNAVAILABLE_ESC_OFF" 17 "CC_CANCELLED_BY_DRIVER" 18 "CC_OFF" 19 "CC_CANCELLED_RPM_DROPS_TOO_LOW" 20 "CC_NOT_AVAIL_RPM_DROPS_TOO_LOW" 21 "CC_CANCELLED_RPM_TOO_HIGH" 22 "CC_NOT_AVAILABLE_RPM_TOO_HIGH" 23 "DRIVER_CRUISE_OVERRIDE" 24 "CC_NOT_AVAILABLE_HDC_SET" 25 "ISA_NOT_AVAIL_TSR_NOT_AVAIL" 26 "ISA_NOT_AVAIL_SPEED_TOO_HIGH" 27 "ISA_NOT_AVAIL_SPEED_TOO_ LOW" 28 "CC_NOT_AVAIL_ABOVE_MAX_SPD";
VAL_ 1854 HighBeamSts 0 "OFF" 1 "ON";
VAL_ 1854 LHParkingLightSts 0 "OFF" 1 "ON";
VAL_ 1854 LHTurnLightFault 0 "False" 1 "True";
VAL_ 1854 LHTurnSignalSts 0 "OFF" 1 "ON";
VAL_ 1854 ParkingLightFault 0 "False" 1 "True";
VAL_ 1854 RHParkingLightSts 0 "OFF" 1 "ON";
VAL_ 1854 RHTurnLightFault 0 "False" 1 "True";
VAL_ 1854 RHTurnSignalSts 0 "OFF" 1 "ON";
VAL_ 1854 StopLightFault 0 "False" 1 "True";
VAL_ 1854 StopLightSts 0 "OFF" 1 "ON";
VAL_ 222 ElectricSteeringFailSts 0 "Fail_Not_Present" 1 "Fail_Present";
VAL_ 222 LwsAngle 65535 "SNA";
VAL_ 222 LwsCalibration 0 "Not_calibrated" 1 "Calibrated";
VAL_ 222 LWSFailSts 0 "Fail_not_Present" 1 "Fail_Present_Ignition_Latched" 2 "Fail_Present_Recoverable" 3 "Fail_Present_Battery_Disconnection";
VAL_ 222 LwsSpeed 4095 "SNA";
VAL_ 1896 GPS_POS3_Date_Day 255 "SNA";
VAL_ 1896 GPS_POS3_Date_Hour 255 "SNA";
VAL_ 1896 GPS_POS3_Date_Minutes 255 "SNA";
VAL_ 1896 GPS_POS3_Date_Month 255 "SNA";
VAL_ 1896 GPS_POS3_Date_Seconds 65535 "SNA";
VAL_ 1896 GPS_POS3_Date_Year 65535 "SNA";
VAL_ 701 AHCP_Comm_Fail_CANC2 0 "No_Fault" 1 "LoC_BSM" 3 "BusFailure_CANC2";
VAL_ 701 BatPwrUsage_V 0 "Valid" 1 "Not_Valid";
VAL_ 701 Drive_Mode_Inhibit 0 "False" 1 "True";
VAL_ 701 Est_Range_Trend 0 "Default" 1 "Dash" 2 "Arrow_Up" 3 "Arrow_Down";
VAL_ 701 HCP_Sch_PreCondition_Sts 0 "False" 1 "True" 3 "SNA";
VAL_ 701 HEV_LMP_RQ 0 "OFF" 1 "ON" 2 "BLINK" 3 "SNA";
VAL_ 701 R134a_PressSts 511 "SNA";
VAL_ 701 TurtleModeSts 0 "No_Turtle_Mode" 1 "Turtle_Level1" 2 "Turtle_Level2" 3 "Turtle_Level3" 4 "Turtle_Level4" 7 "SNA";
VAL_ 701 VehSpd_Overridden 0 "No_Request" 1 "HMI_PopUp_Camel" 2 "HMI_Telltale_Camel" 3 "HMI_PopUp_Turtle" 4 "HMI_Telltale_Turtle";
VAL_ 1377 Cabin_Condition_Sts 0 "Default" 1 "Rejected_not_plugged_in" 2 "Stopped_due_to_SOC" 3 "On" 4 "Cabin_Set_Pt_Reached" 5 "Off" 6 "Failed_Other_Than_HV_Bat_Temp" 7 "Failed_HV_Bat_Temp" 8 "Bat_Cond _complete" 9 "Bat_Cond_Stp_Bfr_Cmpl_HVBat_NOK" 15 "SNA";
VAL_ 1377 ChargingLevel 0 "Default_NoLevel" 1 "Level_1_AC" 2 "Level_2_AC" 3 "Level_3_AC" 4 "Level_1_DC" 5 "Level_2_DC" 6 "PlugInNotDet" 7 "PPI_1_No_Drive" 8 "PPI_2_OK_Drive" 15 "SNA";
VAL_ 1377 ChargingSysSts 0 "NotCharging" 1 "Charging" 2 "ChargeInterrupted" 3 "ChargeComplete" 7 "SNA";
VAL_ 1377 ChrgSysFault 0 "Not_Faulted" 1 "Faulted";
VAL_ 1377 CompStat 0 "NormalOperation" 1 "DegradedOperation" 2 "Inoperative" 3 "Reserved1" 4 "Reserved2" 5 "Reserved3" 6 "Reserved4" 15 "SNA";
VAL_ 1377 DriveReady 0 "Default" 1 "Vehicle is allowed to shift out of park or neutral";
VAL_ 1377 EstTimeofChrg_Lv1 8191 "SNA";
VAL_ 1377 EstTimeofChrg_Lv2 2047 "SNA";
VAL_ 1377 HVBatCntctrStat 0 "Open" 1 "Precharging" 2 "Closed" 3 "Precharge_Failed" 4 "Precharge_Inhibited" 7 "SNA";
VAL_ 1377 MIL_OnRq_BPCM 0 "False" 1 "True";
VAL_ 1377 PrplsnSysAtv 0 "Not_Active" 1 "Active";
VAL_ 1377 Service_Battery_Recharge_FailSts 0 "Recharge_Fail" 1 "Recharge_Not_In_Fail";
VAL_ 1378 AirHtrCoreTemp 255 "SNA";
VAL_ 1378 AirHtrPCBTemp 255 "SNA";
VAL_ 1378 AirHtrPwrCnsAct 255 "SNA";
VAL_ 1378 FRfShVlvSts 0 "Open" 1 "Closed";
VAL_ 1378 HVBat_CoolantLvlLo 0 "False" 1 "True" 3 "SNA";
VAL_ 1378 HVBatCritCondT 0 "False" 1 "True";
VAL_ 1425 HVBatFull_Amp_Hr_Capacity 2047 "SNA";
VAL_ 1425 HVBatFull_Amp_Hr_Capacity_V 0 "Valid" 1 "Not_Valid";
VAL_ 1425 HVBatSOH 255 "SNA";
VAL_ 1425 HVBatSOHLow 255 "SNA";
VAL_ 654 HCPCoachDispV 0 "Valid" 1 "Invalid";
VAL_ 654 HCPOutputPwrV 0 "Valid" 1 "Invalid";
VAL_ 654 HCPPopUpMessage1 0 "False" 1 "True";
VAL_ 654 HCPPopUpMessage10 0 "False" 1 "True";
VAL_ 654 HCPPopUpMessage11 0 "False" 1 "True";
VAL_ 654 HCPPopUpMessage13 0 "False" 1 "True";
VAL_ 654 HCPPopUpMessage14 0 "False" 1 "True";
VAL_ 654 HCPPopUpMessage15 0 "False" 1 "True";
VAL_ 654 HCPPopUpMessage2 0 "False" 1 "True";
VAL_ 654 HCPPopUpMessage3 0 "False" 1 "True";
VAL_ 654 HCPPopUpMessage4 0 "False" 1 "True";
VAL_ 654 HCPPopUpMessage5 0 "False" 1 "True";
VAL_ 654 HCPPopUpMessage6 0 "False" 1 "True";
VAL_ 654 HCPPopUpMessage7 0 "False" 1 "True";
VAL_ 654 HCPPopUpMessage9 0 "False" 1 "True";
VAL_ 878 BatPwrUsageDisp_V 0 "Valid" 1 "Not_Valid";
VAL_ 878 HVACPwrUsageDisp_V 0 "Valid" 1 "Not_Valid";
VAL_ 878 HVBatSOCV_HCP 0 "Valid" 1 "Not_Valid";
VAL_ 878 MtrPwrUsageDisp_V 0 "Valid" 1 "Not_Valid";
VAL_ 1598 Est_Range_BEV 2047 "SNA";
VAL_ 1598 Est_Range_ChrgStopTime 2047 "SNA";
VAL_ 1598 EstTimeofChrg_DC_Fast_100 511 "SNA";
VAL_ 1598 EstTimeofChrg_DC_Fast_80 511 "SNA";
VAL_ 1465 Batt_CabinPriority1_Sts 0 "Battery charging on priority" 1 "Cabin conditioning on priority";
VAL_ 1465 ChargeUntilFull1_Sts 0 "Charge Until Full Not selected" 1 "Charge Until Full";
VAL_ 1465 Do_Not_Repeat1_Sts 0 "Repeat" 1 "Do Not Repeat";
VAL_ 1465 End_Time_Hr1_Sts 31 "SNA";
VAL_ 1465 End_Time_Min1_Sts 15 "SNA";
VAL_ 1465 SchCond_Time_Till_Dep 127 "SNA";
VAL_ 1465 Schedule_Confirmed1 0 "Disable" 1 "Enable";
VAL_ 1465 Schedule_Day1_Sts 0 "No Selection" 1 "M" 2 "T" 3 "TM" 4 "W" 5 "WM" 6 "WT" 7 "WTM" 8 "Th" 9 "ThM" 10 "ThT" 11 "ThTM" 12 "ThW" 13 "ThWM" 14 "ThWT" 15 "ThWTM" 16 "F" 17 "FM" 18 "FT" 19 "FTM" 20 "FW" 21 "FWM" 22 "FWT" 23 "FWTM" 24 "FTh" 25 "FThM" 26 "FThT" 27 "FThTM" 28 "FThW" 29 "FThWM" 30 "FThWT" 31 "FThWTM" 32 "S" 33 "SM" 34 "ST" 35 "STM" 36 "SW" 37 "SWM" 38 "SWT" 39 "SWTM" 40 "STh" 41 "SThM" 42 "SThT" 43 "SThTM" 44 "SThW" 45 "SThWM" 46 "SThWT" 47 "SThWTM" 48 "SF" 49 "SFM" 50 "SFT" 51 "SFTM" 52 "SFW" 53 "SFWM" 54 "SFWT" 55 "SFWTM" 56 "SFTh" 57 "SFThM" 58 "SFThT" 59 "SFThTM" 60 "SFThW" 61 "SFThWM" 62 "SFThWT" 63 "SFThWTM" 64 "Sa" 65 "SaM" 66 "SaT" 67 "SaTM" 68 "SaW" 69 "SaWM" 70 "SaWT" 71 "SaWTM" 72 "SaTh" 73 "SaThM" 74 "SaThT" 75 "SaThTM" 76 "SaThW" 77 "SaThWM" 78 "SaThWT" 79 "SaThWTM" 80 "SaF" 81 "SaFM" 82 "SaFT" 83 "SaFTM" 84 "SaFW" 85 "SaFWM" 86 "SaFWT" 87 "SaFWTM" 88 "SaFTh" 89 "SaFThM" 90 "SaFThT" 91 "SaFThTM" 92 "SaFThW" 93 "SaFThWM" 94 "SaFThWT" 95 "SaFThWTM" 96 "SaS" 97 "SaSM" 98 "SaST" 99 "SaSTM" 100 "SaSW" 101 "SaSWM" 102 "SaSWT" 103 "SaSWTM" 104 "SaSTh" 105 "SaSThM" 106 "SaSThT" 107 "SaSThTM" 108 "SaSThW" 109 "SaSThWM" 110 "SaSThWT" 111 "SaSThWTM" 112 "SaSF" 113 "SaSFM" 114 "SaSFT" 115 "SaSFTM" 116 "SaSFW" 117 "SaSFWM" 118 "SaSFWT" 119 "SaSFWTM" 120 "SaSFTh" 121 "SaSFThM" 122 "SaSFThT" 123 "SaSFThTM" 124 "SaSFThW" 125 "SaSFThWM" 126 "SaSFThWT" 127 "SaSFThWTM" 255 "SNA";
VAL_ 1465 Schedule_Type1_Sts 0 "No Selection" 1 "Departure Time" 2 "Charge Interval" 3 "SNA";
VAL_ 1465 Start_Time_Hr1_Sts 31 "SNA";
VAL_ 1465 Start_Time_Min1_Sts 15 "SNA";
